VERSION ""

NS_ :

BS_:

BU_: BMS_Controller NF_Controller NF_Controllers

BO_ 3221225472 VECTOR__INDEPENDENT_SIG_MSG: 0 Vector__XXX
 SG_ BATT_SwVerSubMinorApp m0 : 24|8@1+ (1,0) [0|255] ""  NF_Controller
 SG_ BATT_SwVerMinorApp m0 : 16|8@1+ (1,0) [0|255] ""  NF_Controller
 SG_ BATT_SwVerMajorApp m0 : 8|8@1+ (1,0) [0|255] ""  NF_Controller
 SG_ BATT_HwVerApp m0 : 32|8@1+ (1,0) [0|255] ""  NF_Controller
 SG_ BATT_SwVerAbsCusApp m0 : 40|8@1+ (1,0) [0|255] ""  NF_Controller
 SG_ BATT_SwVerAbsIntApp m0 : 48|8@1+ (1,0) [0|255] ""  NF_Controller
 SG_ BATT_SwVerSubMinorBl m1 : 24|8@1+ (1,0) [0|255] ""  NF_Controller
 SG_ BATT_SwVerMinorBl m1 : 16|8@1+ (1,0) [0|255] ""  NF_Controller
 SG_ BATT_SwVerMajorBl m1 : 8|8@1+ (1,0) [0|255] ""  NF_Controller
 SG_ BATT_HwVerBl m1 : 32|8@1+ (1,0) [0|255] ""  NF_Controller
 SG_ BATT_SwVerAbsCusBl m1 : 40|8@1+ (1,0) [0|255] ""  NF_Controller
 SG_ BATT_SwVerAbsIntBl m1 : 48|8@1+ (1,0) [0|255] ""  NF_Controller
 SG_ BATT_SwVerSubMinorCal m2 : 24|8@1+ (1,0) [0|255] ""  NF_Controller
 SG_ BATT_SwVerMinorCal m2 : 16|8@1+ (1,0) [0|255] ""  NF_Controller
 SG_ BATT_SwVerMajorCal m2 : 8|8@1+ (1,0) [0|255] ""  NF_Controller
 SG_ BATT_HwVerCal m2 : 32|8@1+ (1,0) [0|255] ""  NF_Controller
 SG_ BATT_SwVerAbsCusCal m2 : 40|8@1+ (1,0) [0|255] ""  NF_Controller
 SG_ BATT_SwVerAbsIntCal m2 : 48|8@1+ (1,0) [0|255] ""  NF_Controller
 SG_ multiplexorvr M : 0|2@1+ (1,0) [0|2] ""  NF_Controllers
 SG_ BATT_Cnc_SOC_String_MinV : 58|2@1+ (1,0) [0|3] ""  NF_Controller
 SG_ BATT_Cnc_SOC_String_MaxV : 56|2@1+ (1,0) [0|3] ""  NF_Controller
 SG_ BATT_Cnc_SOC_String_AvgV : 21|2@1+ (1,0) [0|3] ""  NF_Controller
 SG_ BATT_Cnc_Energy_SystemV : 37|2@1+ (1,0) [0|3] ""  NF_Controller
 SG_ BATT_Cnc_Energy_System : 40|16@1+ (0.01,0) [0|655.35] "KWh"  NF_Controller
 SG_ BATT_Cnc_SOC_String_Avg : 0|8@1+ (0.4,0) [0|100] "%"  NF_Controller
 SG_ BATT_Cnc_SOC_String_Max : 24|8@1+ (0.4,0) [0|100] "%"  NF_Controller
 SG_ BATT_Cnc_SOC_String_Max_StrId : 32|5@1+ (1,101) [101|124] "Index"  NF_Controller
 SG_ BATT_Cnc_SOC_String_Min : 8|8@1+ (0.4,0) [0|100] "%"  NF_Controller
 SG_ BATT_Cnc_SOC_String_Min_StrId : 16|5@1+ (1,101) [101|124] "Index"  NF_Controller
 SG_ BATT_01_inhibitionPyroFuse m0 : 11|1@1+ (1,0) [0|1] ""  NF_Controller
 SG_ BATT_01_inhibitionRegen m0 : 10|1@1+ (1,0) [0|1] ""  NF_Controller
 SG_ BATT_01_inhibitionFullPower m0 : 9|1@1+ (1,0) [0|1] ""  NF_Controller
 SG_ BATT_01_inhibitionRampDown m0 : 8|1@1+ (1,0) [0|1] ""  NF_Controller
 SG_ BATT_01_inhibitionDriveEntry m0 : 3|1@1+ (1,0) [0|1] ""  NF_Controller
 SG_ BATT_01_inhibitionDrive m0 : 2|1@1+ (1,0) [0|1] ""  NF_Controller
 SG_ BATT_01_inhibitionCharge m0 : 1|1@1+ (1,0) [0|1] ""  NF_Controller
 SG_ BATT_01_inhibitionChargeEntry m0 : 0|1@1+ (1,0) [0|1] ""  NF_Controller
 SG_ BATT_02_inhibitionPyroFuse m1 : 11|1@1+ (1,0) [0|1] ""  NF_Controller
 SG_ BATT_02_inhibitionRegen m1 : 10|1@1+ (1,0) [0|1] ""  NF_Controller
 SG_ BATT_02_inhibitionFullPower m1 : 9|1@1+ (1,0) [0|1] ""  NF_Controller
 SG_ BATT_02_inhibitionRampDown m1 : 8|1@1+ (1,0) [0|1] ""  NF_Controller
 SG_ BATT_02_inhibitionDriveEntry m1 : 3|1@1+ (1,0) [0|1] ""  NF_Controller
 SG_ BATT_02_inhibitionDrive m1 : 2|1@1+ (1,0) [0|1] ""  NF_Controller
 SG_ BATT_02_inhibitionCharge m1 : 1|1@1+ (1,0) [0|1] ""  NF_Controller
 SG_ BATT_02_inhibitionChargeEntry m1 : 0|1@1+ (1,0) [0|1] ""  NF_Controller
 SG_ BATT_03_inhibitionPyroFuse m2 : 11|1@1+ (1,0) [0|1] ""  NF_Controller
 SG_ BATT_03_inhibitionRegen m2 : 10|1@1+ (1,0) [0|1] ""  NF_Controller
 SG_ BATT_03_inhibitionFullPower m2 : 9|1@1+ (1,0) [0|1] ""  NF_Controller
 SG_ BATT_03_inhibitionRampDown m2 : 8|1@1+ (1,0) [0|1] ""  NF_Controller
 SG_ BATT_03_inhibitionDriveEntry m2 : 3|1@1+ (1,0) [0|1] ""  NF_Controller
 SG_ BATT_03_inhibitionDrive m2 : 2|1@1+ (1,0) [0|1] ""  NF_Controller
 SG_ BATT_03_inhibitionCharge m2 : 1|1@1+ (1,0) [0|1] ""  NF_Controller
 SG_ BATT_03_inhibitionChargeEntry m2 : 0|1@1+ (1,0) [0|1] ""  NF_Controller
 SG_ BATT_04_inhibitionPyroFuse m3 : 11|1@1+ (1,0) [0|1] ""  NF_Controller
 SG_ BATT_04_inhibitionRegen m3 : 10|1@1+ (1,0) [0|1] ""  NF_Controller
 SG_ BATT_04_inhibitionFullPower m3 : 9|1@1+ (1,0) [0|1] ""  NF_Controller
 SG_ BATT_04_inhibitionRampDown m3 : 8|1@1+ (1,0) [0|1] ""  NF_Controller
 SG_ BATT_04_inhibitionDriveEntry m3 : 3|1@1+ (1,0) [0|1] ""  NF_Controller
 SG_ BATT_04_inhibitionDrive m3 : 2|1@1+ (1,0) [0|1] ""  NF_Controller
 SG_ BATT_04_inhibitionCharge m3 : 1|1@1+ (1,0) [0|1] ""  NF_Controller
 SG_ BATT_04_inhibitionChargeEntry m3 : 0|1@1+ (1,0) [0|1] ""  NF_Controller
 SG_ BATT_05_inhibitionPyroFuse m4 : 11|1@1+ (1,0) [0|1] ""  NF_Controller
 SG_ BATT_05_inhibitionRegen m4 : 10|1@1+ (1,0) [0|1] ""  NF_Controller
 SG_ BATT_05_inhibitionFullPower m4 : 9|1@1+ (1,0) [0|1] ""  NF_Controller
 SG_ BATT_05_inhibitionRampDown m4 : 8|1@1+ (1,0) [0|1] ""  NF_Controller
 SG_ BATT_05_inhibitionDriveEntry m4 : 3|1@1+ (1,0) [0|1] ""  NF_Controller
 SG_ BATT_05_inhibitionDrive m4 : 2|1@1+ (1,0) [0|1] ""  NF_Controller
 SG_ BATT_05_inhibitionCharge m4 : 1|1@1+ (1,0) [0|1] ""  NF_Controller
 SG_ BATT_05_inhibitionChargeEntry m4 : 0|1@1+ (1,0) [0|1] ""  NF_Controller
 SG_ BATT_06_inhibitionPyroFuse m5 : 11|1@1+ (1,0) [0|1] ""  NF_Controller
 SG_ BATT_06_inhibitionRegen m5 : 10|1@1+ (1,0) [0|1] ""  NF_Controller
 SG_ BATT_06_inhibitionFullPower m5 : 9|1@1+ (1,0) [0|1] ""  NF_Controller
 SG_ BATT_06_inhibitionRampDown m5 : 8|1@1+ (1,0) [0|1] ""  NF_Controller
 SG_ BATT_06_inhibitionDriveEntry m5 : 3|1@1+ (1,0) [0|1] ""  NF_Controller
 SG_ BATT_06_inhibitionDrive m5 : 2|1@1+ (1,0) [0|1] ""  NF_Controller
 SG_ BATT_06_inhibitionCharge m5 : 1|1@1+ (1,0) [0|1] ""  NF_Controller
 SG_ BATT_06_inhibitionChargeEntry m5 : 0|1@1+ (1,0) [0|1] ""  NF_Controller
 SG_ BATT_07_inhibitionPyroFuse m6 : 11|1@1+ (1,0) [0|1] ""  NF_Controller
 SG_ BATT_07_inhibitionRegen m6 : 10|1@1+ (1,0) [0|1] ""  NF_Controller
 SG_ BATT_07_inhibitionFullPower m6 : 9|1@1+ (1,0) [0|1] ""  NF_Controller
 SG_ BATT_07_inhibitionRampDown m6 : 8|1@1+ (1,0) [0|1] ""  NF_Controller
 SG_ BATT_07_inhibitionDriveEntry m6 : 3|1@1+ (1,0) [0|1] ""  NF_Controller
 SG_ BATT_07_inhibitionDrive m6 : 2|1@1+ (1,0) [0|1] ""  NF_Controller
 SG_ BATT_07_inhibitionCharge m6 : 1|1@1+ (1,0) [0|1] ""  NF_Controller
 SG_ BATT_07_inhibitionChargeEntry m6 : 0|1@1+ (1,0) [0|1] ""  NF_Controller
 SG_ BATT_08_inhibitionPyroFuse m7 : 11|1@1+ (1,0) [0|1] ""  NF_Controller
 SG_ BATT_08_inhibitionRegen m7 : 10|1@1+ (1,0) [0|1] ""  NF_Controller
 SG_ BATT_08_inhibitionFullPower m7 : 9|1@1+ (1,0) [0|1] ""  NF_Controller
 SG_ BATT_08_inhibitionRampDown m7 : 8|1@1+ (1,0) [0|1] ""  NF_Controller
 SG_ BATT_08_inhibitionDriveEntry m7 : 3|1@1+ (1,0) [0|1] ""  NF_Controller
 SG_ BATT_08_inhibitionDrive m7 : 2|1@1+ (1,0) [0|1] ""  NF_Controller
 SG_ BATT_08_inhibitionCharge m7 : 1|1@1+ (1,0) [0|1] ""  NF_Controller
 SG_ BATT_08_inhibitionChargeEntry m7 : 0|1@1+ (1,0) [0|1] ""  NF_Controller
 SG_ BATT_09_inhibitionPyroFuse m8 : 11|1@1+ (1,0) [0|1] ""  NF_Controller
 SG_ BATT_09_inhibitionRegen m8 : 10|1@1+ (1,0) [0|1] ""  NF_Controller
 SG_ BATT_09_inhibitionFullPower m8 : 9|1@1+ (1,0) [0|1] ""  NF_Controller
 SG_ BATT_09_inhibitionRampDown m8 : 8|1@1+ (1,0) [0|1] ""  NF_Controller
 SG_ BATT_09_inhibitionDriveEntry m8 : 3|1@1+ (1,0) [0|1] ""  NF_Controller
 SG_ BATT_09_inhibitionDrive m8 : 2|1@1+ (1,0) [0|1] ""  NF_Controller
 SG_ BATT_09_inhibitionCharge m8 : 1|1@1+ (1,0) [0|1] ""  NF_Controller
 SG_ BATT_09_inhibitionChargeEntry m8 : 0|1@1+ (1,0) [0|1] ""  NF_Controller
 SG_ BATT_10_inhibitionPyroFuse m9 : 11|1@1+ (1,0) [0|1] ""  NF_Controller
 SG_ BATT_10_inhibitionRegen m9 : 10|1@1+ (1,0) [0|1] ""  NF_Controller
 SG_ BATT_10_inhibitionFullPower m9 : 9|1@1+ (1,0) [0|1] ""  NF_Controller
 SG_ BATT_10_inhibitionRampDown m9 : 8|1@1+ (1,0) [0|1] ""  NF_Controller
 SG_ BATT_10_inhibitionDriveEntry m9 : 3|1@1+ (1,0) [0|1] ""  NF_Controller
 SG_ BATT_10_inhibitionDrive m9 : 2|1@1+ (1,0) [0|1] ""  NF_Controller
 SG_ BATT_10_inhibitionCharge m9 : 1|1@1+ (1,0) [0|1] ""  NF_Controller
 SG_ BATT_10_inhibitionChargeEntry m9 : 0|1@1+ (1,0) [0|1] ""  NF_Controller
 SG_ BATT_packInhMux M : 4|4@1+ (1,0) [0|15] ""  NF_Controller
 SG_ BATT_inhibitionRegen : 6|1@1+ (1,0) [0|1] ""  NF_Controller
 SG_ BATT_inhibitionFullPower : 5|1@1+ (1,0) [0|1] ""  NF_Controller
 SG_ BATT_inhibitionRampDown : 4|1@1+ (1,0) [0|1] ""  NF_Controller
 SG_ BATT_inhibitionDriveEntry : 3|1@1+ (1,0) [0|1] ""  NF_Controller
 SG_ BATT_inhibitionDrive : 2|1@1+ (1,0) [0|1] ""  NF_Controller
 SG_ BATT_inhibitionCharge : 1|1@1+ (1,0) [0|1] ""  NF_Controller
 SG_ BATT_inhibitionChargeEntry : 0|1@1+ (1,0) [0|1] ""  NF_Controller
 SG_ BATT_HVILvoltageError : 2|2@1+ (1,0) [0|3] ""  NF_Controller
 SG_ BATT_HVILcurrentReturnError : 0|2@1+ (1,0) [0|3] ""  NF_Controller
 SG_ BATT_PosFcContWelded : 14|2@1+ (1,0) [0|3] ""  NF_Controller
 SG_ BATT_PosFcContStuckOpen : 12|2@1+ (1,0) [0|3] ""  NF_Controller
 SG_ BATT_NegFcContWelded : 10|2@1+ (1,0) [0|3] ""  NF_Controller
 SG_ BATT_NegFcContStuckOpen : 8|2@1+ (1,0) [0|3] ""  NF_Controller
 SG_ BATT_IsospiBreak : 22|2@1+ (1,0) [0|3] ""  NF_Controller
 SG_ BATT_IsolationIntFault : 20|2@1+ (1,0) [0|3] ""  NF_Controller
 SG_ BATT_IsolationExtFault : 18|2@1+ (1,0) [0|3] ""  NF_Controller
 SG_ BATT_event_12v_filter_error : 16|2@1+ (1,0) [0|3] ""  NF_Controller
 SG_ BATT_event_hall_eff_hi_rang_err : 30|2@1+ (1,0) [0|3] ""  NF_Controller
 SG_ BATT_event_brick_volt_sns_open : 28|2@1+ (1,0) [0|3] ""  NF_Controller
 SG_ BATT_event_5v_error : 26|2@1+ (1,0) [0|3] ""  NF_Controller
 SG_ BATT_event_3_3_hot_error : 24|2@1+ (1,0) [0|3] ""  NF_Controller
 SG_ BATT_event_12v_input_error : 38|2@1+ (1,0) [0|3] ""  NF_Controller
 SG_ BATT_event_1_25v_error : 36|2@1+ (1,0) [0|3] ""  NF_Controller
 SG_ BATT_event_shunt_MIA : 34|2@1+ (1,0) [0|3] ""  NF_Controller
 SG_ BATT_event_SBC_int_reg_error : 32|2@1+ (1,0) [0|3] ""  NF_Controller
 SG_ BATT_event_pos_3_3v_analog_error : 46|2@1+ (1,0) [0|3] ""  NF_Controller
 SG_ BATT_event_outlt_clnt_thrm_open : 44|2@1+ (1,0) [0|3] ""  NF_Controller
 SG_ BATT_event_neg_3_3_analog_error : 42|2@1+ (1,0) [0|3] ""  NF_Controller
 SG_ BATT_event_inlet_clnt_thrm_open : 40|2@1+ (1,0) [0|3] ""  NF_Controller
 SG_ BATT_event_hall_eff_lo_rang_err : 54|2@1+ (1,0) [0|3] ""  NF_Controller
 SG_ BATT_event_outlt_clnt_thrm_short : 52|2@1+ (1,0) [0|3] ""  NF_Controller
 SG_ BATT_event_inlet_clnt_thrm_short : 50|2@1+ (1,0) [0|3] ""  NF_Controller
 SG_ BATT_event_3_3v_error : 48|2@1+ (1,0) [0|3] ""  NF_Controller
 SG_ BATT_SenseBrickImpHigh : 2|2@1+ (1,0) [0|3] ""  NF_Controller
 SG_ BATT_AFEfault : 0|2@1+ (1,0) [0|3] ""  NF_Controller
 SG_ BATT_AFEerror : 14|2@1+ (1,0) [0|3] ""  NF_Controller
 SG_ BATT_HostMIA : 12|2@1+ (1,0) [0|3] ""  NF_Controller
 SG_ BATT_TempAmbientOverSev : 10|2@1+ (1,0) [0|3] ""  NF_Controller
 SG_ BATT_TempAmbientOverMod : 8|2@1+ (1,0) [0|3] ""  NF_Controller
 SG_ BATT_TempAmbientOverWar : 22|2@1+ (1,0) [0|3] ""  NF_Controller
 SG_ BATT_AbnormReset : 20|2@1+ (1,0) [0|3] ""  NF_Controller
 SG_ BATT_SenseAuxVoltError : 18|2@1+ (1,0) [0|3] ""  NF_Controller
 SG_ BATT_CalibrationInvalid : 16|2@1+ (1,0) [0|3] ""  NF_Controller
 SG_ BATT_TaskLockup : 30|2@1+ (1,0) [0|3] ""  NF_Controller
 SG_ BATT_RAMover : 28|2@1+ (1,0) [0|3] ""  NF_Controller
 SG_ BATT_BrickOverdischarge : 26|2@1+ (1,0) [0|3] ""  NF_Controller
 SG_ BATT_BrickOvercharge : 24|2@1+ (1,0) [0|3] ""  NF_Controller
 SG_ BATT_vBrickImbalance : 38|2@1+ (1,0) [0|3] ""  NF_Controller
 SG_ BATT_TempBrickImbalance : 36|2@1+ (1,0) [0|3] ""  NF_Controller
 SG_ BATT_CapPackLow : 34|2@1+ (1,0) [0|3] ""  NF_Controller
 SG_ BATT_rBrickHigh : 32|2@1+ (1,0) [0|3] ""  NF_Controller
 SG_ BATT_PowerpackInsuffErr : 46|2@1+ (1,0) [0|3] ""  NF_Controller
 SG_ BATT_BrickSoftShort : 44|2@1+ (1,0) [0|3] ""  NF_Controller
 SG_ BATT_chargeUndercurrent : 42|2@1+ (1,0) [0|3] ""  NF_Controller
 SG_ BATT_HVILcurrentSourceError : 40|2@1+ (1,0) [0|3] ""  NF_Controller
 SG_ BATT_SRS : 54|2@1+ (1,0) [0|3] ""  NF_Controller
 SG_ BATT_IsolationExtWar : 52|2@1+ (1,0) [0|3] ""  NF_Controller
 SG_ BATT_IsolationIntWar : 50|2@1+ (1,0) [0|3] ""  NF_Controller
 SG_ BATT_PyroFuseBlown : 48|2@1+ (1,0) [0|3] ""  NF_Controller
 SG_ BATT_vBrickUnderSev : 62|2@1+ (1,0) [0|3] ""  NF_Controller
 SG_ BATT_chargePrechargeTimeout : 60|2@1+ (1,0) [0|3] ""  NF_Controller
 SG_ BATT_ModuleThermistorShort : 58|2@1+ (1,0) [0|3] ""  NF_Controller
 SG_ BATT_ModuleThermistorBroken : 56|2@1+ (1,0) [0|3] ""  NF_Controller
 SG_ BATT_vBrickOverSev : 2|2@1+ (1,0) [0|3] ""  NF_Controller
 SG_ BATT_vBrickOverMod : 0|2@1+ (1,0) [0|3] ""  NF_Controller
 SG_ BATT_vBrickOverWar : 14|2@1+ (1,0) [0|3] ""  NF_Controller
 SG_ BATT_HostQuiet : 12|2@1+ (1,0) [0|3] ""  NF_Controller
 SG_ BATT_vBrickUnderMod : 10|2@1+ (1,0) [0|3] ""  NF_Controller
 SG_ BATT_vBrickUnderWar : 8|2@1+ (1,0) [0|3] ""  NF_Controller
 SG_ BATT_TempModuleOverSev : 22|2@1+ (1,0) [0|3] ""  NF_Controller
 SG_ BATT_TempModuleOverMod : 20|2@1+ (1,0) [0|3] ""  NF_Controller
 SG_ BATT_TempModuleOverWar : 18|2@1+ (1,0) [0|3] ""  NF_Controller
 SG_ BATT_TempModuleUnderSev : 16|2@1+ (1,0) [0|3] ""  NF_Controller
 SG_ BATT_TempModuleUnderMod : 30|2@1+ (1,0) [0|3] ""  NF_Controller
 SG_ BATT_TempModuleUnderWar : 28|2@1+ (1,0) [0|3] ""  NF_Controller
 SG_ BATT_iOvercharge : 26|2@1+ (1,0) [0|3] ""  NF_Controller
 SG_ BATT_iOverdischarge : 24|2@1+ (1,0) [0|3] ""  NF_Controller
 SG_ BATT_iOverHardware : 38|2@1+ (1,0) [0|3] ""  NF_Controller
 SG_ BATT_PosDcContStuckOpen : 36|2@1+ (1,0) [0|3] ""  NF_Controller
 SG_ BATT_PosDcContWelded : 34|2@1+ (1,0) [0|3] ""  NF_Controller
 SG_ BATT_NegDcContStuckOpen : 32|2@1+ (1,0) [0|3] ""  NF_Controller
 SG_ BATT_NegDcContWelded : 46|2@1+ (1,0) [0|3] ""  NF_Controller
 SG_ BATT_PrechgTooFast : 44|2@1+ (1,0) [0|3] ""  NF_Controller
 SG_ BATT_PrechgContWelded : 42|2@1+ (1,0) [0|3] ""  NF_Controller
 SG_ BATT_PrechgTimeout : 40|2@1+ (1,0) [0|3] ""  NF_Controller
 SG_ BATT_PrechgContStuckOpen : 54|2@1+ (1,0) [0|3] ""  NF_Controller
 SG_ BATT_ModuleImbalance : 52|2@1+ (1,0) [0|3] ""  NF_Controller
 SG_ BATT_ModuleMIA : 50|2@1+ (1,0) [0|3] ""  NF_Controller
 SG_ BATT_SensePackVoltError : 48|2@1+ (1,0) [0|3] ""  NF_Controller
 SG_ BATT_SenseLoadVoltError : 62|2@1+ (1,0) [0|3] ""  NF_Controller
 SG_ BATT_SenseShuntError : 60|2@1+ (1,0) [0|3] ""  NF_Controller
 SG_ BATT_SenseFcVoltErrorr : 58|2@1+ (1,0) [0|3] ""  NF_Controller
 SG_ BATT_SenseBrickOpen : 56|2@1+ (1,0) [0|3] ""  NF_Controller
 SG_ BATT_01_vBrickOverSev m0 : 2|2@1+ (1,0) [0|3] ""  NF_Controller
 SG_ BATT_01_vBrickOverMod m0 : 0|2@1+ (1,0) [0|3] ""  NF_Controller
 SG_ BATT_01_vBrickOverWar m0 : 14|2@1+ (1,0) [0|3] ""  NF_Controller
 SG_ BATT_01_HostQuiet m0 : 12|2@1+ (1,0) [0|3] ""  NF_Controller
 SG_ BATT_01_vBrickUnderMod m0 : 10|2@1+ (1,0) [0|3] ""  NF_Controller
 SG_ BATT_01_vBrickUnderWar m0 : 8|2@1+ (1,0) [0|3] ""  NF_Controller
 SG_ BATT_01_TempModuleOverSev m0 : 22|2@1+ (1,0) [0|3] ""  NF_Controller
 SG_ BATT_01_TempModuleOverMod m0 : 20|2@1+ (1,0) [0|3] ""  NF_Controller
 SG_ BATT_01_TempModuleOverWar m0 : 18|2@1+ (1,0) [0|3] ""  NF_Controller
 SG_ BATT_01_TempModuleUnderSev m0 : 16|2@1+ (1,0) [0|3] ""  NF_Controller
 SG_ BATT_01_TempModuleUnderMod m0 : 30|2@1+ (1,0) [0|3] ""  NF_Controller
 SG_ BATT_01_TempModuleUnderWar m0 : 28|2@1+ (1,0) [0|3] ""  NF_Controller
 SG_ BATT_01_iOvercharge m0 : 26|2@1+ (1,0) [0|3] ""  NF_Controller
 SG_ BATT_01_iOverdischarge m0 : 24|2@1+ (1,0) [0|3] ""  NF_Controller
 SG_ BATT_01_iOverHardware m0 : 38|2@1+ (1,0) [0|3] ""  NF_Controller
 SG_ BATT_01_PosDcContStuckOpen m0 : 36|2@1+ (1,0) [0|3] ""  NF_Controller
 SG_ BATT_01_PosDcContWelded m0 : 34|2@1+ (1,0) [0|3] ""  NF_Controller
 SG_ BATT_01_NegDcContStuckOpen m0 : 32|2@1+ (1,0) [0|3] ""  NF_Controller
 SG_ BATT_01_NegDcContWelded m0 : 46|2@1+ (1,0) [0|3] ""  NF_Controller
 SG_ BATT_01_PrechgTooFast m0 : 44|2@1+ (1,0) [0|3] ""  NF_Controller
 SG_ BATT_01_PrechgContWelded m0 : 42|2@1+ (1,0) [0|3] ""  NF_Controller
 SG_ BATT_01_PrechgTimeout m0 : 40|2@1+ (1,0) [0|3] ""  NF_Controller
 SG_ BATT_01_PrechgContStuckOpen m0 : 54|2@1+ (1,0) [0|3] ""  NF_Controller
 SG_ BATT_01_ModuleImbalance m0 : 52|2@1+ (1,0) [0|3] ""  NF_Controller
 SG_ BATT_01_ModuleMIA m0 : 50|2@1+ (1,0) [0|3] ""  NF_Controller
 SG_ BATT_01_SensePackVoltError m0 : 48|2@1+ (1,0) [0|3] ""  NF_Controller
 SG_ BATT_01_SenseLoadVoltError m0 : 62|2@1+ (1,0) [0|3] ""  NF_Controller
 SG_ BATT_01_SenseShuntError m0 : 60|2@1+ (1,0) [0|3] ""  NF_Controller
 SG_ BATT_01_SenseFcVoltErrorr m0 : 58|2@1+ (1,0) [0|3] ""  NF_Controller
 SG_ BATT_01_SenseBrickOpen m0 : 56|2@1+ (1,0) [0|3] ""  NF_Controller
 SG_ BATT_02_vBrickOverSev m1 : 2|2@1+ (1,0) [0|3] ""  NF_Controller
 SG_ BATT_02_vBrickOverMod m1 : 0|2@1+ (1,0) [0|3] ""  NF_Controller
 SG_ BATT_02_vBrickOverWar m1 : 14|2@1+ (1,0) [0|3] ""  NF_Controller
 SG_ BATT_02_HostQuiet m1 : 12|2@1+ (1,0) [0|3] ""  NF_Controller
 SG_ BATT_02_vBrickUnderMod m1 : 10|2@1+ (1,0) [0|3] ""  NF_Controller
 SG_ BATT_02_vBrickUnderWar m1 : 8|2@1+ (1,0) [0|3] ""  NF_Controller
 SG_ BATT_02_TempModuleOverSev m1 : 22|2@1+ (1,0) [0|3] ""  NF_Controller
 SG_ BATT_02_TempModuleOverMod m1 : 20|2@1+ (1,0) [0|3] ""  NF_Controller
 SG_ BATT_02_TempModuleOverWar m1 : 18|2@1+ (1,0) [0|3] ""  NF_Controller
 SG_ BATT_02_TempModuleUnderSev m1 : 16|2@1+ (1,0) [0|3] ""  NF_Controller
 SG_ BATT_02_TempModuleUnderMod m1 : 30|2@1+ (1,0) [0|3] ""  NF_Controller
 SG_ BATT_02_TempModuleUnderWar m1 : 28|2@1+ (1,0) [0|3] ""  NF_Controller
 SG_ BATT_02_iOvercharge m1 : 26|2@1+ (1,0) [0|3] ""  NF_Controller
 SG_ BATT_02_iOverdischarge m1 : 24|2@1+ (1,0) [0|3] ""  NF_Controller
 SG_ BATT_02_iOverHardware m1 : 38|2@1+ (1,0) [0|3] ""  NF_Controller
 SG_ BATT_02_PosDcContStuckOpen m1 : 36|2@1+ (1,0) [0|3] ""  NF_Controller
 SG_ BATT_02_PosDcContWelded m1 : 34|2@1+ (1,0) [0|3] ""  NF_Controller
 SG_ BATT_02_NegDcContStuckOpen m1 : 32|2@1+ (1,0) [0|3] ""  NF_Controller
 SG_ BATT_02_NegDcContWelded m1 : 46|2@1+ (1,0) [0|3] ""  NF_Controller
 SG_ BATT_02_PrechgTooFast m1 : 44|2@1+ (1,0) [0|3] ""  NF_Controller
 SG_ BATT_02_PrechgContWelded m1 : 42|2@1+ (1,0) [0|3] ""  NF_Controller
 SG_ BATT_02_PrechgTimeout m1 : 40|2@1+ (1,0) [0|3] ""  NF_Controller
 SG_ BATT_02_PrechgContStuckOpen m1 : 54|2@1+ (1,0) [0|3] ""  NF_Controller
 SG_ BATT_02_ModuleImbalance m1 : 52|2@1+ (1,0) [0|3] ""  NF_Controller
 SG_ BATT_02_ModuleMIA m1 : 50|2@1+ (1,0) [0|3] ""  NF_Controller
 SG_ BATT_02_SensePackVoltError m1 : 48|2@1+ (1,0) [0|3] ""  NF_Controller
 SG_ BATT_02_SenseLoadVoltError m1 : 62|2@1+ (1,0) [0|3] ""  NF_Controller
 SG_ BATT_02_SenseShuntError m1 : 60|2@1+ (1,0) [0|3] ""  NF_Controller
 SG_ BATT_02_SenseFcVoltErrorr m1 : 58|2@1+ (1,0) [0|3] ""  NF_Controller
 SG_ BATT_02_SenseBrickOpen m1 : 56|2@1+ (1,0) [0|3] ""  NF_Controller
 SG_ BATT_03_vBrickOverSev m2 : 2|2@1+ (1,0) [0|3] ""  NF_Controller
 SG_ BATT_03_vBrickOverMod m2 : 0|2@1+ (1,0) [0|3] ""  NF_Controller
 SG_ BATT_03_vBrickOverWar m2 : 14|2@1+ (1,0) [0|3] ""  NF_Controller
 SG_ BATT_03_HostQuiet m2 : 12|2@1+ (1,0) [0|3] ""  NF_Controller
 SG_ BATT_03_vBrickUnderMod m2 : 10|2@1+ (1,0) [0|3] ""  NF_Controller
 SG_ BATT_03_vBrickUnderWar m2 : 8|2@1+ (1,0) [0|3] ""  NF_Controller
 SG_ BATT_03_TempModuleOverSev m2 : 22|2@1+ (1,0) [0|3] ""  NF_Controller
 SG_ BATT_03_TempModuleOverMod m2 : 20|2@1+ (1,0) [0|3] ""  NF_Controller
 SG_ BATT_03_TempModuleOverWar m2 : 18|2@1+ (1,0) [0|3] ""  NF_Controller
 SG_ BATT_03_TempModuleUnderSev m2 : 16|2@1+ (1,0) [0|3] ""  NF_Controller
 SG_ BATT_03_TempModuleUnderMod m2 : 30|2@1+ (1,0) [0|3] ""  NF_Controller
 SG_ BATT_03_TempModuleUnderWar m2 : 28|2@1+ (1,0) [0|3] ""  NF_Controller
 SG_ BATT_03_iOvercharge m2 : 26|2@1+ (1,0) [0|3] ""  NF_Controller
 SG_ BATT_03_iOverdischarge m2 : 24|2@1+ (1,0) [0|3] ""  NF_Controller
 SG_ BATT_03_iOverHardware m2 : 38|2@1+ (1,0) [0|3] ""  NF_Controller
 SG_ BATT_03_PosDcContStuckOpen m2 : 36|2@1+ (1,0) [0|3] ""  NF_Controller
 SG_ BATT_03_PosDcContWelded m2 : 34|2@1+ (1,0) [0|3] ""  NF_Controller
 SG_ BATT_03_NegDcContStuckOpen m2 : 32|2@1+ (1,0) [0|3] ""  NF_Controller
 SG_ BATT_03_NegDcContWelded m2 : 46|2@1+ (1,0) [0|3] ""  NF_Controller
 SG_ BATT_03_PrechgTooFast m2 : 44|2@1+ (1,0) [0|3] ""  NF_Controller
 SG_ BATT_03_PrechgContWelded m2 : 42|2@1+ (1,0) [0|3] ""  NF_Controller
 SG_ BATT_03_PrechgTimeout m2 : 40|2@1+ (1,0) [0|3] ""  NF_Controller
 SG_ BATT_03_PrechgContStuckOpen m2 : 54|2@1+ (1,0) [0|3] ""  NF_Controller
 SG_ BATT_03_ModuleImbalance m2 : 52|2@1+ (1,0) [0|3] ""  NF_Controller
 SG_ BATT_03_ModuleMIA m2 : 50|2@1+ (1,0) [0|3] ""  NF_Controller
 SG_ BATT_03_SensePackVoltError m2 : 48|2@1+ (1,0) [0|3] ""  NF_Controller
 SG_ BATT_03_SenseLoadVoltError m2 : 62|2@1+ (1,0) [0|3] ""  NF_Controller
 SG_ BATT_03_SenseShuntError m2 : 60|2@1+ (1,0) [0|3] ""  NF_Controller
 SG_ BATT_03_SenseFcVoltErrorr m2 : 58|2@1+ (1,0) [0|3] ""  NF_Controller
 SG_ BATT_03_SenseBrickOpen m2 : 56|2@1+ (1,0) [0|3] ""  NF_Controller
 SG_ BATT_04_vBrickOverSev m3 : 2|2@1+ (1,0) [0|3] ""  NF_Controller
 SG_ BATT_04_vBrickOverMod m3 : 0|2@1+ (1,0) [0|3] ""  NF_Controller
 SG_ BATT_04_vBrickOverWar m3 : 14|2@1+ (1,0) [0|3] ""  NF_Controller
 SG_ BATT_04_HostQuiet m3 : 12|2@1+ (1,0) [0|3] ""  NF_Controller
 SG_ BATT_04_vBrickUnderMod m3 : 10|2@1+ (1,0) [0|3] ""  NF_Controller
 SG_ BATT_04_vBrickUnderWar m3 : 8|2@1+ (1,0) [0|3] ""  NF_Controller
 SG_ BATT_04_TempModuleOverSev m3 : 22|2@1+ (1,0) [0|3] ""  NF_Controller
 SG_ BATT_04_TempModuleOverMod m3 : 20|2@1+ (1,0) [0|3] ""  NF_Controller
 SG_ BATT_04_TempModuleOverWar m3 : 18|2@1+ (1,0) [0|3] ""  NF_Controller
 SG_ BATT_04_TempModuleUnderSev m3 : 16|2@1+ (1,0) [0|3] ""  NF_Controller
 SG_ BATT_04_TempModuleUnderMod m3 : 30|2@1+ (1,0) [0|3] ""  NF_Controller
 SG_ BATT_04_TempModuleUnderWar m3 : 28|2@1+ (1,0) [0|3] ""  NF_Controller
 SG_ BATT_04_iOvercharge m3 : 26|2@1+ (1,0) [0|3] ""  NF_Controller
 SG_ BATT_04_iOverdischarge m3 : 24|2@1+ (1,0) [0|3] ""  NF_Controller
 SG_ BATT_04_iOverHardware m3 : 38|2@1+ (1,0) [0|3] ""  NF_Controller
 SG_ BATT_04_PosDcContStuckOpen m3 : 36|2@1+ (1,0) [0|3] ""  NF_Controller
 SG_ BATT_04_PosDcContWelded m3 : 34|2@1+ (1,0) [0|3] ""  NF_Controller
 SG_ BATT_04_NegDcContStuckOpen m3 : 32|2@1+ (1,0) [0|3] ""  NF_Controller
 SG_ BATT_04_NegDcContWelded m3 : 46|2@1+ (1,0) [0|3] ""  NF_Controller
 SG_ BATT_04_PrechgTooFast m3 : 44|2@1+ (1,0) [0|3] ""  NF_Controller
 SG_ BATT_04_PrechgContWelded m3 : 42|2@1+ (1,0) [0|3] ""  NF_Controller
 SG_ BATT_04_PrechgTimeout m3 : 40|2@1+ (1,0) [0|3] ""  NF_Controller
 SG_ BATT_04_PrechgContStuckOpen m3 : 54|2@1+ (1,0) [0|3] ""  NF_Controller
 SG_ BATT_04_ModuleImbalance m3 : 52|2@1+ (1,0) [0|3] ""  NF_Controller
 SG_ BATT_04_ModuleMIA m3 : 50|2@1+ (1,0) [0|3] ""  NF_Controller
 SG_ BATT_04_SensePackVoltError m3 : 48|2@1+ (1,0) [0|3] ""  NF_Controller
 SG_ BATT_04_SenseLoadVoltError m3 : 62|2@1+ (1,0) [0|3] ""  NF_Controller
 SG_ BATT_04_SenseShuntError m3 : 60|2@1+ (1,0) [0|3] ""  NF_Controller
 SG_ BATT_04_SenseFcVoltErrorr m3 : 58|2@1+ (1,0) [0|3] ""  NF_Controller
 SG_ BATT_04_SenseBrickOpen m3 : 56|2@1+ (1,0) [0|3] ""  NF_Controller
 SG_ BATT_05_vBrickOverSev m4 : 2|2@1+ (1,0) [0|3] ""  NF_Controller
 SG_ BATT_05_vBrickOverMod m4 : 0|2@1+ (1,0) [0|3] ""  NF_Controller
 SG_ BATT_05_vBrickOverWar m4 : 14|2@1+ (1,0) [0|3] ""  NF_Controller
 SG_ BATT_05_HostQuiet m4 : 12|2@1+ (1,0) [0|3] ""  NF_Controller
 SG_ BATT_05_vBrickUnderMod m4 : 10|2@1+ (1,0) [0|3] ""  NF_Controller
 SG_ BATT_05_vBrickUnderWar m4 : 8|2@1+ (1,0) [0|3] ""  NF_Controller
 SG_ BATT_05_TempModuleOverSev m4 : 22|2@1+ (1,0) [0|3] ""  NF_Controller
 SG_ BATT_05_TempModuleOverMod m4 : 20|2@1+ (1,0) [0|3] ""  NF_Controller
 SG_ BATT_05_TempModuleOverWar m4 : 18|2@1+ (1,0) [0|3] ""  NF_Controller
 SG_ BATT_05_TempModuleUnderSev m4 : 16|2@1+ (1,0) [0|3] ""  NF_Controller
 SG_ BATT_05_TempModuleUnderMod m4 : 30|2@1+ (1,0) [0|3] ""  NF_Controller
 SG_ BATT_05_TempModuleUnderWar m4 : 28|2@1+ (1,0) [0|3] ""  NF_Controller
 SG_ BATT_05_iOvercharge m4 : 26|2@1+ (1,0) [0|3] ""  NF_Controller
 SG_ BATT_05_iOverdischarge m4 : 24|2@1+ (1,0) [0|3] ""  NF_Controller
 SG_ BATT_05_iOverHardware m4 : 38|2@1+ (1,0) [0|3] ""  NF_Controller
 SG_ BATT_05_PosDcContStuckOpen m4 : 36|2@1+ (1,0) [0|3] ""  NF_Controller
 SG_ BATT_05_PosDcContWelded m4 : 34|2@1+ (1,0) [0|3] ""  NF_Controller
 SG_ BATT_05_NegDcContStuckOpen m4 : 32|2@1+ (1,0) [0|3] ""  NF_Controller
 SG_ BATT_05_NegDcContWelded m4 : 46|2@1+ (1,0) [0|3] ""  NF_Controller
 SG_ BATT_05_PrechgTooFast m4 : 44|2@1+ (1,0) [0|3] ""  NF_Controller
 SG_ BATT_05_PrechgContWelded m4 : 42|2@1+ (1,0) [0|3] ""  NF_Controller
 SG_ BATT_05_PrechgTimeout m4 : 40|2@1+ (1,0) [0|3] ""  NF_Controller
 SG_ BATT_05_PrechgContStuckOpen m4 : 54|2@1+ (1,0) [0|3] ""  NF_Controller
 SG_ BATT_05_ModuleImbalance m4 : 52|2@1+ (1,0) [0|3] ""  NF_Controller
 SG_ BATT_05_ModuleMIA m4 : 50|2@1+ (1,0) [0|3] ""  NF_Controller
 SG_ BATT_05_SensePackVoltError m4 : 48|2@1+ (1,0) [0|3] ""  NF_Controller
 SG_ BATT_05_SenseLoadVoltError m4 : 62|2@1+ (1,0) [0|3] ""  NF_Controller
 SG_ BATT_05_SenseShuntError m4 : 60|2@1+ (1,0) [0|3] ""  NF_Controller
 SG_ BATT_05_SenseFcVoltErrorr m4 : 58|2@1+ (1,0) [0|3] ""  NF_Controller
 SG_ BATT_05_SenseBrickOpen m4 : 56|2@1+ (1,0) [0|3] ""  NF_Controller
 SG_ BATT_06_vBrickOverSev m5 : 2|2@1+ (1,0) [0|3] ""  NF_Controller
 SG_ BATT_06_vBrickOverMod m5 : 0|2@1+ (1,0) [0|3] ""  NF_Controller
 SG_ BATT_06_vBrickOverWar m5 : 14|2@1+ (1,0) [0|3] ""  NF_Controller
 SG_ BATT_06_HostQuiet m5 : 12|2@1+ (1,0) [0|3] ""  NF_Controller
 SG_ BATT_06_vBrickUnderMod m5 : 10|2@1+ (1,0) [0|3] ""  NF_Controller
 SG_ BATT_06_vBrickUnderWar m5 : 8|2@1+ (1,0) [0|3] ""  NF_Controller
 SG_ BATT_06_TempModuleOverSev m5 : 22|2@1+ (1,0) [0|3] ""  NF_Controller
 SG_ BATT_06_TempModuleOverMod m5 : 20|2@1+ (1,0) [0|3] ""  NF_Controller
 SG_ BATT_06_TempModuleOverWar m5 : 18|2@1+ (1,0) [0|3] ""  NF_Controller
 SG_ BATT_06_TempModuleUnderSev m5 : 16|2@1+ (1,0) [0|3] ""  NF_Controller
 SG_ BATT_06_TempModuleUnderMod m5 : 30|2@1+ (1,0) [0|3] ""  NF_Controller
 SG_ BATT_06_TempModuleUnderWar m5 : 28|2@1+ (1,0) [0|3] ""  NF_Controller
 SG_ BATT_06_iOvercharge m5 : 26|2@1+ (1,0) [0|3] ""  NF_Controller
 SG_ BATT_06_iOverdischarge m5 : 24|2@1+ (1,0) [0|3] ""  NF_Controller
 SG_ BATT_06_iOverHardware m5 : 38|2@1+ (1,0) [0|3] ""  NF_Controller
 SG_ BATT_06_PosDcContStuckOpen m5 : 36|2@1+ (1,0) [0|3] ""  NF_Controller
 SG_ BATT_06_PosDcContWelded m5 : 34|2@1+ (1,0) [0|3] ""  NF_Controller
 SG_ BATT_06_NegDcContStuckOpen m5 : 32|2@1+ (1,0) [0|3] ""  NF_Controller
 SG_ BATT_06_NegDcContWelded m5 : 46|2@1+ (1,0) [0|3] ""  NF_Controller
 SG_ BATT_06_PrechgTooFast m5 : 44|2@1+ (1,0) [0|3] ""  NF_Controller
 SG_ BATT_06_PrechgContWelded m5 : 42|2@1+ (1,0) [0|3] ""  NF_Controller
 SG_ BATT_06_PrechgTimeout m5 : 40|2@1+ (1,0) [0|3] ""  NF_Controller
 SG_ BATT_06_PrechgContStuckOpen m5 : 54|2@1+ (1,0) [0|3] ""  NF_Controller
 SG_ BATT_06_ModuleImbalance m5 : 52|2@1+ (1,0) [0|3] ""  NF_Controller
 SG_ BATT_06_ModuleMIA m5 : 50|2@1+ (1,0) [0|3] ""  NF_Controller
 SG_ BATT_06_SensePackVoltError m5 : 48|2@1+ (1,0) [0|3] ""  NF_Controller
 SG_ BATT_06_SenseLoadVoltError m5 : 62|2@1+ (1,0) [0|3] ""  NF_Controller
 SG_ BATT_06_SenseShuntError m5 : 60|2@1+ (1,0) [0|3] ""  NF_Controller
 SG_ BATT_06_SenseFcVoltErrorr m5 : 58|2@1+ (1,0) [0|3] ""  NF_Controller
 SG_ BATT_06_SenseBrickOpen m5 : 56|2@1+ (1,0) [0|3] ""  NF_Controller
 SG_ BATT_07_vBrickOverSev m6 : 2|2@1+ (1,0) [0|3] ""  NF_Controller
 SG_ BATT_07_vBrickOverMod m6 : 0|2@1+ (1,0) [0|3] ""  NF_Controller
 SG_ BATT_07_vBrickOverWar m6 : 14|2@1+ (1,0) [0|3] ""  NF_Controller
 SG_ BATT_07_HostQuiet m6 : 12|2@1+ (1,0) [0|3] ""  NF_Controller
 SG_ BATT_07_vBrickUnderMod m6 : 10|2@1+ (1,0) [0|3] ""  NF_Controller
 SG_ BATT_07_vBrickUnderWar m6 : 8|2@1+ (1,0) [0|3] ""  NF_Controller
 SG_ BATT_07_TempModuleOverSev m6 : 22|2@1+ (1,0) [0|3] ""  NF_Controller
 SG_ BATT_07_TempModuleOverMod m6 : 20|2@1+ (1,0) [0|3] ""  NF_Controller
 SG_ BATT_07_TempModuleOverWar m6 : 18|2@1+ (1,0) [0|3] ""  NF_Controller
 SG_ BATT_07_TempModuleUnderSev m6 : 16|2@1+ (1,0) [0|3] ""  NF_Controller
 SG_ BATT_07_TempModuleUnderMod m6 : 30|2@1+ (1,0) [0|3] ""  NF_Controller
 SG_ BATT_07_TempModuleUnderWar m6 : 28|2@1+ (1,0) [0|3] ""  NF_Controller
 SG_ BATT_07_iOvercharge m6 : 26|2@1+ (1,0) [0|3] ""  NF_Controller
 SG_ BATT_07_iOverdischarge m6 : 24|2@1+ (1,0) [0|3] ""  NF_Controller
 SG_ BATT_07_iOverHardware m6 : 38|2@1+ (1,0) [0|3] ""  NF_Controller
 SG_ BATT_07_PosDcContStuckOpen m6 : 36|2@1+ (1,0) [0|3] ""  NF_Controller
 SG_ BATT_07_PosDcContWelded m6 : 34|2@1+ (1,0) [0|3] ""  NF_Controller
 SG_ BATT_07_NegDcContStuckOpen m6 : 32|2@1+ (1,0) [0|3] ""  NF_Controller
 SG_ BATT_07_NegDcContWelded m6 : 46|2@1+ (1,0) [0|3] ""  NF_Controller
 SG_ BATT_07_PrechgTooFast m6 : 44|2@1+ (1,0) [0|3] ""  NF_Controller
 SG_ BATT_07_PrechgContWelded m6 : 42|2@1+ (1,0) [0|3] ""  NF_Controller
 SG_ BATT_07_PrechgTimeout m6 : 40|2@1+ (1,0) [0|3] ""  NF_Controller
 SG_ BATT_07_PrechgContStuckOpen m6 : 54|2@1+ (1,0) [0|3] ""  NF_Controller
 SG_ BATT_07_ModuleImbalance m6 : 52|2@1+ (1,0) [0|3] ""  NF_Controller
 SG_ BATT_07_ModuleMIA m6 : 50|2@1+ (1,0) [0|3] ""  NF_Controller
 SG_ BATT_07_SensePackVoltError m6 : 48|2@1+ (1,0) [0|3] ""  NF_Controller
 SG_ BATT_07_SenseLoadVoltError m6 : 62|2@1+ (1,0) [0|3] ""  NF_Controller
 SG_ BATT_07_SenseShuntError m6 : 60|2@1+ (1,0) [0|3] ""  NF_Controller
 SG_ BATT_07_SenseFcVoltErrorr m6 : 58|2@1+ (1,0) [0|3] ""  NF_Controller
 SG_ BATT_07_SenseBrickOpen m6 : 56|2@1+ (1,0) [0|3] ""  NF_Controller
 SG_ BATT_08_vBrickOverSev m7 : 2|2@1+ (1,0) [0|3] ""  NF_Controller
 SG_ BATT_08_vBrickOverMod m7 : 0|2@1+ (1,0) [0|3] ""  NF_Controller
 SG_ BATT_08_vBrickOverWar m7 : 14|2@1+ (1,0) [0|3] ""  NF_Controller
 SG_ BATT_08_HostQuiet m7 : 12|2@1+ (1,0) [0|3] ""  NF_Controller
 SG_ BATT_08_vBrickUnderMod m7 : 10|2@1+ (1,0) [0|3] ""  NF_Controller
 SG_ BATT_08_vBrickUnderWar m7 : 8|2@1+ (1,0) [0|3] ""  NF_Controller
 SG_ BATT_08_TempModuleOverSev m7 : 22|2@1+ (1,0) [0|3] ""  NF_Controller
 SG_ BATT_08_TempModuleOverMod m7 : 20|2@1+ (1,0) [0|3] ""  NF_Controller
 SG_ BATT_08_TempModuleOverWar m7 : 18|2@1+ (1,0) [0|3] ""  NF_Controller
 SG_ BATT_08_TempModuleUnderSev m7 : 16|2@1+ (1,0) [0|3] ""  NF_Controller
 SG_ BATT_08_TempModuleUnderMod m7 : 30|2@1+ (1,0) [0|3] ""  NF_Controller
 SG_ BATT_08_TempModuleUnderWar m7 : 28|2@1+ (1,0) [0|3] ""  NF_Controller
 SG_ BATT_08_iOvercharge m7 : 26|2@1+ (1,0) [0|3] ""  NF_Controller
 SG_ BATT_08_iOverdischarge m7 : 24|2@1+ (1,0) [0|3] ""  NF_Controller
 SG_ BATT_08_iOverHardware m7 : 38|2@1+ (1,0) [0|3] ""  NF_Controller
 SG_ BATT_08_PosDcContStuckOpen m7 : 36|2@1+ (1,0) [0|3] ""  NF_Controller
 SG_ BATT_08_PosDcContWelded m7 : 34|2@1+ (1,0) [0|3] ""  NF_Controller
 SG_ BATT_08_NegDcContStuckOpen m7 : 32|2@1+ (1,0) [0|3] ""  NF_Controller
 SG_ BATT_08_NegDcContWelded m7 : 46|2@1+ (1,0) [0|3] ""  NF_Controller
 SG_ BATT_08_PrechgTooFast m7 : 44|2@1+ (1,0) [0|3] ""  NF_Controller
 SG_ BATT_08_PrechgContWelded m7 : 42|2@1+ (1,0) [0|3] ""  NF_Controller
 SG_ BATT_08_PrechgTimeout m7 : 40|2@1+ (1,0) [0|3] ""  NF_Controller
 SG_ BATT_08_PrechgContStuckOpen m7 : 54|2@1+ (1,0) [0|3] ""  NF_Controller
 SG_ BATT_08_ModuleImbalance m7 : 52|2@1+ (1,0) [0|3] ""  NF_Controller
 SG_ BATT_08_ModuleMIA m7 : 50|2@1+ (1,0) [0|3] ""  NF_Controller
 SG_ BATT_08_SensePackVoltError m7 : 48|2@1+ (1,0) [0|3] ""  NF_Controller
 SG_ BATT_08_SenseLoadVoltError m7 : 62|2@1+ (1,0) [0|3] ""  NF_Controller
 SG_ BATT_08_SenseShuntError m7 : 60|2@1+ (1,0) [0|3] ""  NF_Controller
 SG_ BATT_08_SenseFcVoltErrorr m7 : 58|2@1+ (1,0) [0|3] ""  NF_Controller
 SG_ BATT_08_SenseBrickOpen m7 : 56|2@1+ (1,0) [0|3] ""  NF_Controller
 SG_ BATT_09_vBrickOverSev m8 : 2|2@1+ (1,0) [0|3] ""  NF_Controller
 SG_ BATT_09_vBrickOverMod m8 : 0|2@1+ (1,0) [0|3] ""  NF_Controller
 SG_ BATT_09_vBrickOverWar m8 : 14|2@1+ (1,0) [0|3] ""  NF_Controller
 SG_ BATT_09_HostQuiet m8 : 12|2@1+ (1,0) [0|3] ""  NF_Controller
 SG_ BATT_09_vBrickUnderMod m8 : 10|2@1+ (1,0) [0|3] ""  NF_Controller
 SG_ BATT_09_vBrickUnderWar m8 : 8|2@1+ (1,0) [0|3] ""  NF_Controller
 SG_ BATT_09_TempModuleOverSev m8 : 22|2@1+ (1,0) [0|3] ""  NF_Controller
 SG_ BATT_09_TempModuleOverMod m8 : 20|2@1+ (1,0) [0|3] ""  NF_Controller
 SG_ BATT_09_TempModuleOverWar m8 : 18|2@1+ (1,0) [0|3] ""  NF_Controller
 SG_ BATT_09_TempModuleUnderSev m8 : 16|2@1+ (1,0) [0|3] ""  NF_Controller
 SG_ BATT_09_TempModuleUnderMod m8 : 30|2@1+ (1,0) [0|3] ""  NF_Controller
 SG_ BATT_09_TempModuleUnderWar m8 : 28|2@1+ (1,0) [0|3] ""  NF_Controller
 SG_ BATT_09_iOvercharge m8 : 26|2@1+ (1,0) [0|3] ""  NF_Controller
 SG_ BATT_09_iOverdischarge m8 : 24|2@1+ (1,0) [0|3] ""  NF_Controller
 SG_ BATT_09_iOverHardware m8 : 38|2@1+ (1,0) [0|3] ""  NF_Controller
 SG_ BATT_09_PosDcContStuckOpen m8 : 36|2@1+ (1,0) [0|3] ""  NF_Controller
 SG_ BATT_09_PosDcContWelded m8 : 34|2@1+ (1,0) [0|3] ""  NF_Controller
 SG_ BATT_09_NegDcContStuckOpen m8 : 32|2@1+ (1,0) [0|3] ""  NF_Controller
 SG_ BATT_09_NegDcContWelded m8 : 46|2@1+ (1,0) [0|3] ""  NF_Controller
 SG_ BATT_09_PrechgTooFast m8 : 44|2@1+ (1,0) [0|3] ""  NF_Controller
 SG_ BATT_09_PrechgContWelded m8 : 42|2@1+ (1,0) [0|3] ""  NF_Controller
 SG_ BATT_09_PrechgTimeout m8 : 40|2@1+ (1,0) [0|3] ""  NF_Controller
 SG_ BATT_09_PrechgContStuckOpen m8 : 54|2@1+ (1,0) [0|3] ""  NF_Controller
 SG_ BATT_09_ModuleImbalance m8 : 52|2@1+ (1,0) [0|3] ""  NF_Controller
 SG_ BATT_09_ModuleMIA m8 : 50|2@1+ (1,0) [0|3] ""  NF_Controller
 SG_ BATT_09_SensePackVoltError m8 : 48|2@1+ (1,0) [0|3] ""  NF_Controller
 SG_ BATT_09_SenseLoadVoltError m8 : 62|2@1+ (1,0) [0|3] ""  NF_Controller
 SG_ BATT_09_SenseShuntError m8 : 60|2@1+ (1,0) [0|3] ""  NF_Controller
 SG_ BATT_09_SenseFcVoltErrorr m8 : 58|2@1+ (1,0) [0|3] ""  NF_Controller
 SG_ BATT_09_SenseBrickOpen m8 : 56|2@1+ (1,0) [0|3] ""  NF_Controller
 SG_ BATT_10_vBrickOverSev m9 : 2|2@1+ (1,0) [0|3] ""  NF_Controller
 SG_ BATT_10_vBrickOverMod m9 : 0|2@1+ (1,0) [0|3] ""  NF_Controller
 SG_ BATT_10_vBrickOverWar m9 : 14|2@1+ (1,0) [0|3] ""  NF_Controller
 SG_ BATT_10_HostQuiet m9 : 12|2@1+ (1,0) [0|3] ""  NF_Controller
 SG_ BATT_10_vBrickUnderMod m9 : 10|2@1+ (1,0) [0|3] ""  NF_Controller
 SG_ BATT_10_vBrickUnderWar m9 : 8|2@1+ (1,0) [0|3] ""  NF_Controller
 SG_ BATT_10_TempModuleOverSev m9 : 22|2@1+ (1,0) [0|3] ""  NF_Controller
 SG_ BATT_10_TempModuleOverMod m9 : 20|2@1+ (1,0) [0|3] ""  NF_Controller
 SG_ BATT_10_TempModuleOverWar m9 : 18|2@1+ (1,0) [0|3] ""  NF_Controller
 SG_ BATT_10_TempModuleUnderSev m9 : 16|2@1+ (1,0) [0|3] ""  NF_Controller
 SG_ BATT_10_TempModuleUnderMod m9 : 30|2@1+ (1,0) [0|3] ""  NF_Controller
 SG_ BATT_10_TempModuleUnderWar m9 : 28|2@1+ (1,0) [0|3] ""  NF_Controller
 SG_ BATT_10_iOvercharge m9 : 26|2@1+ (1,0) [0|3] ""  NF_Controller
 SG_ BATT_10_iOverdischarge m9 : 24|2@1+ (1,0) [0|3] ""  NF_Controller
 SG_ BATT_10_iOverHardware m9 : 38|2@1+ (1,0) [0|3] ""  NF_Controller
 SG_ BATT_10_PosDcContStuckOpen m9 : 36|2@1+ (1,0) [0|3] ""  NF_Controller
 SG_ BATT_10_PosDcContWelded m9 : 34|2@1+ (1,0) [0|3] ""  NF_Controller
 SG_ BATT_10_NegDcContStuckOpen m9 : 32|2@1+ (1,0) [0|3] ""  NF_Controller
 SG_ BATT_10_NegDcContWelded m9 : 46|2@1+ (1,0) [0|3] ""  NF_Controller
 SG_ BATT_10_PrechgTooFast m9 : 44|2@1+ (1,0) [0|3] ""  NF_Controller
 SG_ BATT_10_PrechgContWelded m9 : 42|2@1+ (1,0) [0|3] ""  NF_Controller
 SG_ BATT_10_PrechgTimeout m9 : 40|2@1+ (1,0) [0|3] ""  NF_Controller
 SG_ BATT_10_PrechgContStuckOpen m9 : 54|2@1+ (1,0) [0|3] ""  NF_Controller
 SG_ BATT_10_ModuleImbalance m9 : 52|2@1+ (1,0) [0|3] ""  NF_Controller
 SG_ BATT_10_ModuleMIA m9 : 50|2@1+ (1,0) [0|3] ""  NF_Controller
 SG_ BATT_10_SensePackVoltError m9 : 48|2@1+ (1,0) [0|3] ""  NF_Controller
 SG_ BATT_10_SenseLoadVoltError m9 : 62|2@1+ (1,0) [0|3] ""  NF_Controller
 SG_ BATT_10_SenseShuntError m9 : 60|2@1+ (1,0) [0|3] ""  NF_Controller
 SG_ BATT_10_SenseFcVoltErrorr m9 : 58|2@1+ (1,0) [0|3] ""  NF_Controller
 SG_ BATT_10_SenseBrickOpen m9 : 56|2@1+ (1,0) [0|3] ""  NF_Controller
 SG_ BATT_11_vBrickOverSev m10 : 2|2@1+ (1,0) [0|3] ""  NF_Controller
 SG_ BATT_11_vBrickOverMod m10 : 0|2@1+ (1,0) [0|3] ""  NF_Controller
 SG_ BATT_11_vBrickOverWar m10 : 14|2@1+ (1,0) [0|3] ""  NF_Controller
 SG_ BATT_11_HostQuiet m10 : 12|2@1+ (1,0) [0|3] ""  NF_Controller
 SG_ BATT_11_vBrickUnderMod m10 : 10|2@1+ (1,0) [0|3] ""  NF_Controller
 SG_ BATT_11_vBrickUnderWar m10 : 8|2@1+ (1,0) [0|3] ""  NF_Controller
 SG_ BATT_11_TempModuleOverSev m10 : 22|2@1+ (1,0) [0|3] ""  NF_Controller
 SG_ BATT_11_TempModuleOverMod m10 : 20|2@1+ (1,0) [0|3] ""  NF_Controller
 SG_ BATT_11_TempModuleOverWar m10 : 18|2@1+ (1,0) [0|3] ""  NF_Controller
 SG_ BATT_11_TempModuleUnderSev m10 : 16|2@1+ (1,0) [0|3] ""  NF_Controller
 SG_ BATT_11_TempModuleUnderMod m10 : 30|2@1+ (1,0) [0|3] ""  NF_Controller
 SG_ BATT_11_TempModuleUnderWar m10 : 28|2@1+ (1,0) [0|3] ""  NF_Controller
 SG_ BATT_11_iOvercharge m10 : 26|2@1+ (1,0) [0|3] ""  NF_Controller
 SG_ BATT_11_iOverdischarge m10 : 24|2@1+ (1,0) [0|3] ""  NF_Controller
 SG_ BATT_11_iOverHardware m10 : 38|2@1+ (1,0) [0|3] ""  NF_Controller
 SG_ BATT_11_PosDcContStuckOpen m10 : 36|2@1+ (1,0) [0|3] ""  NF_Controller
 SG_ BATT_11_PosDcContWelded m10 : 34|2@1+ (1,0) [0|3] ""  NF_Controller
 SG_ BATT_11_NegDcContStuckOpen m10 : 32|2@1+ (1,0) [0|3] ""  NF_Controller
 SG_ BATT_11_NegDcContWelded m10 : 46|2@1+ (1,0) [0|3] ""  NF_Controller
 SG_ BATT_11_PrechgTooFast m10 : 44|2@1+ (1,0) [0|3] ""  NF_Controller
 SG_ BATT_11_PrechgContWelded m10 : 42|2@1+ (1,0) [0|3] ""  NF_Controller
 SG_ BATT_11_PrechgTimeout m10 : 40|2@1+ (1,0) [0|3] ""  NF_Controller
 SG_ BATT_11_PrechgContStuckOpen m10 : 54|2@1+ (1,0) [0|3] ""  NF_Controller
 SG_ BATT_11_ModuleImbalance m10 : 52|2@1+ (1,0) [0|3] ""  NF_Controller
 SG_ BATT_11_ModuleMIA m10 : 50|2@1+ (1,0) [0|3] ""  NF_Controller
 SG_ BATT_11_SensePackVoltError m10 : 48|2@1+ (1,0) [0|3] ""  NF_Controller
 SG_ BATT_11_SenseLoadVoltError m10 : 62|2@1+ (1,0) [0|3] ""  NF_Controller
 SG_ BATT_11_SenseShuntError m10 : 60|2@1+ (1,0) [0|3] ""  NF_Controller
 SG_ BATT_11_SenseFcVoltErrorr m10 : 58|2@1+ (1,0) [0|3] ""  NF_Controller
 SG_ BATT_11_SenseBrickOpen m10 : 56|2@1+ (1,0) [0|3] ""  NF_Controller
 SG_ BATT_12_vBrickOverSev m11 : 2|2@1+ (1,0) [0|3] ""  NF_Controller
 SG_ BATT_12_vBrickOverMod m11 : 0|2@1+ (1,0) [0|3] ""  NF_Controller
 SG_ BATT_12_vBrickOverWar m11 : 14|2@1+ (1,0) [0|3] ""  NF_Controller
 SG_ BATT_12_HostQuiet m11 : 12|2@1+ (1,0) [0|3] ""  NF_Controller
 SG_ BATT_12_vBrickUnderMod m11 : 10|2@1+ (1,0) [0|3] ""  NF_Controller
 SG_ BATT_12_vBrickUnderWar m11 : 8|2@1+ (1,0) [0|3] ""  NF_Controller
 SG_ BATT_12_TempModuleOverSev m11 : 22|2@1+ (1,0) [0|3] ""  NF_Controller
 SG_ BATT_12_TempModuleOverMod m11 : 20|2@1+ (1,0) [0|3] ""  NF_Controller
 SG_ BATT_12_TempModuleOverWar m11 : 18|2@1+ (1,0) [0|3] ""  NF_Controller
 SG_ BATT_12_TempModuleUnderSev m11 : 16|2@1+ (1,0) [0|3] ""  NF_Controller
 SG_ BATT_12_TempModuleUnderMod m11 : 30|2@1+ (1,0) [0|3] ""  NF_Controller
 SG_ BATT_12_TempModuleUnderWar m11 : 28|2@1+ (1,0) [0|3] ""  NF_Controller
 SG_ BATT_12_iOvercharge m11 : 26|2@1+ (1,0) [0|3] ""  NF_Controller
 SG_ BATT_12_iOverdischarge m11 : 24|2@1+ (1,0) [0|3] ""  NF_Controller
 SG_ BATT_12_iOverHardware m11 : 38|2@1+ (1,0) [0|3] ""  NF_Controller
 SG_ BATT_12_PosDcContStuckOpen m11 : 36|2@1+ (1,0) [0|3] ""  NF_Controller
 SG_ BATT_12_PosDcContWelded m11 : 34|2@1+ (1,0) [0|3] ""  NF_Controller
 SG_ BATT_12_NegDcContStuckOpen m11 : 32|2@1+ (1,0) [0|3] ""  NF_Controller
 SG_ BATT_12_NegDcContWelded m11 : 46|2@1+ (1,0) [0|3] ""  NF_Controller
 SG_ BATT_12_PrechgTooFast m11 : 44|2@1+ (1,0) [0|3] ""  NF_Controller
 SG_ BATT_12_PrechgContWelded m11 : 42|2@1+ (1,0) [0|3] ""  NF_Controller
 SG_ BATT_12_PrechgTimeout m11 : 40|2@1+ (1,0) [0|3] ""  NF_Controller
 SG_ BATT_12_PrechgContStuckOpen m11 : 54|2@1+ (1,0) [0|3] ""  NF_Controller
 SG_ BATT_12_ModuleImbalance m11 : 52|2@1+ (1,0) [0|3] ""  NF_Controller
 SG_ BATT_12_ModuleMIA m11 : 50|2@1+ (1,0) [0|3] ""  NF_Controller
 SG_ BATT_12_SensePackVoltError m11 : 48|2@1+ (1,0) [0|3] ""  NF_Controller
 SG_ BATT_12_SenseLoadVoltError m11 : 62|2@1+ (1,0) [0|3] ""  NF_Controller
 SG_ BATT_12_SenseShuntError m11 : 60|2@1+ (1,0) [0|3] ""  NF_Controller
 SG_ BATT_12_SenseFcVoltErrorr m11 : 58|2@1+ (1,0) [0|3] ""  NF_Controller
 SG_ BATT_12_SenseBrickOpen m11 : 56|2@1+ (1,0) [0|3] ""  NF_Controller
 SG_ BATT_13_vBrickOverSev m12 : 2|2@1+ (1,0) [0|3] ""  NF_Controller
 SG_ BATT_13_vBrickOverMod m12 : 0|2@1+ (1,0) [0|3] ""  NF_Controller
 SG_ BATT_13_vBrickOverWar m12 : 14|2@1+ (1,0) [0|3] ""  NF_Controller
 SG_ BATT_13_HostQuiet m12 : 12|2@1+ (1,0) [0|3] ""  NF_Controller
 SG_ BATT_13_vBrickUnderMod m12 : 10|2@1+ (1,0) [0|3] ""  NF_Controller
 SG_ BATT_13_vBrickUnderWar m12 : 8|2@1+ (1,0) [0|3] ""  NF_Controller
 SG_ BATT_13_TempModuleOverSev m12 : 22|2@1+ (1,0) [0|3] ""  NF_Controller
 SG_ BATT_13_TempModuleOverMod m12 : 20|2@1+ (1,0) [0|3] ""  NF_Controller
 SG_ BATT_13_TempModuleOverWar m12 : 18|2@1+ (1,0) [0|3] ""  NF_Controller
 SG_ BATT_13_TempModuleUnderSev m12 : 16|2@1+ (1,0) [0|3] ""  NF_Controller
 SG_ BATT_13_TempModuleUnderMod m12 : 30|2@1+ (1,0) [0|3] ""  NF_Controller
 SG_ BATT_13_TempModuleUnderWar m12 : 28|2@1+ (1,0) [0|3] ""  NF_Controller
 SG_ BATT_13_iOvercharge m12 : 26|2@1+ (1,0) [0|3] ""  NF_Controller
 SG_ BATT_13_iOverdischarge m12 : 24|2@1+ (1,0) [0|3] ""  NF_Controller
 SG_ BATT_13_iOverHardware m12 : 38|2@1+ (1,0) [0|3] ""  NF_Controller
 SG_ BATT_13_PosDcContStuckOpen m12 : 36|2@1+ (1,0) [0|3] ""  NF_Controller
 SG_ BATT_13_PosDcContWelded m12 : 34|2@1+ (1,0) [0|3] ""  NF_Controller
 SG_ BATT_13_NegDcContStuckOpen m12 : 32|2@1+ (1,0) [0|3] ""  NF_Controller
 SG_ BATT_13_NegDcContWelded m12 : 46|2@1+ (1,0) [0|3] ""  NF_Controller
 SG_ BATT_13_PrechgTooFast m12 : 44|2@1+ (1,0) [0|3] ""  NF_Controller
 SG_ BATT_13_PrechgContWelded m12 : 42|2@1+ (1,0) [0|3] ""  NF_Controller
 SG_ BATT_13_PrechgTimeout m12 : 40|2@1+ (1,0) [0|3] ""  NF_Controller
 SG_ BATT_13_PrechgContStuckOpen m12 : 54|2@1+ (1,0) [0|3] ""  NF_Controller
 SG_ BATT_13_ModuleImbalance m12 : 52|2@1+ (1,0) [0|3] ""  NF_Controller
 SG_ BATT_13_ModuleMIA m12 : 50|2@1+ (1,0) [0|3] ""  NF_Controller
 SG_ BATT_13_SensePackVoltError m12 : 48|2@1+ (1,0) [0|3] ""  NF_Controller
 SG_ BATT_13_SenseLoadVoltError m12 : 62|2@1+ (1,0) [0|3] ""  NF_Controller
 SG_ BATT_13_SenseShuntError m12 : 60|2@1+ (1,0) [0|3] ""  NF_Controller
 SG_ BATT_13_SenseFcVoltErrorr m12 : 58|2@1+ (1,0) [0|3] ""  NF_Controller
 SG_ BATT_13_SenseBrickOpen m12 : 56|2@1+ (1,0) [0|3] ""  NF_Controller
 SG_ BATT_14_vBrickOverSev m13 : 2|2@1+ (1,0) [0|3] ""  NF_Controller
 SG_ BATT_14_vBrickOverMod m13 : 0|2@1+ (1,0) [0|3] ""  NF_Controller
 SG_ BATT_14_vBrickOverWar m13 : 14|2@1+ (1,0) [0|3] ""  NF_Controller
 SG_ BATT_14_HostQuiet m13 : 12|2@1+ (1,0) [0|3] ""  NF_Controller
 SG_ BATT_14_vBrickUnderMod m13 : 10|2@1+ (1,0) [0|3] ""  NF_Controller
 SG_ BATT_14_vBrickUnderWar m13 : 8|2@1+ (1,0) [0|3] ""  NF_Controller
 SG_ BATT_14_TempModuleOverSev m13 : 22|2@1+ (1,0) [0|3] ""  NF_Controller
 SG_ BATT_14_TempModuleOverMod m13 : 20|2@1+ (1,0) [0|3] ""  NF_Controller
 SG_ BATT_14_TempModuleOverWar m13 : 18|2@1+ (1,0) [0|3] ""  NF_Controller
 SG_ BATT_14_TempModuleUnderSev m13 : 16|2@1+ (1,0) [0|3] ""  NF_Controller
 SG_ BATT_14_TempModuleUnderMod m13 : 30|2@1+ (1,0) [0|3] ""  NF_Controller
 SG_ BATT_14_TempModuleUnderWar m13 : 28|2@1+ (1,0) [0|3] ""  NF_Controller
 SG_ BATT_14_iOvercharge m13 : 26|2@1+ (1,0) [0|3] ""  NF_Controller
 SG_ BATT_14_iOverdischarge m13 : 24|2@1+ (1,0) [0|3] ""  NF_Controller
 SG_ BATT_14_iOverHardware m13 : 38|2@1+ (1,0) [0|3] ""  NF_Controller
 SG_ BATT_14_PosDcContStuckOpen m13 : 36|2@1+ (1,0) [0|3] ""  NF_Controller
 SG_ BATT_14_PosDcContWelded m13 : 34|2@1+ (1,0) [0|3] ""  NF_Controller
 SG_ BATT_14_NegDcContStuckOpen m13 : 32|2@1+ (1,0) [0|3] ""  NF_Controller
 SG_ BATT_14_NegDcContWelded m13 : 46|2@1+ (1,0) [0|3] ""  NF_Controller
 SG_ BATT_14_PrechgTooFast m13 : 44|2@1+ (1,0) [0|3] ""  NF_Controller
 SG_ BATT_14_PrechgContWelded m13 : 42|2@1+ (1,0) [0|3] ""  NF_Controller
 SG_ BATT_14_PrechgTimeout m13 : 40|2@1+ (1,0) [0|3] ""  NF_Controller
 SG_ BATT_14_PrechgContStuckOpen m13 : 54|2@1+ (1,0) [0|3] ""  NF_Controller
 SG_ BATT_14_ModuleImbalance m13 : 52|2@1+ (1,0) [0|3] ""  NF_Controller
 SG_ BATT_14_ModuleMIA m13 : 50|2@1+ (1,0) [0|3] ""  NF_Controller
 SG_ BATT_14_SensePackVoltError m13 : 48|2@1+ (1,0) [0|3] ""  NF_Controller
 SG_ BATT_14_SenseLoadVoltError m13 : 62|2@1+ (1,0) [0|3] ""  NF_Controller
 SG_ BATT_14_SenseShuntError m13 : 60|2@1+ (1,0) [0|3] ""  NF_Controller
 SG_ BATT_14_SenseFcVoltErrorr m13 : 58|2@1+ (1,0) [0|3] ""  NF_Controller
 SG_ BATT_14_SenseBrickOpen m13 : 56|2@1+ (1,0) [0|3] ""  NF_Controller
 SG_ BATT_15_vBrickOverSev m14 : 2|2@1+ (1,0) [0|3] ""  NF_Controller
 SG_ BATT_15_vBrickOverMod m14 : 0|2@1+ (1,0) [0|3] ""  NF_Controller
 SG_ BATT_15_vBrickOverWar m14 : 14|2@1+ (1,0) [0|3] ""  NF_Controller
 SG_ BATT_15_HostQuiet m14 : 12|2@1+ (1,0) [0|3] ""  NF_Controller
 SG_ BATT_15_vBrickUnderMod m14 : 10|2@1+ (1,0) [0|3] ""  NF_Controller
 SG_ BATT_15_vBrickUnderWar m14 : 8|2@1+ (1,0) [0|3] ""  NF_Controller
 SG_ BATT_15_TempModuleOverSev m14 : 22|2@1+ (1,0) [0|3] ""  NF_Controller
 SG_ BATT_15_TempModuleOverMod m14 : 20|2@1+ (1,0) [0|3] ""  NF_Controller
 SG_ BATT_15_TempModuleOverWar m14 : 18|2@1+ (1,0) [0|3] ""  NF_Controller
 SG_ BATT_15_TempModuleUnderSev m14 : 16|2@1+ (1,0) [0|3] ""  NF_Controller
 SG_ BATT_15_TempModuleUnderMod m14 : 30|2@1+ (1,0) [0|3] ""  NF_Controller
 SG_ BATT_15_TempModuleUnderWar m14 : 28|2@1+ (1,0) [0|3] ""  NF_Controller
 SG_ BATT_15_iOvercharge m14 : 26|2@1+ (1,0) [0|3] ""  NF_Controller
 SG_ BATT_15_iOverdischarge m14 : 24|2@1+ (1,0) [0|3] ""  NF_Controller
 SG_ BATT_15_iOverHardware m14 : 38|2@1+ (1,0) [0|3] ""  NF_Controller
 SG_ BATT_15_PosDcContStuckOpen m14 : 36|2@1+ (1,0) [0|3] ""  NF_Controller
 SG_ BATT_15_PosDcContWelded m14 : 34|2@1+ (1,0) [0|3] ""  NF_Controller
 SG_ BATT_15_NegDcContStuckOpen m14 : 32|2@1+ (1,0) [0|3] ""  NF_Controller
 SG_ BATT_15_NegDcContWelded m14 : 46|2@1+ (1,0) [0|3] ""  NF_Controller
 SG_ BATT_15_PrechgTooFast m14 : 44|2@1+ (1,0) [0|3] ""  NF_Controller
 SG_ BATT_15_PrechgContWelded m14 : 42|2@1+ (1,0) [0|3] ""  NF_Controller
 SG_ BATT_15_PrechgTimeout m14 : 40|2@1+ (1,0) [0|3] ""  NF_Controller
 SG_ BATT_15_PrechgContStuckOpen m14 : 54|2@1+ (1,0) [0|3] ""  NF_Controller
 SG_ BATT_15_ModuleImbalance m14 : 52|2@1+ (1,0) [0|3] ""  NF_Controller
 SG_ BATT_15_ModuleMIA m14 : 50|2@1+ (1,0) [0|3] ""  NF_Controller
 SG_ BATT_15_SensePackVoltError m14 : 48|2@1+ (1,0) [0|3] ""  NF_Controller
 SG_ BATT_15_SenseLoadVoltError m14 : 62|2@1+ (1,0) [0|3] ""  NF_Controller
 SG_ BATT_15_SenseShuntError m14 : 60|2@1+ (1,0) [0|3] ""  NF_Controller
 SG_ BATT_15_SenseFcVoltErrorr m14 : 58|2@1+ (1,0) [0|3] ""  NF_Controller
 SG_ BATT_15_SenseBrickOpen m14 : 56|2@1+ (1,0) [0|3] ""  NF_Controller
 SG_ multiplexor_batt_diag_A M : 4|4@1+ (1,0) [0|15] ""  NF_Controller
 SG_ BATT_01_SenseBrickImpHigh m0 : 2|2@1+ (1,0) [0|3] ""  NF_Controller
 SG_ BATT_01_AFEfault m0 : 0|2@1+ (1,0) [0|3] ""  NF_Controller
 SG_ BATT_01_AFEerror m0 : 14|2@1+ (1,0) [0|3] ""  NF_Controller
 SG_ BATT_01_HostMIA m0 : 12|2@1+ (1,0) [0|3] ""  NF_Controller
 SG_ BATT_01_TempAmbientOverSev m0 : 10|2@1+ (1,0) [0|3] ""  NF_Controller
 SG_ BATT_01_TempAmbientOverMod m0 : 8|2@1+ (1,0) [0|3] ""  NF_Controller
 SG_ BATT_01_TempAmbientOverWar m0 : 22|2@1+ (1,0) [0|3] ""  NF_Controller
 SG_ BATT_01_AbnormReset m0 : 20|2@1+ (1,0) [0|3] ""  NF_Controller
 SG_ BATT_01_SenseAuxVoltError m0 : 18|2@1+ (1,0) [0|3] ""  NF_Controller
 SG_ BATT_01_CalibrationInvalid m0 : 16|2@1+ (1,0) [0|3] ""  NF_Controller
 SG_ BATT_01_TaskLockup m0 : 30|2@1+ (1,0) [0|3] ""  NF_Controller
 SG_ BATT_01_RAMover m0 : 28|2@1+ (1,0) [0|3] ""  NF_Controller
 SG_ BATT_01_BrickOverdischarge m0 : 26|2@1+ (1,0) [0|3] ""  NF_Controller
 SG_ BATT_01_BrickOvercharge m0 : 24|2@1+ (1,0) [0|3] ""  NF_Controller
 SG_ BATT_01_vBrickImbalance m0 : 38|2@1+ (1,0) [0|3] ""  NF_Controller
 SG_ BATT_01_TempBrickImbalance m0 : 36|2@1+ (1,0) [0|3] ""  NF_Controller
 SG_ BATT_01_CapPackLow m0 : 34|2@1+ (1,0) [0|3] ""  NF_Controller
 SG_ BATT_01_rBrickHigh m0 : 32|2@1+ (1,0) [0|3] ""  NF_Controller
 SG_ BATT_01_PowerpackInsuffErr m0 : 46|2@1+ (1,0) [0|3] ""  NF_Controller
 SG_ BATT_01_BrickSoftShort m0 : 44|2@1+ (1,0) [0|3] ""  NF_Controller
 SG_ BATT_01_chargeUndercurrent m0 : 42|2@1+ (1,0) [0|3] ""  NF_Controller
 SG_ BATT_01_HVILcurrentSourceError m0 : 40|2@1+ (1,0) [0|3] ""  NF_Controller
 SG_ BATT_01_SRS m0 : 54|2@1+ (1,0) [0|3] ""  NF_Controller
 SG_ BATT_01_IsolationExtWar m0 : 52|2@1+ (1,0) [0|3] ""  NF_Controller
 SG_ BATT_01_IsolationIntWar m0 : 50|2@1+ (1,0) [0|3] ""  NF_Controller
 SG_ BATT_01_PyroFuseBlown m0 : 48|2@1+ (1,0) [0|3] ""  NF_Controller
 SG_ BATT_01_vBrickUnderSev m0 : 62|2@1+ (1,0) [0|3] ""  NF_Controller
 SG_ BATT_01_chargePrechargeTimeout m0 : 60|2@1+ (1,0) [0|3] ""  NF_Controller
 SG_ BATT_01_ModuleThermistorShort m0 : 58|2@1+ (1,0) [0|3] ""  NF_Controller
 SG_ BATT_01_ModuleThermistorBroken m0 : 56|2@1+ (1,0) [0|3] ""  NF_Controller
 SG_ BATT_02_SenseBrickImpHigh m1 : 2|2@1+ (1,0) [0|3] ""  NF_Controller
 SG_ BATT_02_AFEfault m1 : 0|2@1+ (1,0) [0|3] ""  NF_Controller
 SG_ BATT_02_AFEerror m1 : 14|2@1+ (1,0) [0|3] ""  NF_Controller
 SG_ BATT_02_HostMIA m1 : 12|2@1+ (1,0) [0|3] ""  NF_Controller
 SG_ BATT_02_TempAmbientOverSev m1 : 10|2@1+ (1,0) [0|3] ""  NF_Controller
 SG_ BATT_02_TempAmbientOverMod m1 : 8|2@1+ (1,0) [0|3] ""  NF_Controller
 SG_ BATT_02_TempAmbientOverWar m1 : 22|2@1+ (1,0) [0|3] ""  NF_Controller
 SG_ BATT_02_AbnormReset m1 : 20|2@1+ (1,0) [0|3] ""  NF_Controller
 SG_ BATT_02_SenseAuxVoltError m1 : 18|2@1+ (1,0) [0|3] ""  NF_Controller
 SG_ BATT_02_CalibrationInvalid m1 : 16|2@1+ (1,0) [0|3] ""  NF_Controller
 SG_ BATT_02_TaskLockup m1 : 30|2@1+ (1,0) [0|3] ""  NF_Controller
 SG_ BATT_02_RAMover m1 : 28|2@1+ (1,0) [0|3] ""  NF_Controller
 SG_ BATT_02_BrickOverdischarge m1 : 26|2@1+ (1,0) [0|3] ""  NF_Controller
 SG_ BATT_02_BrickOvercharge m1 : 24|2@1+ (1,0) [0|3] ""  NF_Controller
 SG_ BATT_02_vBrickImbalance m1 : 38|2@1+ (1,0) [0|3] ""  NF_Controller
 SG_ BATT_02_TempBrickImbalance m1 : 36|2@1+ (1,0) [0|3] ""  NF_Controller
 SG_ BATT_02_CapPackLow m1 : 34|2@1+ (1,0) [0|3] ""  NF_Controller
 SG_ BATT_02_rBrickHigh m1 : 32|2@1+ (1,0) [0|3] ""  NF_Controller
 SG_ BATT_02_PowerpackInsuffErr m1 : 46|2@1+ (1,0) [0|3] ""  NF_Controller
 SG_ BATT_02_BrickSoftShort m1 : 44|2@1+ (1,0) [0|3] ""  NF_Controller
 SG_ BATT_02_chargeUndercurrent m1 : 42|2@1+ (1,0) [0|3] ""  NF_Controller
 SG_ BATT_02_HVILcurrentSourceError m1 : 40|2@1+ (1,0) [0|3] ""  NF_Controller
 SG_ BATT_02_SRS m1 : 54|2@1+ (1,0) [0|3] ""  NF_Controller
 SG_ BATT_02_IsolationExtWar m1 : 52|2@1+ (1,0) [0|3] ""  NF_Controller
 SG_ BATT_02_IsolationIntWar m1 : 50|2@1+ (1,0) [0|3] ""  NF_Controller
 SG_ BATT_02_PyroFuseBlown m1 : 48|2@1+ (1,0) [0|3] ""  NF_Controller
 SG_ BATT_02_vBrickUnderSev m1 : 62|2@1+ (1,0) [0|3] ""  NF_Controller
 SG_ BATT_02_chargePrechargeTimeout m1 : 60|2@1+ (1,0) [0|3] ""  NF_Controller
 SG_ BATT_02_ModuleThermistorShort m1 : 58|2@1+ (1,0) [0|3] ""  NF_Controller
 SG_ BATT_02_ModuleThermistorBroken m1 : 56|2@1+ (1,0) [0|3] ""  NF_Controller
 SG_ BATT_03_SenseBrickImpHigh m2 : 2|2@1+ (1,0) [0|3] ""  NF_Controller
 SG_ BATT_03_AFEfault m2 : 0|2@1+ (1,0) [0|3] ""  NF_Controller
 SG_ BATT_03_AFEerror m2 : 14|2@1+ (1,0) [0|3] ""  NF_Controller
 SG_ BATT_03_HostMIA m2 : 12|2@1+ (1,0) [0|3] ""  NF_Controller
 SG_ BATT_03_TempAmbientOverSev m2 : 10|2@1+ (1,0) [0|3] ""  NF_Controller
 SG_ BATT_03_TempAmbientOverMod m2 : 8|2@1+ (1,0) [0|3] ""  NF_Controller
 SG_ BATT_03_TempAmbientOverWar m2 : 22|2@1+ (1,0) [0|3] ""  NF_Controller
 SG_ BATT_03_AbnormReset m2 : 20|2@1+ (1,0) [0|3] ""  NF_Controller
 SG_ BATT_03_SenseAuxVoltError m2 : 18|2@1+ (1,0) [0|3] ""  NF_Controller
 SG_ BATT_03_CalibrationInvalid m2 : 16|2@1+ (1,0) [0|3] ""  NF_Controller
 SG_ BATT_03_TaskLockup m2 : 30|2@1+ (1,0) [0|3] ""  NF_Controller
 SG_ BATT_03_RAMover m2 : 28|2@1+ (1,0) [0|3] ""  NF_Controller
 SG_ BATT_03_BrickOverdischarge m2 : 26|2@1+ (1,0) [0|3] ""  NF_Controller
 SG_ BATT_03_BrickOvercharge m2 : 24|2@1+ (1,0) [0|3] ""  NF_Controller
 SG_ BATT_03_vBrickImbalance m2 : 38|2@1+ (1,0) [0|3] ""  NF_Controller
 SG_ BATT_03_TempBrickImbalance m2 : 36|2@1+ (1,0) [0|3] ""  NF_Controller
 SG_ BATT_03_CapPackLow m2 : 34|2@1+ (1,0) [0|3] ""  NF_Controller
 SG_ BATT_03_rBrickHigh m2 : 32|2@1+ (1,0) [0|3] ""  NF_Controller
 SG_ BATT_03_PowerpackInsuffErr m2 : 46|2@1+ (1,0) [0|3] ""  NF_Controller
 SG_ BATT_03_BrickSoftShort m2 : 44|2@1+ (1,0) [0|3] ""  NF_Controller
 SG_ BATT_03_chargeUndercurrent m2 : 42|2@1+ (1,0) [0|3] ""  NF_Controller
 SG_ BATT_03_HVILcurrentSourceError m2 : 40|2@1+ (1,0) [0|3] ""  NF_Controller
 SG_ BATT_03_SRS m2 : 54|2@1+ (1,0) [0|3] ""  NF_Controller
 SG_ BATT_03_IsolationExtWar m2 : 52|2@1+ (1,0) [0|3] ""  NF_Controller
 SG_ BATT_03_IsolationIntWar m2 : 50|2@1+ (1,0) [0|3] ""  NF_Controller
 SG_ BATT_03_PyroFuseBlown m2 : 48|2@1+ (1,0) [0|3] ""  NF_Controller
 SG_ BATT_03_vBrickUnderSev m2 : 62|2@1+ (1,0) [0|3] ""  NF_Controller
 SG_ BATT_03_chargePrechargeTimeout m2 : 60|2@1+ (1,0) [0|3] ""  NF_Controller
 SG_ BATT_03_ModuleThermistorShort m2 : 58|2@1+ (1,0) [0|3] ""  NF_Controller
 SG_ BATT_03_ModuleThermistorBroken m2 : 56|2@1+ (1,0) [0|3] ""  NF_Controller
 SG_ BATT_04_SenseBrickImpHigh m3 : 2|2@1+ (1,0) [0|3] ""  NF_Controller
 SG_ BATT_04_AFEfault m3 : 0|2@1+ (1,0) [0|3] ""  NF_Controller
 SG_ BATT_04_AFEerror m3 : 14|2@1+ (1,0) [0|3] ""  NF_Controller
 SG_ BATT_04_HostMIA m3 : 12|2@1+ (1,0) [0|3] ""  NF_Controller
 SG_ BATT_04_TempAmbientOverSev m3 : 10|2@1+ (1,0) [0|3] ""  NF_Controller
 SG_ BATT_04_TempAmbientOverMod m3 : 8|2@1+ (1,0) [0|3] ""  NF_Controller
 SG_ BATT_04_TempAmbientOverWar m3 : 22|2@1+ (1,0) [0|3] ""  NF_Controller
 SG_ BATT_04_AbnormReset m3 : 20|2@1+ (1,0) [0|3] ""  NF_Controller
 SG_ BATT_04_SenseAuxVoltError m3 : 18|2@1+ (1,0) [0|3] ""  NF_Controller
 SG_ BATT_04_CalibrationInvalid m3 : 16|2@1+ (1,0) [0|3] ""  NF_Controller
 SG_ BATT_04_TaskLockup m3 : 30|2@1+ (1,0) [0|3] ""  NF_Controller
 SG_ BATT_04_RAMover m3 : 28|2@1+ (1,0) [0|3] ""  NF_Controller
 SG_ BATT_04_BrickOverdischarge m3 : 26|2@1+ (1,0) [0|3] ""  NF_Controller
 SG_ BATT_04_BrickOvercharge m3 : 24|2@1+ (1,0) [0|3] ""  NF_Controller
 SG_ BATT_04_vBrickImbalance m3 : 38|2@1+ (1,0) [0|3] ""  NF_Controller
 SG_ BATT_04_TempBrickImbalance m3 : 36|2@1+ (1,0) [0|3] ""  NF_Controller
 SG_ BATT_04_CapPackLow m3 : 34|2@1+ (1,0) [0|3] ""  NF_Controller
 SG_ BATT_04_rBrickHigh m3 : 32|2@1+ (1,0) [0|3] ""  NF_Controller
 SG_ BATT_04_PowerpackInsuffErr m3 : 46|2@1+ (1,0) [0|3] ""  NF_Controller
 SG_ BATT_04_BrickSoftShort m3 : 44|2@1+ (1,0) [0|3] ""  NF_Controller
 SG_ BATT_04_chargeUndercurrent m3 : 42|2@1+ (1,0) [0|3] ""  NF_Controller
 SG_ BATT_04_HVILcurrentSourceError m3 : 40|2@1+ (1,0) [0|3] ""  NF_Controller
 SG_ BATT_04_SRS m3 : 54|2@1+ (1,0) [0|3] ""  NF_Controller
 SG_ BATT_04_IsolationExtWar m3 : 52|2@1+ (1,0) [0|3] ""  NF_Controller
 SG_ BATT_04_IsolationIntWar m3 : 50|2@1+ (1,0) [0|3] ""  NF_Controller
 SG_ BATT_04_PyroFuseBlown m3 : 48|2@1+ (1,0) [0|3] ""  NF_Controller
 SG_ BATT_04_vBrickUnderSev m3 : 62|2@1+ (1,0) [0|3] ""  NF_Controller
 SG_ BATT_04_chargePrechargeTimeout m3 : 60|2@1+ (1,0) [0|3] ""  NF_Controller
 SG_ BATT_04_ModuleThermistorShort m3 : 58|2@1+ (1,0) [0|3] ""  NF_Controller
 SG_ BATT_04_ModuleThermistorBroken m3 : 56|2@1+ (1,0) [0|3] ""  NF_Controller
 SG_ BATT_05_SenseBrickImpHigh m4 : 2|2@1+ (1,0) [0|3] ""  NF_Controller
 SG_ BATT_05_AFEfault m4 : 0|2@1+ (1,0) [0|3] ""  NF_Controller
 SG_ BATT_05_AFEerror m4 : 14|2@1+ (1,0) [0|3] ""  NF_Controller
 SG_ BATT_05_HostMIA m4 : 12|2@1+ (1,0) [0|3] ""  NF_Controller
 SG_ BATT_05_TempAmbientOverSev m4 : 10|2@1+ (1,0) [0|3] ""  NF_Controller
 SG_ BATT_05_TempAmbientOverMod m4 : 8|2@1+ (1,0) [0|3] ""  NF_Controller
 SG_ BATT_05_TempAmbientOverWar m4 : 22|2@1+ (1,0) [0|3] ""  NF_Controller
 SG_ BATT_05_AbnormReset m4 : 20|2@1+ (1,0) [0|3] ""  NF_Controller
 SG_ BATT_05_SenseAuxVoltError m4 : 18|2@1+ (1,0) [0|3] ""  NF_Controller
 SG_ BATT_05_CalibrationInvalid m4 : 16|2@1+ (1,0) [0|3] ""  NF_Controller
 SG_ BATT_05_TaskLockup m4 : 30|2@1+ (1,0) [0|3] ""  NF_Controller
 SG_ BATT_05_RAMover m4 : 28|2@1+ (1,0) [0|3] ""  NF_Controller
 SG_ BATT_05_BrickOverdischarge m4 : 26|2@1+ (1,0) [0|3] ""  NF_Controller
 SG_ BATT_05_BrickOvercharge m4 : 24|2@1+ (1,0) [0|3] ""  NF_Controller
 SG_ BATT_05_vBrickImbalance m4 : 38|2@1+ (1,0) [0|3] ""  NF_Controller
 SG_ BATT_05_TempBrickImbalance m4 : 36|2@1+ (1,0) [0|3] ""  NF_Controller
 SG_ BATT_05_CapPackLow m4 : 34|2@1+ (1,0) [0|3] ""  NF_Controller
 SG_ BATT_05_rBrickHigh m4 : 32|2@1+ (1,0) [0|3] ""  NF_Controller
 SG_ BATT_05_PowerpackInsuffErr m4 : 46|2@1+ (1,0) [0|3] ""  NF_Controller
 SG_ BATT_05_BrickSoftShort m4 : 44|2@1+ (1,0) [0|3] ""  NF_Controller
 SG_ BATT_05_chargeUndercurrent m4 : 42|2@1+ (1,0) [0|3] ""  NF_Controller
 SG_ BATT_05_HVILcurrentSourceError m4 : 40|2@1+ (1,0) [0|3] ""  NF_Controller
 SG_ BATT_05_SRS m4 : 54|2@1+ (1,0) [0|3] ""  NF_Controller
 SG_ BATT_05_IsolationExtWar m4 : 52|2@1+ (1,0) [0|3] ""  NF_Controller
 SG_ BATT_05_IsolationIntWar m4 : 50|2@1+ (1,0) [0|3] ""  NF_Controller
 SG_ BATT_05_PyroFuseBlown m4 : 48|2@1+ (1,0) [0|3] ""  NF_Controller
 SG_ BATT_05_vBrickUnderSev m4 : 62|2@1+ (1,0) [0|3] ""  NF_Controller
 SG_ BATT_05_chargePrechargeTimeout m4 : 60|2@1+ (1,0) [0|3] ""  NF_Controller
 SG_ BATT_05_ModuleThermistorShort m4 : 58|2@1+ (1,0) [0|3] ""  NF_Controller
 SG_ BATT_05_ModuleThermistorBroken m4 : 56|2@1+ (1,0) [0|3] ""  NF_Controller
 SG_ BATT_06_SenseBrickImpHigh m5 : 2|2@1+ (1,0) [0|3] ""  NF_Controller
 SG_ BATT_06_AFEfault m5 : 0|2@1+ (1,0) [0|3] ""  NF_Controller
 SG_ BATT_06_AFEerror m5 : 14|2@1+ (1,0) [0|3] ""  NF_Controller
 SG_ BATT_06_HostMIA m5 : 12|2@1+ (1,0) [0|3] ""  NF_Controller
 SG_ BATT_06_TempAmbientOverSev m5 : 10|2@1+ (1,0) [0|3] ""  NF_Controller
 SG_ BATT_06_TempAmbientOverMod m5 : 8|2@1+ (1,0) [0|3] ""  NF_Controller
 SG_ BATT_06_TempAmbientOverWar m5 : 22|2@1+ (1,0) [0|3] ""  NF_Controller
 SG_ BATT_06_AbnormReset m5 : 20|2@1+ (1,0) [0|3] ""  NF_Controller
 SG_ BATT_06_SenseAuxVoltError m5 : 18|2@1+ (1,0) [0|3] ""  NF_Controller
 SG_ BATT_06_CalibrationInvalid m5 : 16|2@1+ (1,0) [0|3] ""  NF_Controller
 SG_ BATT_06_TaskLockup m5 : 30|2@1+ (1,0) [0|3] ""  NF_Controller
 SG_ BATT_06_RAMover m5 : 28|2@1+ (1,0) [0|3] ""  NF_Controller
 SG_ BATT_06_BrickOverdischarge m5 : 26|2@1+ (1,0) [0|3] ""  NF_Controller
 SG_ BATT_06_BrickOvercharge m5 : 24|2@1+ (1,0) [0|3] ""  NF_Controller
 SG_ BATT_06_vBrickImbalance m5 : 38|2@1+ (1,0) [0|3] ""  NF_Controller
 SG_ BATT_06_TempBrickImbalance m5 : 36|2@1+ (1,0) [0|3] ""  NF_Controller
 SG_ BATT_06_CapPackLow m5 : 34|2@1+ (1,0) [0|3] ""  NF_Controller
 SG_ BATT_06_rBrickHigh m5 : 32|2@1+ (1,0) [0|3] ""  NF_Controller
 SG_ BATT_06_PowerpackInsuffErr m5 : 46|2@1+ (1,0) [0|3] ""  NF_Controller
 SG_ BATT_06_BrickSoftShort m5 : 44|2@1+ (1,0) [0|3] ""  NF_Controller
 SG_ BATT_06_chargeUndercurrent m5 : 42|2@1+ (1,0) [0|3] ""  NF_Controller
 SG_ BATT_06_HVILcurrentSourceError m5 : 40|2@1+ (1,0) [0|3] ""  NF_Controller
 SG_ BATT_06_SRS m5 : 54|2@1+ (1,0) [0|3] ""  NF_Controller
 SG_ BATT_06_IsolationExtWar m5 : 52|2@1+ (1,0) [0|3] ""  NF_Controller
 SG_ BATT_06_IsolationIntWar m5 : 50|2@1+ (1,0) [0|3] ""  NF_Controller
 SG_ BATT_06_PyroFuseBlown m5 : 48|2@1+ (1,0) [0|3] ""  NF_Controller
 SG_ BATT_06_vBrickUnderSev m5 : 62|2@1+ (1,0) [0|3] ""  NF_Controller
 SG_ BATT_06_chargePrechargeTimeout m5 : 60|2@1+ (1,0) [0|3] ""  NF_Controller
 SG_ BATT_06_ModuleThermistorShort m5 : 58|2@1+ (1,0) [0|3] ""  NF_Controller
 SG_ BATT_06_ModuleThermistorBroken m5 : 56|2@1+ (1,0) [0|3] ""  NF_Controller
 SG_ BATT_07_SenseBrickImpHigh m6 : 2|2@1+ (1,0) [0|3] ""  NF_Controller
 SG_ BATT_07_AFEfault m6 : 0|2@1+ (1,0) [0|3] ""  NF_Controller
 SG_ BATT_07_AFEerror m6 : 14|2@1+ (1,0) [0|3] ""  NF_Controller
 SG_ BATT_07_HostMIA m6 : 12|2@1+ (1,0) [0|3] ""  NF_Controller
 SG_ BATT_07_TempAmbientOverSev m6 : 10|2@1+ (1,0) [0|3] ""  NF_Controller
 SG_ BATT_07_TempAmbientOverMod m6 : 8|2@1+ (1,0) [0|3] ""  NF_Controller
 SG_ BATT_07_TempAmbientOverWar m6 : 22|2@1+ (1,0) [0|3] ""  NF_Controller
 SG_ BATT_07_AbnormReset m6 : 20|2@1+ (1,0) [0|3] ""  NF_Controller
 SG_ BATT_07_SenseAuxVoltError m6 : 18|2@1+ (1,0) [0|3] ""  NF_Controller
 SG_ BATT_07_CalibrationInvalid m6 : 16|2@1+ (1,0) [0|3] ""  NF_Controller
 SG_ BATT_07_TaskLockup m6 : 30|2@1+ (1,0) [0|3] ""  NF_Controller
 SG_ BATT_07_RAMover m6 : 28|2@1+ (1,0) [0|3] ""  NF_Controller
 SG_ BATT_07_BrickOverdischarge m6 : 26|2@1+ (1,0) [0|3] ""  NF_Controller
 SG_ BATT_07_BrickOvercharge m6 : 24|2@1+ (1,0) [0|3] ""  NF_Controller
 SG_ BATT_07_vBrickImbalance m6 : 38|2@1+ (1,0) [0|3] ""  NF_Controller
 SG_ BATT_07_TempBrickImbalance m6 : 36|2@1+ (1,0) [0|3] ""  NF_Controller
 SG_ BATT_07_CapPackLow m6 : 34|2@1+ (1,0) [0|3] ""  NF_Controller
 SG_ BATT_07_rBrickHigh m6 : 32|2@1+ (1,0) [0|3] ""  NF_Controller
 SG_ BATT_07_PowerpackInsuffErr m6 : 46|2@1+ (1,0) [0|3] ""  NF_Controller
 SG_ BATT_07_BrickSoftShort m6 : 44|2@1+ (1,0) [0|3] ""  NF_Controller
 SG_ BATT_07_chargeUndercurrent m6 : 42|2@1+ (1,0) [0|3] ""  NF_Controller
 SG_ BATT_07_HVILcurrentSourceError m6 : 40|2@1+ (1,0) [0|3] ""  NF_Controller
 SG_ BATT_07_SRS m6 : 54|2@1+ (1,0) [0|3] ""  NF_Controller
 SG_ BATT_07_IsolationExtWar m6 : 52|2@1+ (1,0) [0|3] ""  NF_Controller
 SG_ BATT_07_IsolationIntWar m6 : 50|2@1+ (1,0) [0|3] ""  NF_Controller
 SG_ BATT_07_PyroFuseBlown m6 : 48|2@1+ (1,0) [0|3] ""  NF_Controller
 SG_ BATT_07_vBrickUnderSev m6 : 62|2@1+ (1,0) [0|3] ""  NF_Controller
 SG_ BATT_07_chargePrechargeTimeout m6 : 60|2@1+ (1,0) [0|3] ""  NF_Controller
 SG_ BATT_07_ModuleThermistorShort m6 : 58|2@1+ (1,0) [0|3] ""  NF_Controller
 SG_ BATT_07_ModuleThermistorBroken m6 : 56|2@1+ (1,0) [0|3] ""  NF_Controller
 SG_ BATT_08_SenseBrickImpHigh m7 : 2|2@1+ (1,0) [0|3] ""  NF_Controller
 SG_ BATT_08_AFEfault m7 : 0|2@1+ (1,0) [0|3] ""  NF_Controller
 SG_ BATT_08_AFEerror m7 : 14|2@1+ (1,0) [0|3] ""  NF_Controller
 SG_ BATT_08_HostMIA m7 : 12|2@1+ (1,0) [0|3] ""  NF_Controller
 SG_ BATT_08_TempAmbientOverSev m7 : 10|2@1+ (1,0) [0|3] ""  NF_Controller
 SG_ BATT_08_TempAmbientOverMod m7 : 8|2@1+ (1,0) [0|3] ""  NF_Controller
 SG_ BATT_08_TempAmbientOverWar m7 : 22|2@1+ (1,0) [0|3] ""  NF_Controller
 SG_ BATT_08_AbnormReset m7 : 20|2@1+ (1,0) [0|3] ""  NF_Controller
 SG_ BATT_08_SenseAuxVoltError m7 : 18|2@1+ (1,0) [0|3] ""  NF_Controller
 SG_ BATT_08_CalibrationInvalid m7 : 16|2@1+ (1,0) [0|3] ""  NF_Controller
 SG_ BATT_08_TaskLockup m7 : 30|2@1+ (1,0) [0|3] ""  NF_Controller
 SG_ BATT_08_RAMover m7 : 28|2@1+ (1,0) [0|3] ""  NF_Controller
 SG_ BATT_08_BrickOverdischarge m7 : 26|2@1+ (1,0) [0|3] ""  NF_Controller
 SG_ BATT_08_BrickOvercharge m7 : 24|2@1+ (1,0) [0|3] ""  NF_Controller
 SG_ BATT_08_vBrickImbalance m7 : 38|2@1+ (1,0) [0|3] ""  NF_Controller
 SG_ BATT_08_TempBrickImbalance m7 : 36|2@1+ (1,0) [0|3] ""  NF_Controller
 SG_ BATT_08_CapPackLow m7 : 34|2@1+ (1,0) [0|3] ""  NF_Controller
 SG_ BATT_08_rBrickHigh m7 : 32|2@1+ (1,0) [0|3] ""  NF_Controller
 SG_ BATT_08_PowerpackInsuffErr m7 : 46|2@1+ (1,0) [0|3] ""  NF_Controller
 SG_ BATT_08_BrickSoftShort m7 : 44|2@1+ (1,0) [0|3] ""  NF_Controller
 SG_ BATT_08_chargeUndercurrent m7 : 42|2@1+ (1,0) [0|3] ""  NF_Controller
 SG_ BATT_08_HVILcurrentSourceError m7 : 40|2@1+ (1,0) [0|3] ""  NF_Controller
 SG_ BATT_08_SRS m7 : 54|2@1+ (1,0) [0|3] ""  NF_Controller
 SG_ BATT_08_IsolationExtWar m7 : 52|2@1+ (1,0) [0|3] ""  NF_Controller
 SG_ BATT_08_IsolationIntWar m7 : 50|2@1+ (1,0) [0|3] ""  NF_Controller
 SG_ BATT_08_PyroFuseBlown m7 : 48|2@1+ (1,0) [0|3] ""  NF_Controller
 SG_ BATT_08_vBrickUnderSev m7 : 62|2@1+ (1,0) [0|3] ""  NF_Controller
 SG_ BATT_08_chargePrechargeTimeout m7 : 60|2@1+ (1,0) [0|3] ""  NF_Controller
 SG_ BATT_08_ModuleThermistorShort m7 : 58|2@1+ (1,0) [0|3] ""  NF_Controller
 SG_ BATT_08_ModuleThermistorBroken m7 : 56|2@1+ (1,0) [0|3] ""  NF_Controller
 SG_ BATT_09_SenseBrickImpHigh m8 : 2|2@1+ (1,0) [0|3] ""  NF_Controller
 SG_ BATT_09_AFEfault m8 : 0|2@1+ (1,0) [0|3] ""  NF_Controller
 SG_ BATT_09_AFEerror m8 : 14|2@1+ (1,0) [0|3] ""  NF_Controller
 SG_ BATT_09_HostMIA m8 : 12|2@1+ (1,0) [0|3] ""  NF_Controller
 SG_ BATT_09_TempAmbientOverSev m8 : 10|2@1+ (1,0) [0|3] ""  NF_Controller
 SG_ BATT_09_TempAmbientOverMod m8 : 8|2@1+ (1,0) [0|3] ""  NF_Controller
 SG_ BATT_09_TempAmbientOverWar m8 : 22|2@1+ (1,0) [0|3] ""  NF_Controller
 SG_ BATT_09_AbnormReset m8 : 20|2@1+ (1,0) [0|3] ""  NF_Controller
 SG_ BATT_09_SenseAuxVoltError m8 : 18|2@1+ (1,0) [0|3] ""  NF_Controller
 SG_ BATT_09_CalibrationInvalid m8 : 16|2@1+ (1,0) [0|3] ""  NF_Controller
 SG_ BATT_09_TaskLockup m8 : 30|2@1+ (1,0) [0|3] ""  NF_Controller
 SG_ BATT_09_RAMover m8 : 28|2@1+ (1,0) [0|3] ""  NF_Controller
 SG_ BATT_09_BrickOverdischarge m8 : 26|2@1+ (1,0) [0|3] ""  NF_Controller
 SG_ BATT_09_BrickOvercharge m8 : 24|2@1+ (1,0) [0|3] ""  NF_Controller
 SG_ BATT_09_vBrickImbalance m8 : 38|2@1+ (1,0) [0|3] ""  NF_Controller
 SG_ BATT_09_TempBrickImbalance m8 : 36|2@1+ (1,0) [0|3] ""  NF_Controller
 SG_ BATT_09_CapPackLow m8 : 34|2@1+ (1,0) [0|3] ""  NF_Controller
 SG_ BATT_09_rBrickHigh m8 : 32|2@1+ (1,0) [0|3] ""  NF_Controller
 SG_ BATT_09_PowerpackInsuffErr m8 : 46|2@1+ (1,0) [0|3] ""  NF_Controller
 SG_ BATT_09_BrickSoftShort m8 : 44|2@1+ (1,0) [0|3] ""  NF_Controller
 SG_ BATT_09_chargeUndercurrent m8 : 42|2@1+ (1,0) [0|3] ""  NF_Controller
 SG_ BATT_09_HVILcurrentSourceError m8 : 40|2@1+ (1,0) [0|3] ""  NF_Controller
 SG_ BATT_09_SRS m8 : 54|2@1+ (1,0) [0|3] ""  NF_Controller
 SG_ BATT_09_IsolationExtWar m8 : 52|2@1+ (1,0) [0|3] ""  NF_Controller
 SG_ BATT_09_IsolationIntWar m8 : 50|2@1+ (1,0) [0|3] ""  NF_Controller
 SG_ BATT_09_PyroFuseBlown m8 : 48|2@1+ (1,0) [0|3] ""  NF_Controller
 SG_ BATT_09_vBrickUnderSev m8 : 62|2@1+ (1,0) [0|3] ""  NF_Controller
 SG_ BATT_09_chargePrechargeTimeout m8 : 60|2@1+ (1,0) [0|3] ""  NF_Controller
 SG_ BATT_09_ModuleThermistorShort m8 : 58|2@1+ (1,0) [0|3] ""  NF_Controller
 SG_ BATT_09_ModuleThermistorBroken m8 : 56|2@1+ (1,0) [0|3] ""  NF_Controller
 SG_ BATT_10_SenseBrickImpHigh m9 : 2|2@1+ (1,0) [0|3] ""  NF_Controller
 SG_ BATT_10_AFEfault m9 : 0|2@1+ (1,0) [0|3] ""  NF_Controller
 SG_ BATT_10_AFEerror m9 : 14|2@1+ (1,0) [0|3] ""  NF_Controller
 SG_ BATT_10_HostMIA m9 : 12|2@1+ (1,0) [0|3] ""  NF_Controller
 SG_ BATT_10_TempAmbientOverSev m9 : 10|2@1+ (1,0) [0|3] ""  NF_Controller
 SG_ BATT_10_TempAmbientOverMod m9 : 8|2@1+ (1,0) [0|3] ""  NF_Controller
 SG_ BATT_10_TempAmbientOverWar m9 : 22|2@1+ (1,0) [0|3] ""  NF_Controller
 SG_ BATT_10_AbnormReset m9 : 20|2@1+ (1,0) [0|3] ""  NF_Controller
 SG_ BATT_10_SenseAuxVoltError m9 : 18|2@1+ (1,0) [0|3] ""  NF_Controller
 SG_ BATT_10_CalibrationInvalid m9 : 16|2@1+ (1,0) [0|3] ""  NF_Controller
 SG_ BATT_10_TaskLockup m9 : 30|2@1+ (1,0) [0|3] ""  NF_Controller
 SG_ BATT_10_RAMover m9 : 28|2@1+ (1,0) [0|3] ""  NF_Controller
 SG_ BATT_10_BrickOverdischarge m9 : 26|2@1+ (1,0) [0|3] ""  NF_Controller
 SG_ BATT_10_BrickOvercharge m9 : 24|2@1+ (1,0) [0|3] ""  NF_Controller
 SG_ BATT_10_vBrickImbalance m9 : 38|2@1+ (1,0) [0|3] ""  NF_Controller
 SG_ BATT_10_TempBrickImbalance m9 : 36|2@1+ (1,0) [0|3] ""  NF_Controller
 SG_ BATT_10_CapPackLow m9 : 34|2@1+ (1,0) [0|3] ""  NF_Controller
 SG_ BATT_10_rBrickHigh m9 : 32|2@1+ (1,0) [0|3] ""  NF_Controller
 SG_ BATT_10_PowerpackInsuffErr m9 : 46|2@1+ (1,0) [0|3] ""  NF_Controller
 SG_ BATT_10_BrickSoftShort m9 : 44|2@1+ (1,0) [0|3] ""  NF_Controller
 SG_ BATT_10_chargeUndercurrent m9 : 42|2@1+ (1,0) [0|3] ""  NF_Controller
 SG_ BATT_10_HVILcurrentSourceError m9 : 40|2@1+ (1,0) [0|3] ""  NF_Controller
 SG_ BATT_10_SRS m9 : 54|2@1+ (1,0) [0|3] ""  NF_Controller
 SG_ BATT_10_IsolationExtWar m9 : 52|2@1+ (1,0) [0|3] ""  NF_Controller
 SG_ BATT_10_IsolationIntWar m9 : 50|2@1+ (1,0) [0|3] ""  NF_Controller
 SG_ BATT_10_PyroFuseBlown m9 : 48|2@1+ (1,0) [0|3] ""  NF_Controller
 SG_ BATT_10_vBrickUnderSev m9 : 62|2@1+ (1,0) [0|3] ""  NF_Controller
 SG_ BATT_10_chargePrechargeTimeout m9 : 60|2@1+ (1,0) [0|3] ""  NF_Controller
 SG_ BATT_10_ModuleThermistorShort m9 : 58|2@1+ (1,0) [0|3] ""  NF_Controller
 SG_ BATT_10_ModuleThermistorBroken m9 : 56|2@1+ (1,0) [0|3] ""  NF_Controller
 SG_ BATT_11_SenseBrickImpHigh m10 : 2|2@1+ (1,0) [0|3] ""  NF_Controller
 SG_ BATT_11_AFEfault m10 : 0|2@1+ (1,0) [0|3] ""  NF_Controller
 SG_ BATT_11_AFEerror m10 : 14|2@1+ (1,0) [0|3] ""  NF_Controller
 SG_ BATT_11_HostMIA m10 : 12|2@1+ (1,0) [0|3] ""  NF_Controller
 SG_ BATT_11_TempAmbientOverSev m10 : 10|2@1+ (1,0) [0|3] ""  NF_Controller
 SG_ BATT_11_TempAmbientOverMod m10 : 8|2@1+ (1,0) [0|3] ""  NF_Controller
 SG_ BATT_11_TempAmbientOverWar m10 : 22|2@1+ (1,0) [0|3] ""  NF_Controller
 SG_ BATT_11_AbnormReset m10 : 20|2@1+ (1,0) [0|3] ""  NF_Controller
 SG_ BATT_11_SenseAuxVoltError m10 : 18|2@1+ (1,0) [0|3] ""  NF_Controller
 SG_ BATT_11_CalibrationInvalid m10 : 16|2@1+ (1,0) [0|3] ""  NF_Controller
 SG_ BATT_11_TaskLockup m10 : 30|2@1+ (1,0) [0|3] ""  NF_Controller
 SG_ BATT_11_RAMover m10 : 28|2@1+ (1,0) [0|3] ""  NF_Controller
 SG_ BATT_11_BrickOverdischarge m10 : 26|2@1+ (1,0) [0|3] ""  NF_Controller
 SG_ BATT_11_BrickOvercharge m10 : 24|2@1+ (1,0) [0|3] ""  NF_Controller
 SG_ BATT_11_vBrickImbalance m10 : 38|2@1+ (1,0) [0|3] ""  NF_Controller
 SG_ BATT_11_TempBrickImbalance m10 : 36|2@1+ (1,0) [0|3] ""  NF_Controller
 SG_ BATT_11_CapPackLow m10 : 34|2@1+ (1,0) [0|3] ""  NF_Controller
 SG_ BATT_11_rBrickHigh m10 : 32|2@1+ (1,0) [0|3] ""  NF_Controller
 SG_ BATT_11_PowerpackInsuffErr m10 : 46|2@1+ (1,0) [0|3] ""  NF_Controller
 SG_ BATT_11_BrickSoftShort m10 : 44|2@1+ (1,0) [0|3] ""  NF_Controller
 SG_ BATT_11_chargeUndercurrent m10 : 42|2@1+ (1,0) [0|3] ""  NF_Controller
 SG_ BATT_11_HVILcurrentSourceError m10 : 40|2@1+ (1,0) [0|3] ""  NF_Controller
 SG_ BATT_11_SRS m10 : 54|2@1+ (1,0) [0|3] ""  NF_Controller
 SG_ BATT_11_IsolationExtWar m10 : 52|2@1+ (1,0) [0|3] ""  NF_Controller
 SG_ BATT_11_IsolationIntWar m10 : 50|2@1+ (1,0) [0|3] ""  NF_Controller
 SG_ BATT_11_PyroFuseBlown m10 : 48|2@1+ (1,0) [0|3] ""  NF_Controller
 SG_ BATT_11_vBrickUnderSev m10 : 62|2@1+ (1,0) [0|3] ""  NF_Controller
 SG_ BATT_11_chargePrechargeTimeout m10 : 60|2@1+ (1,0) [0|3] ""  NF_Controller
 SG_ BATT_11_ModuleThermistorShort m10 : 58|2@1+ (1,0) [0|3] ""  NF_Controller
 SG_ BATT_11_ModuleThermistorBroken m10 : 56|2@1+ (1,0) [0|3] ""  NF_Controller
 SG_ BATT_12_SenseBrickImpHigh m11 : 2|2@1+ (1,0) [0|3] ""  NF_Controller
 SG_ BATT_12_AFEfault m11 : 0|2@1+ (1,0) [0|3] ""  NF_Controller
 SG_ BATT_12_AFEerror m11 : 14|2@1+ (1,0) [0|3] ""  NF_Controller
 SG_ BATT_12_HostMIA m11 : 12|2@1+ (1,0) [0|3] ""  NF_Controller
 SG_ BATT_12_TempAmbientOverSev m11 : 10|2@1+ (1,0) [0|3] ""  NF_Controller
 SG_ BATT_12_TempAmbientOverMod m11 : 8|2@1+ (1,0) [0|3] ""  NF_Controller
 SG_ BATT_12_TempAmbientOverWar m11 : 22|2@1+ (1,0) [0|3] ""  NF_Controller
 SG_ BATT_12_AbnormReset m11 : 20|2@1+ (1,0) [0|3] ""  NF_Controller
 SG_ BATT_12_SenseAuxVoltError m11 : 18|2@1+ (1,0) [0|3] ""  NF_Controller
 SG_ BATT_12_CalibrationInvalid m11 : 16|2@1+ (1,0) [0|3] ""  NF_Controller
 SG_ BATT_12_TaskLockup m11 : 30|2@1+ (1,0) [0|3] ""  NF_Controller
 SG_ BATT_12_RAMover m11 : 28|2@1+ (1,0) [0|3] ""  NF_Controller
 SG_ BATT_12_BrickOverdischarge m11 : 26|2@1+ (1,0) [0|3] ""  NF_Controller
 SG_ BATT_12_BrickOvercharge m11 : 24|2@1+ (1,0) [0|3] ""  NF_Controller
 SG_ BATT_12_vBrickImbalance m11 : 38|2@1+ (1,0) [0|3] ""  NF_Controller
 SG_ BATT_12_TempBrickImbalance m11 : 36|2@1+ (1,0) [0|3] ""  NF_Controller
 SG_ BATT_12_CapPackLow m11 : 34|2@1+ (1,0) [0|3] ""  NF_Controller
 SG_ BATT_12_rBrickHigh m11 : 32|2@1+ (1,0) [0|3] ""  NF_Controller
 SG_ BATT_12_PowerpackInsuffErr m11 : 46|2@1+ (1,0) [0|3] ""  NF_Controller
 SG_ BATT_12_BrickSoftShort m11 : 44|2@1+ (1,0) [0|3] ""  NF_Controller
 SG_ BATT_12_chargeUndercurrent m11 : 42|2@1+ (1,0) [0|3] ""  NF_Controller
 SG_ BATT_12_HVILcurrentSourceError m11 : 40|2@1+ (1,0) [0|3] ""  NF_Controller
 SG_ BATT_12_SRS m11 : 54|2@1+ (1,0) [0|3] ""  NF_Controller
 SG_ BATT_12_IsolationExtWar m11 : 52|2@1+ (1,0) [0|3] ""  NF_Controller
 SG_ BATT_12_IsolationIntWar m11 : 50|2@1+ (1,0) [0|3] ""  NF_Controller
 SG_ BATT_12_PyroFuseBlown m11 : 48|2@1+ (1,0) [0|3] ""  NF_Controller
 SG_ BATT_12_vBrickUnderSev m11 : 62|2@1+ (1,0) [0|3] ""  NF_Controller
 SG_ BATT_12_chargePrechargeTimeout m11 : 60|2@1+ (1,0) [0|3] ""  NF_Controller
 SG_ BATT_12_ModuleThermistorShort m11 : 58|2@1+ (1,0) [0|3] ""  NF_Controller
 SG_ BATT_12_ModuleThermistorBroken m11 : 56|2@1+ (1,0) [0|3] ""  NF_Controller
 SG_ BATT_13_SenseBrickImpHigh m12 : 2|2@1+ (1,0) [0|3] ""  NF_Controller
 SG_ BATT_13_AFEfault m12 : 0|2@1+ (1,0) [0|3] ""  NF_Controller
 SG_ BATT_13_AFEerror m12 : 14|2@1+ (1,0) [0|3] ""  NF_Controller
 SG_ BATT_13_HostMIA m12 : 12|2@1+ (1,0) [0|3] ""  NF_Controller
 SG_ BATT_13_TempAmbientOverSev m12 : 10|2@1+ (1,0) [0|3] ""  NF_Controller
 SG_ BATT_13_TempAmbientOverMod m12 : 8|2@1+ (1,0) [0|3] ""  NF_Controller
 SG_ BATT_13_TempAmbientOverWar m12 : 22|2@1+ (1,0) [0|3] ""  NF_Controller
 SG_ BATT_13_AbnormReset m12 : 20|2@1+ (1,0) [0|3] ""  NF_Controller
 SG_ BATT_13_SenseAuxVoltError m12 : 18|2@1+ (1,0) [0|3] ""  NF_Controller
 SG_ BATT_13_CalibrationInvalid m12 : 16|2@1+ (1,0) [0|3] ""  NF_Controller
 SG_ BATT_13_TaskLockup m12 : 30|2@1+ (1,0) [0|3] ""  NF_Controller
 SG_ BATT_13_RAMover m12 : 28|2@1+ (1,0) [0|3] ""  NF_Controller
 SG_ BATT_13_BrickOverdischarge m12 : 26|2@1+ (1,0) [0|3] ""  NF_Controller
 SG_ BATT_13_BrickOvercharge m12 : 24|2@1+ (1,0) [0|3] ""  NF_Controller
 SG_ BATT_13_vBrickImbalance m12 : 38|2@1+ (1,0) [0|3] ""  NF_Controller
 SG_ BATT_13_TempBrickImbalance m12 : 36|2@1+ (1,0) [0|3] ""  NF_Controller
 SG_ BATT_13_CapPackLow m12 : 34|2@1+ (1,0) [0|3] ""  NF_Controller
 SG_ BATT_13_rBrickHigh m12 : 32|2@1+ (1,0) [0|3] ""  NF_Controller
 SG_ BATT_13_PowerpackInsuffErr m12 : 46|2@1+ (1,0) [0|3] ""  NF_Controller
 SG_ BATT_13_BrickSoftShort m12 : 44|2@1+ (1,0) [0|3] ""  NF_Controller
 SG_ BATT_13_chargeUndercurrent m12 : 42|2@1+ (1,0) [0|3] ""  NF_Controller
 SG_ BATT_13_HVILcurrentSourceError m12 : 40|2@1+ (1,0) [0|3] ""  NF_Controller
 SG_ BATT_13_SRS m12 : 54|2@1+ (1,0) [0|3] ""  NF_Controller
 SG_ BATT_13_IsolationExtWar m12 : 52|2@1+ (1,0) [0|3] ""  NF_Controller
 SG_ BATT_13_IsolationIntWar m12 : 50|2@1+ (1,0) [0|3] ""  NF_Controller
 SG_ BATT_13_PyroFuseBlown m12 : 48|2@1+ (1,0) [0|3] ""  NF_Controller
 SG_ BATT_13_vBrickUnderSev m12 : 62|2@1+ (1,0) [0|3] ""  NF_Controller
 SG_ BATT_13_chargePrechargeTimeout m12 : 60|2@1+ (1,0) [0|3] ""  NF_Controller
 SG_ BATT_13_ModuleThermistorShort m12 : 58|2@1+ (1,0) [0|3] ""  NF_Controller
 SG_ BATT_13_ModuleThermistorBroken m12 : 56|2@1+ (1,0) [0|3] ""  NF_Controller
 SG_ BATT_14_SenseBrickImpHigh m13 : 2|2@1+ (1,0) [0|3] ""  NF_Controller
 SG_ BATT_14_AFEfault m13 : 0|2@1+ (1,0) [0|3] ""  NF_Controller
 SG_ BATT_14_AFEerror m13 : 14|2@1+ (1,0) [0|3] ""  NF_Controller
 SG_ BATT_14_HostMIA m13 : 12|2@1+ (1,0) [0|3] ""  NF_Controller
 SG_ BATT_14_TempAmbientOverSev m13 : 10|2@1+ (1,0) [0|3] ""  NF_Controller
 SG_ BATT_14_TempAmbientOverMod m13 : 8|2@1+ (1,0) [0|3] ""  NF_Controller
 SG_ BATT_14_TempAmbientOverWar m13 : 22|2@1+ (1,0) [0|3] ""  NF_Controller
 SG_ BATT_14_AbnormReset m13 : 20|2@1+ (1,0) [0|3] ""  NF_Controller
 SG_ BATT_14_SenseAuxVoltError m13 : 18|2@1+ (1,0) [0|3] ""  NF_Controller
 SG_ BATT_14_CalibrationInvalid m13 : 16|2@1+ (1,0) [0|3] ""  NF_Controller
 SG_ BATT_14_TaskLockup m13 : 30|2@1+ (1,0) [0|3] ""  NF_Controller
 SG_ BATT_14_RAMover m13 : 28|2@1+ (1,0) [0|3] ""  NF_Controller
 SG_ BATT_14_BrickOverdischarge m13 : 26|2@1+ (1,0) [0|3] ""  NF_Controller
 SG_ BATT_14_BrickOvercharge m13 : 24|2@1+ (1,0) [0|3] ""  NF_Controller
 SG_ BATT_14_vBrickImbalance m13 : 38|2@1+ (1,0) [0|3] ""  NF_Controller
 SG_ BATT_14_TempBrickImbalance m13 : 36|2@1+ (1,0) [0|3] ""  NF_Controller
 SG_ BATT_14_CapPackLow m13 : 34|2@1+ (1,0) [0|3] ""  NF_Controller
 SG_ BATT_14_rBrickHigh m13 : 32|2@1+ (1,0) [0|3] ""  NF_Controller
 SG_ BATT_14_PowerpackInsuffErr m13 : 46|2@1+ (1,0) [0|3] ""  NF_Controller
 SG_ BATT_14_BrickSoftShort m13 : 44|2@1+ (1,0) [0|3] ""  NF_Controller
 SG_ BATT_14_chargeUndercurrent m13 : 42|2@1+ (1,0) [0|3] ""  NF_Controller
 SG_ BATT_14_HVILcurrentSourceError m13 : 40|2@1+ (1,0) [0|3] ""  NF_Controller
 SG_ BATT_14_SRS m13 : 54|2@1+ (1,0) [0|3] ""  NF_Controller
 SG_ BATT_14_IsolationExtWar m13 : 52|2@1+ (1,0) [0|3] ""  NF_Controller
 SG_ BATT_14_IsolationIntWar m13 : 50|2@1+ (1,0) [0|3] ""  NF_Controller
 SG_ BATT_14_PyroFuseBlown m13 : 48|2@1+ (1,0) [0|3] ""  NF_Controller
 SG_ BATT_14_vBrickUnderSev m13 : 62|2@1+ (1,0) [0|3] ""  NF_Controller
 SG_ BATT_14_chargePrechargeTimeout m13 : 60|2@1+ (1,0) [0|3] ""  NF_Controller
 SG_ BATT_14_ModuleThermistorShort m13 : 58|2@1+ (1,0) [0|3] ""  NF_Controller
 SG_ BATT_14_ModuleThermistorBroken m13 : 56|2@1+ (1,0) [0|3] ""  NF_Controller
 SG_ BATT_15_SenseBrickImpHigh m14 : 2|2@1+ (1,0) [0|3] ""  NF_Controller
 SG_ BATT_15_AFEfault m14 : 0|2@1+ (1,0) [0|3] ""  NF_Controller
 SG_ BATT_15_AFEerror m14 : 14|2@1+ (1,0) [0|3] ""  NF_Controller
 SG_ BATT_15_HostMIA m14 : 12|2@1+ (1,0) [0|3] ""  NF_Controller
 SG_ BATT_15_TempAmbientOverSev m14 : 10|2@1+ (1,0) [0|3] ""  NF_Controller
 SG_ BATT_15_TempAmbientOverMod m14 : 8|2@1+ (1,0) [0|3] ""  NF_Controller
 SG_ BATT_15_TempAmbientOverWar m14 : 22|2@1+ (1,0) [0|3] ""  NF_Controller
 SG_ BATT_15_AbnormReset m14 : 20|2@1+ (1,0) [0|3] ""  NF_Controller
 SG_ BATT_15_SenseAuxVoltError m14 : 18|2@1+ (1,0) [0|3] ""  NF_Controller
 SG_ BATT_15_CalibrationInvalid m14 : 16|2@1+ (1,0) [0|3] ""  NF_Controller
 SG_ BATT_15_TaskLockup m14 : 30|2@1+ (1,0) [0|3] ""  NF_Controller
 SG_ BATT_15_RAMover m14 : 28|2@1+ (1,0) [0|3] ""  NF_Controller
 SG_ BATT_15_BrickOverdischarge m14 : 26|2@1+ (1,0) [0|3] ""  NF_Controller
 SG_ BATT_15_BrickOvercharge m14 : 24|2@1+ (1,0) [0|3] ""  NF_Controller
 SG_ BATT_15_vBrickImbalance m14 : 38|2@1+ (1,0) [0|3] ""  NF_Controller
 SG_ BATT_15_TempBrickImbalance m14 : 36|2@1+ (1,0) [0|3] ""  NF_Controller
 SG_ BATT_15_CapPackLow m14 : 34|2@1+ (1,0) [0|3] ""  NF_Controller
 SG_ BATT_15_rBrickHigh m14 : 32|2@1+ (1,0) [0|3] ""  NF_Controller
 SG_ BATT_15_PowerpackInsuffErr m14 : 46|2@1+ (1,0) [0|3] ""  NF_Controller
 SG_ BATT_15_BrickSoftShort m14 : 44|2@1+ (1,0) [0|3] ""  NF_Controller
 SG_ BATT_15_chargeUndercurrent m14 : 42|2@1+ (1,0) [0|3] ""  NF_Controller
 SG_ BATT_15_HVILcurrentSourceError m14 : 40|2@1+ (1,0) [0|3] ""  NF_Controller
 SG_ BATT_15_SRS m14 : 54|2@1+ (1,0) [0|3] ""  NF_Controller
 SG_ BATT_15_IsolationExtWar m14 : 52|2@1+ (1,0) [0|3] ""  NF_Controller
 SG_ BATT_15_IsolationIntWar m14 : 50|2@1+ (1,0) [0|3] ""  NF_Controller
 SG_ BATT_15_PyroFuseBlown m14 : 48|2@1+ (1,0) [0|3] ""  NF_Controller
 SG_ BATT_15_vBrickUnderSev m14 : 62|2@1+ (1,0) [0|3] ""  NF_Controller
 SG_ BATT_15_chargePrechargeTimeout m14 : 60|2@1+ (1,0) [0|3] ""  NF_Controller
 SG_ BATT_15_ModuleThermistorShort m14 : 58|2@1+ (1,0) [0|3] ""  NF_Controller
 SG_ BATT_15_ModuleThermistorBroken m14 : 56|2@1+ (1,0) [0|3] ""  NF_Controller
 SG_ multiplexor_batt_diag_B M : 4|4@1+ (1,0) [0|15] ""  NF_Controller
 SG_ BATT_01_PackVoltageImbalance m0 : 58|2@1+ (1,0) [0|3] ""  NF_Controller
 SG_ BATT_01_PrechargeOvercurrent m0 : 56|2@1+ (1,0) [0|3] ""  NF_Controller
 SG_ BATT_01_HVILvoltageError m0 : 2|2@1+ (1,0) [0|3] ""  NF_Controller
 SG_ BATT_01_HVILcurrentReturnError m0 : 0|2@1+ (1,0) [0|3] ""  NF_Controller
 SG_ BATT_01_PosFcContWelded m0 : 14|2@1+ (1,0) [0|3] ""  NF_Controller
 SG_ BATT_01_PosFcContStuckOpen m0 : 12|2@1+ (1,0) [0|3] ""  NF_Controller
 SG_ BATT_01_NegFcContWelded m0 : 10|2@1+ (1,0) [0|3] ""  NF_Controller
 SG_ BATT_01_NegFcContStuckOpen m0 : 8|2@1+ (1,0) [0|3] ""  NF_Controller
 SG_ BATT_01_IsospiBreak m0 : 22|2@1+ (1,0) [0|3] ""  NF_Controller
 SG_ BATT_01_IsolationIntFault m0 : 20|2@1+ (1,0) [0|3] ""  NF_Controller
 SG_ BATT_01_IsolationExtFault m0 : 18|2@1+ (1,0) [0|3] ""  NF_Controller
 SG_ BATT_01_event_12v_filter_error m0 : 16|2@1+ (1,0) [0|3] ""  NF_Controller
 SG_ BATT_01_event_hall_eff_hi_rang_e m0 : 30|2@1+ (1,0) [0|3] ""  NF_Controller
 SG_ BATT_01_event_brick_volt_sns_ope m0 : 28|2@1+ (1,0) [0|3] ""  NF_Controller
 SG_ BATT_01_event_5v_error m0 : 26|2@1+ (1,0) [0|3] ""  NF_Controller
 SG_ BATT_01_event_3_3_hot_error m0 : 24|2@1+ (1,0) [0|3] ""  NF_Controller
 SG_ BATT_01_event_12v_input_error m0 : 38|2@1+ (1,0) [0|3] ""  NF_Controller
 SG_ BATT_01_event_1_25v_error m0 : 36|2@1+ (1,0) [0|3] ""  NF_Controller
 SG_ BATT_01_event_shunt_MIA m0 : 34|2@1+ (1,0) [0|3] ""  NF_Controller
 SG_ BATT_01_event_SBC_int_reg_error m0 : 32|2@1+ (1,0) [0|3] ""  NF_Controller
 SG_ BATT_01_event_pos_3_3v_analog_er m0 : 46|2@1+ (1,0) [0|3] ""  NF_Controller
 SG_ BATT_01_event_outlt_clnt_thrm_op m0 : 44|2@1+ (1,0) [0|3] ""  NF_Controller
 SG_ BATT_01_event_neg_3_3_analog_err m0 : 42|2@1+ (1,0) [0|3] ""  NF_Controller
 SG_ BATT_01_event_inlet_clnt_thrm_op m0 : 40|2@1+ (1,0) [0|3] ""  NF_Controller
 SG_ BATT_01_event_hall_eff_lo_rang_e m0 : 54|2@1+ (1,0) [0|3] ""  NF_Controller
 SG_ BATT_01_event_outlt_clnt_thrm_sh m0 : 52|2@1+ (1,0) [0|3] ""  NF_Controller
 SG_ BATT_01_event_inlet_clnt_thrm_sh m0 : 50|2@1+ (1,0) [0|3] ""  NF_Controller
 SG_ BATT_01_event_3_3v_error m0 : 48|2@1+ (1,0) [0|3] ""  NF_Controller
 SG_ BATT_02_PackVoltageImbalance m1 : 58|2@1+ (1,0) [0|3] ""  NF_Controller
 SG_ BATT_02_PrechargeOvercurrent m1 : 56|2@1+ (1,0) [0|3] ""  NF_Controller
 SG_ BATT_02_HVILvoltageError m1 : 2|2@1+ (1,0) [0|3] ""  NF_Controller
 SG_ BATT_02_HVILcurrentReturnError m1 : 0|2@1+ (1,0) [0|3] ""  NF_Controller
 SG_ BATT_02_PosFcContWelded m1 : 14|2@1+ (1,0) [0|3] ""  NF_Controller
 SG_ BATT_02_PosFcContStuckOpen m1 : 12|2@1+ (1,0) [0|3] ""  NF_Controller
 SG_ BATT_02_NegFcContWelded m1 : 10|2@1+ (1,0) [0|3] ""  NF_Controller
 SG_ BATT_02_NegFcContStuckOpen m1 : 8|2@1+ (1,0) [0|3] ""  NF_Controller
 SG_ BATT_02_IsospiBreak m1 : 22|2@1+ (1,0) [0|3] ""  NF_Controller
 SG_ BATT_02_IsolationIntFault m1 : 20|2@1+ (1,0) [0|3] ""  NF_Controller
 SG_ BATT_02_IsolationExtFault m1 : 18|2@1+ (1,0) [0|3] ""  NF_Controller
 SG_ BATT_02_event_12v_filter_error m1 : 16|2@1+ (1,0) [0|3] ""  NF_Controller
 SG_ BATT_02_event_hall_eff_hi_rang_e m1 : 30|2@1+ (1,0) [0|3] ""  NF_Controller
 SG_ BATT_02_event_brick_volt_sns_ope m1 : 28|2@1+ (1,0) [0|3] ""  NF_Controller
 SG_ BATT_02_event_5v_error m1 : 26|2@1+ (1,0) [0|3] ""  NF_Controller
 SG_ BATT_02_event_3_3_hot_error m1 : 24|2@1+ (1,0) [0|3] ""  NF_Controller
 SG_ BATT_02_event_12v_input_error m1 : 38|2@1+ (1,0) [0|3] ""  NF_Controller
 SG_ BATT_02_event_1_25v_error m1 : 36|2@1+ (1,0) [0|3] ""  NF_Controller
 SG_ BATT_02_event_shunt_MIA m1 : 34|2@1+ (1,0) [0|3] ""  NF_Controller
 SG_ BATT_02_event_SBC_int_reg_error m1 : 32|2@1+ (1,0) [0|3] ""  NF_Controller
 SG_ BATT_02_event_pos_3_3v_analog_er m1 : 46|2@1+ (1,0) [0|3] ""  NF_Controller
 SG_ BATT_02_event_outlt_clnt_thrm_op m1 : 44|2@1+ (1,0) [0|3] ""  NF_Controller
 SG_ BATT_02_event_neg_3_3_analog_err m1 : 42|2@1+ (1,0) [0|3] ""  NF_Controller
 SG_ BATT_02_event_inlet_clnt_thrm_op m1 : 40|2@1+ (1,0) [0|3] ""  NF_Controller
 SG_ BATT_02_event_hall_eff_lo_rang_e m1 : 54|2@1+ (1,0) [0|3] ""  NF_Controller
 SG_ BATT_02_event_outlt_clnt_thrm_sh m1 : 52|2@1+ (1,0) [0|3] ""  NF_Controller
 SG_ BATT_02_event_inlet_clnt_thrm_sh m1 : 50|2@1+ (1,0) [0|3] ""  NF_Controller
 SG_ BATT_02_event_3_3v_error m1 : 48|2@1+ (1,0) [0|3] ""  NF_Controller
 SG_ BATT_03_PackVoltageImbalance m2 : 58|2@1+ (1,0) [0|3] ""  NF_Controller
 SG_ BATT_03_PrechargeOvercurrent m2 : 56|2@1+ (1,0) [0|3] ""  NF_Controller
 SG_ BATT_03_HVILvoltageError m2 : 2|2@1+ (1,0) [0|3] ""  NF_Controller
 SG_ BATT_03_HVILcurrentReturnError m2 : 0|2@1+ (1,0) [0|3] ""  NF_Controller
 SG_ BATT_03_PosFcContWelded m2 : 14|2@1+ (1,0) [0|3] ""  NF_Controller
 SG_ BATT_03_PosFcContStuckOpen m2 : 12|2@1+ (1,0) [0|3] ""  NF_Controller
 SG_ BATT_03_NegFcContWelded m2 : 10|2@1+ (1,0) [0|3] ""  NF_Controller
 SG_ BATT_03_NegFcContStuckOpen m2 : 8|2@1+ (1,0) [0|3] ""  NF_Controller
 SG_ BATT_03_IsospiBreak m2 : 22|2@1+ (1,0) [0|3] ""  NF_Controller
 SG_ BATT_03_IsolationIntFault m2 : 20|2@1+ (1,0) [0|3] ""  NF_Controller
 SG_ BATT_03_IsolationExtFault m2 : 18|2@1+ (1,0) [0|3] ""  NF_Controller
 SG_ BATT_03_event_12v_filter_error m2 : 16|2@1+ (1,0) [0|3] ""  NF_Controller
 SG_ BATT_03_event_hall_eff_hi_rang_e m2 : 30|2@1+ (1,0) [0|3] ""  NF_Controller
 SG_ BATT_03_event_brick_volt_sns_ope m2 : 28|2@1+ (1,0) [0|3] ""  NF_Controller
 SG_ BATT_03_event_5v_error m2 : 26|2@1+ (1,0) [0|3] ""  NF_Controller
 SG_ BATT_03_event_3_3_hot_error m2 : 24|2@1+ (1,0) [0|3] ""  NF_Controller
 SG_ BATT_03_event_12v_input_error m2 : 38|2@1+ (1,0) [0|3] ""  NF_Controller
 SG_ BATT_03_event_1_25v_error m2 : 36|2@1+ (1,0) [0|3] ""  NF_Controller
 SG_ BATT_03_event_shunt_MIA m2 : 34|2@1+ (1,0) [0|3] ""  NF_Controller
 SG_ BATT_03_event_SBC_int_reg_error m2 : 32|2@1+ (1,0) [0|3] ""  NF_Controller
 SG_ BATT_03_event_pos_3_3v_analog_er m2 : 46|2@1+ (1,0) [0|3] ""  NF_Controller
 SG_ BATT_03_event_outlt_clnt_thrm_op m2 : 44|2@1+ (1,0) [0|3] ""  NF_Controller
 SG_ BATT_03_event_neg_3_3_analog_err m2 : 42|2@1+ (1,0) [0|3] ""  NF_Controller
 SG_ BATT_03_event_inlet_clnt_thrm_op m2 : 40|2@1+ (1,0) [0|3] ""  NF_Controller
 SG_ BATT_03_event_hall_eff_lo_rang_e m2 : 54|2@1+ (1,0) [0|3] ""  NF_Controller
 SG_ BATT_03_event_outlt_clnt_thrm_sh m2 : 52|2@1+ (1,0) [0|3] ""  NF_Controller
 SG_ BATT_03_event_inlet_clnt_thrm_sh m2 : 50|2@1+ (1,0) [0|3] ""  NF_Controller
 SG_ BATT_03_event_3_3v_error m2 : 48|2@1+ (1,0) [0|3] ""  NF_Controller
 SG_ BATT_04_PackVoltageImbalance m3 : 58|2@1+ (1,0) [0|3] ""  NF_Controller
 SG_ BATT_04_PrechargeOvercurrent m3 : 56|2@1+ (1,0) [0|3] ""  NF_Controller
 SG_ BATT_04_HVILvoltageError m3 : 2|2@1+ (1,0) [0|3] ""  NF_Controller
 SG_ BATT_04_HVILcurrentReturnError m3 : 0|2@1+ (1,0) [0|3] ""  NF_Controller
 SG_ BATT_04_PosFcContWelded m3 : 14|2@1+ (1,0) [0|3] ""  NF_Controller
 SG_ BATT_04_PosFcContStuckOpen m3 : 12|2@1+ (1,0) [0|3] ""  NF_Controller
 SG_ BATT_04_NegFcContWelded m3 : 10|2@1+ (1,0) [0|3] ""  NF_Controller
 SG_ BATT_04_NegFcContStuckOpen m3 : 8|2@1+ (1,0) [0|3] ""  NF_Controller
 SG_ BATT_04_IsospiBreak m3 : 22|2@1+ (1,0) [0|3] ""  NF_Controller
 SG_ BATT_04_IsolationIntFault m3 : 20|2@1+ (1,0) [0|3] ""  NF_Controller
 SG_ BATT_04_IsolationExtFault m3 : 18|2@1+ (1,0) [0|3] ""  NF_Controller
 SG_ BATT_04_event_12v_filter_error m3 : 16|2@1+ (1,0) [0|3] ""  NF_Controller
 SG_ BATT_04_event_hall_eff_hi_rang_e m3 : 30|2@1+ (1,0) [0|3] ""  NF_Controller
 SG_ BATT_04_event_brick_volt_sns_ope m3 : 28|2@1+ (1,0) [0|3] ""  NF_Controller
 SG_ BATT_04_event_5v_error m3 : 26|2@1+ (1,0) [0|3] ""  NF_Controller
 SG_ BATT_04_event_3_3_hot_error m3 : 24|2@1+ (1,0) [0|3] ""  NF_Controller
 SG_ BATT_04_event_12v_input_error m3 : 38|2@1+ (1,0) [0|3] ""  NF_Controller
 SG_ BATT_04_event_1_25v_error m3 : 36|2@1+ (1,0) [0|3] ""  NF_Controller
 SG_ BATT_04_event_shunt_MIA m3 : 34|2@1+ (1,0) [0|3] ""  NF_Controller
 SG_ BATT_04_event_SBC_int_reg_error m3 : 32|2@1+ (1,0) [0|3] ""  NF_Controller
 SG_ BATT_04_event_pos_3_3v_analog_er m3 : 46|2@1+ (1,0) [0|3] ""  NF_Controller
 SG_ BATT_04_event_outlt_clnt_thrm_op m3 : 44|2@1+ (1,0) [0|3] ""  NF_Controller
 SG_ BATT_04_event_neg_3_3_analog_err m3 : 42|2@1+ (1,0) [0|3] ""  NF_Controller
 SG_ BATT_04_event_inlet_clnt_thrm_op m3 : 40|2@1+ (1,0) [0|3] ""  NF_Controller
 SG_ BATT_04_event_hall_eff_lo_rang_e m3 : 54|2@1+ (1,0) [0|3] ""  NF_Controller
 SG_ BATT_04_event_outlt_clnt_thrm_sh m3 : 52|2@1+ (1,0) [0|3] ""  NF_Controller
 SG_ BATT_04_event_inlet_clnt_thrm_sh m3 : 50|2@1+ (1,0) [0|3] ""  NF_Controller
 SG_ BATT_04_event_3_3v_error m3 : 48|2@1+ (1,0) [0|3] ""  NF_Controller
 SG_ BATT_05_PackVoltageImbalance m4 : 58|2@1+ (1,0) [0|3] ""  NF_Controller
 SG_ BATT_05_PrechargeOvercurrent m4 : 56|2@1+ (1,0) [0|3] ""  NF_Controller
 SG_ BATT_05_HVILvoltageError m4 : 2|2@1+ (1,0) [0|3] ""  NF_Controller
 SG_ BATT_05_HVILcurrentReturnError m4 : 0|2@1+ (1,0) [0|3] ""  NF_Controller
 SG_ BATT_05_PosFcContWelded m4 : 14|2@1+ (1,0) [0|3] ""  NF_Controller
 SG_ BATT_05_PosFcContStuckOpen m4 : 12|2@1+ (1,0) [0|3] ""  NF_Controller
 SG_ BATT_05_NegFcContWelded m4 : 10|2@1+ (1,0) [0|3] ""  NF_Controller
 SG_ BATT_05_NegFcContStuckOpen m4 : 8|2@1+ (1,0) [0|3] ""  NF_Controller
 SG_ BATT_05_IsospiBreak m4 : 22|2@1+ (1,0) [0|3] ""  NF_Controller
 SG_ BATT_05_IsolationIntFault m4 : 20|2@1+ (1,0) [0|3] ""  NF_Controller
 SG_ BATT_05_IsolationExtFault m4 : 18|2@1+ (1,0) [0|3] ""  NF_Controller
 SG_ BATT_05_event_12v_filter_error m4 : 16|2@1+ (1,0) [0|3] ""  NF_Controller
 SG_ BATT_05_event_hall_eff_hi_rang_e m4 : 30|2@1+ (1,0) [0|3] ""  NF_Controller
 SG_ BATT_05_event_brick_volt_sns_ope m4 : 28|2@1+ (1,0) [0|3] ""  NF_Controller
 SG_ BATT_05_event_5v_error m4 : 26|2@1+ (1,0) [0|3] ""  NF_Controller
 SG_ BATT_05_event_3_3_hot_error m4 : 24|2@1+ (1,0) [0|3] ""  NF_Controller
 SG_ BATT_05_event_12v_input_error m4 : 38|2@1+ (1,0) [0|3] ""  NF_Controller
 SG_ BATT_05_event_1_25v_error m4 : 36|2@1+ (1,0) [0|3] ""  NF_Controller
 SG_ BATT_05_event_shunt_MIA m4 : 34|2@1+ (1,0) [0|3] ""  NF_Controller
 SG_ BATT_05_event_SBC_int_reg_error m4 : 32|2@1+ (1,0) [0|3] ""  NF_Controller
 SG_ BATT_05_event_pos_3_3v_analog_er m4 : 46|2@1+ (1,0) [0|3] ""  NF_Controller
 SG_ BATT_05_event_outlt_clnt_thrm_op m4 : 44|2@1+ (1,0) [0|3] ""  NF_Controller
 SG_ BATT_05_event_neg_3_3_analog_err m4 : 42|2@1+ (1,0) [0|3] ""  NF_Controller
 SG_ BATT_05_event_inlet_clnt_thrm_op m4 : 40|2@1+ (1,0) [0|3] ""  NF_Controller
 SG_ BATT_05_event_hall_eff_lo_rang_e m4 : 54|2@1+ (1,0) [0|3] ""  NF_Controller
 SG_ BATT_05_event_outlt_clnt_thrm_sh m4 : 52|2@1+ (1,0) [0|3] ""  NF_Controller
 SG_ BATT_05_event_inlet_clnt_thrm_sh m4 : 50|2@1+ (1,0) [0|3] ""  NF_Controller
 SG_ BATT_05_event_3_3v_error m4 : 48|2@1+ (1,0) [0|3] ""  NF_Controller
 SG_ BATT_06_PackVoltageImbalance m5 : 58|2@1+ (1,0) [0|3] ""  NF_Controller
 SG_ BATT_06_PrechargeOvercurrent m5 : 56|2@1+ (1,0) [0|3] ""  NF_Controller
 SG_ BATT_06_HVILvoltageError m5 : 2|2@1+ (1,0) [0|3] ""  NF_Controller
 SG_ BATT_06_HVILcurrentReturnError m5 : 0|2@1+ (1,0) [0|3] ""  NF_Controller
 SG_ BATT_06_PosFcContWelded m5 : 14|2@1+ (1,0) [0|3] ""  NF_Controller
 SG_ BATT_06_PosFcContStuckOpen m5 : 12|2@1+ (1,0) [0|3] ""  NF_Controller
 SG_ BATT_06_NegFcContWelded m5 : 10|2@1+ (1,0) [0|3] ""  NF_Controller
 SG_ BATT_06_NegFcContStuckOpen m5 : 8|2@1+ (1,0) [0|3] ""  NF_Controller
 SG_ BATT_06_IsospiBreak m5 : 22|2@1+ (1,0) [0|3] ""  NF_Controller
 SG_ BATT_06_IsolationIntFault m5 : 20|2@1+ (1,0) [0|3] ""  NF_Controller
 SG_ BATT_06_IsolationExtFault m5 : 18|2@1+ (1,0) [0|3] ""  NF_Controller
 SG_ BATT_06_event_12v_filter_error m5 : 16|2@1+ (1,0) [0|3] ""  NF_Controller
 SG_ BATT_06_event_hall_eff_hi_rang_e m5 : 30|2@1+ (1,0) [0|3] ""  NF_Controller
 SG_ BATT_06_event_brick_volt_sns_ope m5 : 28|2@1+ (1,0) [0|3] ""  NF_Controller
 SG_ BATT_06_event_5v_error m5 : 26|2@1+ (1,0) [0|3] ""  NF_Controller
 SG_ BATT_06_event_3_3_hot_error m5 : 24|2@1+ (1,0) [0|3] ""  NF_Controller
 SG_ BATT_06_event_12v_input_error m5 : 38|2@1+ (1,0) [0|3] ""  NF_Controller
 SG_ BATT_06_event_1_25v_error m5 : 36|2@1+ (1,0) [0|3] ""  NF_Controller
 SG_ BATT_06_event_shunt_MIA m5 : 34|2@1+ (1,0) [0|3] ""  NF_Controller
 SG_ BATT_06_event_SBC_int_reg_error m5 : 32|2@1+ (1,0) [0|3] ""  NF_Controller
 SG_ BATT_06_event_pos_3_3v_analog_er m5 : 46|2@1+ (1,0) [0|3] ""  NF_Controller
 SG_ BATT_06_event_outlt_clnt_thrm_op m5 : 44|2@1+ (1,0) [0|3] ""  NF_Controller
 SG_ BATT_06_event_neg_3_3_analog_err m5 : 42|2@1+ (1,0) [0|3] ""  NF_Controller
 SG_ BATT_06_event_inlet_clnt_thrm_op m5 : 40|2@1+ (1,0) [0|3] ""  NF_Controller
 SG_ BATT_06_event_hall_eff_lo_rang_e m5 : 54|2@1+ (1,0) [0|3] ""  NF_Controller
 SG_ BATT_06_event_outlt_clnt_thrm_sh m5 : 52|2@1+ (1,0) [0|3] ""  NF_Controller
 SG_ BATT_06_event_inlet_clnt_thrm_sh m5 : 50|2@1+ (1,0) [0|3] ""  NF_Controller
 SG_ BATT_06_event_3_3v_error m5 : 48|2@1+ (1,0) [0|3] ""  NF_Controller
 SG_ BATT_07_PackVoltageImbalance m6 : 58|2@1+ (1,0) [0|3] ""  NF_Controller
 SG_ BATT_07_PrechargeOvercurrent m6 : 56|2@1+ (1,0) [0|3] ""  NF_Controller
 SG_ BATT_07_HVILvoltageError m6 : 2|2@1+ (1,0) [0|3] ""  NF_Controller
 SG_ BATT_07_HVILcurrentReturnError m6 : 0|2@1+ (1,0) [0|3] ""  NF_Controller
 SG_ BATT_07_PosFcContWelded m6 : 14|2@1+ (1,0) [0|3] ""  NF_Controller
 SG_ BATT_07_PosFcContStuckOpen m6 : 12|2@1+ (1,0) [0|3] ""  NF_Controller
 SG_ BATT_07_NegFcContWelded m6 : 10|2@1+ (1,0) [0|3] ""  NF_Controller
 SG_ BATT_07_NegFcContStuckOpen m6 : 8|2@1+ (1,0) [0|3] ""  NF_Controller
 SG_ BATT_07_IsospiBreak m6 : 22|2@1+ (1,0) [0|3] ""  NF_Controller
 SG_ BATT_07_IsolationIntFault m6 : 20|2@1+ (1,0) [0|3] ""  NF_Controller
 SG_ BATT_07_IsolationExtFault m6 : 18|2@1+ (1,0) [0|3] ""  NF_Controller
 SG_ BATT_07_event_12v_filter_error m6 : 16|2@1+ (1,0) [0|3] ""  NF_Controller
 SG_ BATT_07_event_hall_eff_hi_rang_e m6 : 30|2@1+ (1,0) [0|3] ""  NF_Controller
 SG_ BATT_07_event_brick_volt_sns_ope m6 : 28|2@1+ (1,0) [0|3] ""  NF_Controller
 SG_ BATT_07_event_5v_error m6 : 26|2@1+ (1,0) [0|3] ""  NF_Controller
 SG_ BATT_07_event_3_3_hot_error m6 : 24|2@1+ (1,0) [0|3] ""  NF_Controller
 SG_ BATT_07_event_12v_input_error m6 : 38|2@1+ (1,0) [0|3] ""  NF_Controller
 SG_ BATT_07_event_1_25v_error m6 : 36|2@1+ (1,0) [0|3] ""  NF_Controller
 SG_ BATT_07_event_shunt_MIA m6 : 34|2@1+ (1,0) [0|3] ""  NF_Controller
 SG_ BATT_07_event_SBC_int_reg_error m6 : 32|2@1+ (1,0) [0|3] ""  NF_Controller
 SG_ BATT_07_event_pos_3_3v_analog_er m6 : 46|2@1+ (1,0) [0|3] ""  NF_Controller
 SG_ BATT_07_event_outlt_clnt_thrm_op m6 : 44|2@1+ (1,0) [0|3] ""  NF_Controller
 SG_ BATT_07_event_neg_3_3_analog_err m6 : 42|2@1+ (1,0) [0|3] ""  NF_Controller
 SG_ BATT_07_event_inlet_clnt_thrm_op m6 : 40|2@1+ (1,0) [0|3] ""  NF_Controller
 SG_ BATT_07_event_hall_eff_lo_rang_e m6 : 54|2@1+ (1,0) [0|3] ""  NF_Controller
 SG_ BATT_07_event_outlt_clnt_thrm_sh m6 : 52|2@1+ (1,0) [0|3] ""  NF_Controller
 SG_ BATT_07_event_inlet_clnt_thrm_sh m6 : 50|2@1+ (1,0) [0|3] ""  NF_Controller
 SG_ BATT_07_event_3_3v_error m6 : 48|2@1+ (1,0) [0|3] ""  NF_Controller
 SG_ BATT_08_PackVoltageImbalance m7 : 58|2@1+ (1,0) [0|3] ""  NF_Controller
 SG_ BATT_08_PrechargeOvercurrent m7 : 56|2@1+ (1,0) [0|3] ""  NF_Controller
 SG_ BATT_08_HVILvoltageError m7 : 2|2@1+ (1,0) [0|3] ""  NF_Controller
 SG_ BATT_08_HVILcurrentReturnError m7 : 0|2@1+ (1,0) [0|3] ""  NF_Controller
 SG_ BATT_08_PosFcContWelded m7 : 14|2@1+ (1,0) [0|3] ""  NF_Controller
 SG_ BATT_08_PosFcContStuckOpen m7 : 12|2@1+ (1,0) [0|3] ""  NF_Controller
 SG_ BATT_08_NegFcContWelded m7 : 10|2@1+ (1,0) [0|3] ""  NF_Controller
 SG_ BATT_08_NegFcContStuckOpen m7 : 8|2@1+ (1,0) [0|3] ""  NF_Controller
 SG_ BATT_08_IsospiBreak m7 : 22|2@1+ (1,0) [0|3] ""  NF_Controller
 SG_ BATT_08_IsolationIntFault m7 : 20|2@1+ (1,0) [0|3] ""  NF_Controller
 SG_ BATT_08_IsolationExtFault m7 : 18|2@1+ (1,0) [0|3] ""  NF_Controller
 SG_ BATT_08_event_12v_filter_error m7 : 16|2@1+ (1,0) [0|3] ""  NF_Controller
 SG_ BATT_08_event_hall_eff_hi_rang_e m7 : 30|2@1+ (1,0) [0|3] ""  NF_Controller
 SG_ BATT_08_event_brick_volt_sns_ope m7 : 28|2@1+ (1,0) [0|3] ""  NF_Controller
 SG_ BATT_08_event_5v_error m7 : 26|2@1+ (1,0) [0|3] ""  NF_Controller
 SG_ BATT_08_event_3_3_hot_error m7 : 24|2@1+ (1,0) [0|3] ""  NF_Controller
 SG_ BATT_08_event_12v_input_error m7 : 38|2@1+ (1,0) [0|3] ""  NF_Controller
 SG_ BATT_08_event_1_25v_error m7 : 36|2@1+ (1,0) [0|3] ""  NF_Controller
 SG_ BATT_08_event_shunt_MIA m7 : 34|2@1+ (1,0) [0|3] ""  NF_Controller
 SG_ BATT_08_event_SBC_int_reg_error m7 : 32|2@1+ (1,0) [0|3] ""  NF_Controller
 SG_ BATT_08_event_pos_3_3v_analog_er m7 : 46|2@1+ (1,0) [0|3] ""  NF_Controller
 SG_ BATT_08_event_outlt_clnt_thrm_op m7 : 44|2@1+ (1,0) [0|3] ""  NF_Controller
 SG_ BATT_08_event_neg_3_3_analog_err m7 : 42|2@1+ (1,0) [0|3] ""  NF_Controller
 SG_ BATT_08_event_inlet_clnt_thrm_op m7 : 40|2@1+ (1,0) [0|3] ""  NF_Controller
 SG_ BATT_08_event_hall_eff_lo_rang_e m7 : 54|2@1+ (1,0) [0|3] ""  NF_Controller
 SG_ BATT_08_event_outlt_clnt_thrm_sh m7 : 52|2@1+ (1,0) [0|3] ""  NF_Controller
 SG_ BATT_08_event_inlet_clnt_thrm_sh m7 : 50|2@1+ (1,0) [0|3] ""  NF_Controller
 SG_ BATT_08_event_3_3v_error m7 : 48|2@1+ (1,0) [0|3] ""  NF_Controller
 SG_ BATT_09_PackVoltageImbalance m8 : 58|2@1+ (1,0) [0|3] ""  NF_Controller
 SG_ BATT_09_PrechargeOvercurrent m8 : 56|2@1+ (1,0) [0|3] ""  NF_Controller
 SG_ BATT_09_HVILvoltageError m8 : 2|2@1+ (1,0) [0|3] ""  NF_Controller
 SG_ BATT_09_HVILcurrentReturnError m8 : 0|2@1+ (1,0) [0|3] ""  NF_Controller
 SG_ BATT_09_PosFcContWelded m8 : 14|2@1+ (1,0) [0|3] ""  NF_Controller
 SG_ BATT_09_NegFcContWelded m8 : 10|2@1+ (1,0) [0|3] ""  NF_Controller
 SG_ BATT_09_NegFcContStuckOpen m8 : 8|2@1+ (1,0) [0|3] ""  NF_Controller
 SG_ BATT_09_PosFcContStuckOpen m8 : 12|2@1+ (1,0) [0|3] ""  NF_Controller
 SG_ BATT_09_IsospiBreak m8 : 22|2@1+ (1,0) [0|3] ""  NF_Controller
 SG_ BATT_09_IsolationIntFault m8 : 20|2@1+ (1,0) [0|3] ""  NF_Controller
 SG_ BATT_09_IsolationExtFault m8 : 18|2@1+ (1,0) [0|3] ""  NF_Controller
 SG_ BATT_09_event_12v_filter_error m8 : 16|2@1+ (1,0) [0|3] ""  NF_Controller
 SG_ BATT_09_event_hall_eff_hi_rang_e m8 : 30|2@1+ (1,0) [0|3] ""  NF_Controller
 SG_ BATT_09_event_brick_volt_sns_ope m8 : 28|2@1+ (1,0) [0|3] ""  NF_Controller
 SG_ BATT_09_event_5v_error m8 : 26|2@1+ (1,0) [0|3] ""  NF_Controller
 SG_ BATT_09_event_3_3_hot_error m8 : 24|2@1+ (1,0) [0|3] ""  NF_Controller
 SG_ BATT_09_event_12v_input_error m8 : 38|2@1+ (1,0) [0|3] ""  NF_Controller
 SG_ BATT_09_event_1_25v_error m8 : 36|2@1+ (1,0) [0|3] ""  NF_Controller
 SG_ BATT_09_event_shunt_MIA m8 : 34|2@1+ (1,0) [0|3] ""  NF_Controller
 SG_ BATT_09_event_SBC_int_reg_error m8 : 32|2@1+ (1,0) [0|3] ""  NF_Controller
 SG_ BATT_09_event_pos_3_3v_analog_er m8 : 46|2@1+ (1,0) [0|3] ""  NF_Controller
 SG_ BATT_09_event_outlt_clnt_thrm_op m8 : 44|2@1+ (1,0) [0|3] ""  NF_Controller
 SG_ BATT_09_event_neg_3_3_analog_err m8 : 42|2@1+ (1,0) [0|3] ""  NF_Controller
 SG_ BATT_09_event_inlet_clnt_thrm_op m8 : 40|2@1+ (1,0) [0|3] ""  NF_Controller
 SG_ BATT_09_event_hall_eff_lo_rang_e m8 : 54|2@1+ (1,0) [0|3] ""  NF_Controller
 SG_ BATT_09_event_outlt_clnt_thrm_sh m8 : 52|2@1+ (1,0) [0|3] ""  NF_Controller
 SG_ BATT_09_event_inlet_clnt_thrm_sh m8 : 50|2@1+ (1,0) [0|3] ""  NF_Controller
 SG_ BATT_09_event_3_3v_error m8 : 48|2@1+ (1,0) [0|3] ""  NF_Controller
 SG_ BATT_10_PackVoltageImbalance m9 : 58|2@1+ (1,0) [0|3] ""  NF_Controller
 SG_ BATT_10_PrechargeOvercurrent m9 : 56|2@1+ (1,0) [0|3] ""  NF_Controller
 SG_ BATT_10_HVILvoltageError m9 : 2|2@1+ (1,0) [0|3] ""  NF_Controller
 SG_ BATT_10_HVILcurrentReturnError m9 : 0|2@1+ (1,0) [0|3] ""  NF_Controller
 SG_ BATT_10_PosFcContWelded m9 : 14|2@1+ (1,0) [0|3] ""  NF_Controller
 SG_ BATT_10_PosFcContStuckOpen m9 : 12|2@1+ (1,0) [0|3] ""  NF_Controller
 SG_ BATT_10_NegFcContWelded m9 : 10|2@1+ (1,0) [0|3] ""  NF_Controller
 SG_ BATT_10_NegFcContStuckOpen m9 : 8|2@1+ (1,0) [0|3] ""  NF_Controller
 SG_ BATT_10_IsospiBreak m9 : 22|2@1+ (1,0) [0|3] ""  NF_Controller
 SG_ BATT_10_IsolationIntFault m9 : 20|2@1+ (1,0) [0|3] ""  NF_Controller
 SG_ BATT_10_IsolationExtFault m9 : 18|2@1+ (1,0) [0|3] ""  NF_Controller
 SG_ BATT_10_event_12v_filter_error m9 : 16|2@1+ (1,0) [0|3] ""  NF_Controller
 SG_ BATT_10_event_hall_eff_hi_rang_e m9 : 30|2@1+ (1,0) [0|3] ""  NF_Controller
 SG_ BATT_10_event_brick_volt_sns_ope m9 : 28|2@1+ (1,0) [0|3] ""  NF_Controller
 SG_ BATT_10_event_5v_error m9 : 26|2@1+ (1,0) [0|3] ""  NF_Controller
 SG_ BATT_10_event_3_3_hot_error m9 : 24|2@1+ (1,0) [0|3] ""  NF_Controller
 SG_ BATT_10_event_12v_input_error m9 : 38|2@1+ (1,0) [0|3] ""  NF_Controller
 SG_ BATT_10_event_1_25v_error m9 : 36|2@1+ (1,0) [0|3] ""  NF_Controller
 SG_ BATT_10_event_shunt_MIA m9 : 34|2@1+ (1,0) [0|3] ""  NF_Controller
 SG_ BATT_10_event_SBC_int_reg_error m9 : 32|2@1+ (1,0) [0|3] ""  NF_Controller
 SG_ BATT_10_event_pos_3_3v_analog_er m9 : 46|2@1+ (1,0) [0|3] ""  NF_Controller
 SG_ BATT_10_event_outlt_clnt_thrm_op m9 : 44|2@1+ (1,0) [0|3] ""  NF_Controller
 SG_ BATT_10_event_neg_3_3_analog_err m9 : 42|2@1+ (1,0) [0|3] ""  NF_Controller
 SG_ BATT_10_event_inlet_clnt_thrm_op m9 : 40|2@1+ (1,0) [0|3] ""  NF_Controller
 SG_ BATT_10_event_hall_eff_lo_rang_e m9 : 54|2@1+ (1,0) [0|3] ""  NF_Controller
 SG_ BATT_10_event_outlt_clnt_thrm_sh m9 : 52|2@1+ (1,0) [0|3] ""  NF_Controller
 SG_ BATT_10_event_inlet_clnt_thrm_sh m9 : 50|2@1+ (1,0) [0|3] ""  NF_Controller
 SG_ BATT_10_event_3_3v_error m9 : 48|2@1+ (1,0) [0|3] ""  NF_Controller
 SG_ BATT_11_PackVoltageImbalance m10 : 58|2@1+ (1,0) [0|3] ""  NF_Controller
 SG_ BATT_11_PrechargeOvercurrent m10 : 56|2@1+ (1,0) [0|3] ""  NF_Controller
 SG_ BATT_11_HVILvoltageError m10 : 2|2@1+ (1,0) [0|3] ""  NF_Controller
 SG_ BATT_11_HVILcurrentReturnError m10 : 0|2@1+ (1,0) [0|3] ""  NF_Controller
 SG_ BATT_11_PosFcContWelded m10 : 14|2@1+ (1,0) [0|3] ""  NF_Controller
 SG_ BATT_11_PosFcContStuckOpen m10 : 12|2@1+ (1,0) [0|3] ""  NF_Controller
 SG_ BATT_11_NegFcContWelded m10 : 10|2@1+ (1,0) [0|3] ""  NF_Controller
 SG_ BATT_11_NegFcContStuckOpen m10 : 8|2@1+ (1,0) [0|3] ""  NF_Controller
 SG_ BATT_11_IsospiBreak m10 : 22|2@1+ (1,0) [0|3] ""  NF_Controller
 SG_ BATT_11_IsolationIntFault m10 : 20|2@1+ (1,0) [0|3] ""  NF_Controller
 SG_ BATT_11_IsolationExtFault m10 : 18|2@1+ (1,0) [0|3] ""  NF_Controller
 SG_ BATT_11_event_12v_filter_error m10 : 16|2@1+ (1,0) [0|3] ""  NF_Controller
 SG_ BATT_11_event_hall_eff_hi_rang_e m10 : 30|2@1+ (1,0) [0|3] ""  NF_Controller
 SG_ BATT_11_event_brick_volt_sns_ope m10 : 28|2@1+ (1,0) [0|3] ""  NF_Controller
 SG_ BATT_11_event_5v_error m10 : 26|2@1+ (1,0) [0|3] ""  NF_Controller
 SG_ BATT_11_event_3_3_hot_error m10 : 24|2@1+ (1,0) [0|3] ""  NF_Controller
 SG_ BATT_11_event_12v_input_error m10 : 38|2@1+ (1,0) [0|3] ""  NF_Controller
 SG_ BATT_11_event_1_25v_error m10 : 36|2@1+ (1,0) [0|3] ""  NF_Controller
 SG_ BATT_11_event_shunt_MIA m10 : 34|2@1+ (1,0) [0|3] ""  NF_Controller
 SG_ BATT_11_event_SBC_int_reg_error m10 : 32|2@1+ (1,0) [0|3] ""  NF_Controller
 SG_ BATT_11_event_pos_3_3v_analog_er m10 : 46|2@1+ (1,0) [0|3] ""  NF_Controller
 SG_ BATT_11_event_outlt_clnt_thrm_op m10 : 44|2@1+ (1,0) [0|3] ""  NF_Controller
 SG_ BATT_11_event_neg_3_3_analog_err m10 : 42|2@1+ (1,0) [0|3] ""  NF_Controller
 SG_ BATT_11_event_inlet_clnt_thrm_op m10 : 40|2@1+ (1,0) [0|3] ""  NF_Controller
 SG_ BATT_11_event_hall_eff_lo_rang_e m10 : 54|2@1+ (1,0) [0|3] ""  NF_Controller
 SG_ BATT_11_event_outlt_clnt_thrm_sh m10 : 52|2@1+ (1,0) [0|3] ""  NF_Controller
 SG_ BATT_11_event_inlet_clnt_thrm_sh m10 : 50|2@1+ (1,0) [0|3] ""  NF_Controller
 SG_ BATT_11_event_3_3v_error m10 : 48|2@1+ (1,0) [0|3] ""  NF_Controller
 SG_ BATT_12_PackVoltageImbalance m11 : 58|2@1+ (1,0) [0|3] ""  NF_Controller
 SG_ BATT_12_PrechargeOvercurrent m11 : 56|2@1+ (1,0) [0|3] ""  NF_Controller
 SG_ BATT_12_HVILvoltageError m11 : 2|2@1+ (1,0) [0|3] ""  NF_Controller
 SG_ BATT_12_HVILcurrentReturnError m11 : 0|2@1+ (1,0) [0|3] ""  NF_Controller
 SG_ BATT_12_PosFcContWelded m11 : 14|2@1+ (1,0) [0|3] ""  NF_Controller
 SG_ BATT_12_PosFcContStuckOpen m11 : 12|2@1+ (1,0) [0|3] ""  NF_Controller
 SG_ BATT_12_NegFcContWelded m11 : 10|2@1+ (1,0) [0|3] ""  NF_Controller
 SG_ BATT_12_NegFcContStuckOpen m11 : 8|2@1+ (1,0) [0|3] ""  NF_Controller
 SG_ BATT_12_IsospiBreak m11 : 22|2@1+ (1,0) [0|3] ""  NF_Controller
 SG_ BATT_12_IsolationIntFault m11 : 20|2@1+ (1,0) [0|3] ""  NF_Controller
 SG_ BATT_12_IsolationExtFault m11 : 18|2@1+ (1,0) [0|3] ""  NF_Controller
 SG_ BATT_12_event_12v_filter_error m11 : 16|2@1+ (1,0) [0|3] ""  NF_Controller
 SG_ BATT_12_event_hall_eff_hi_rang_e m11 : 30|2@1+ (1,0) [0|3] ""  NF_Controller
 SG_ BATT_12_event_brick_volt_sns_ope m11 : 28|2@1+ (1,0) [0|3] ""  NF_Controller
 SG_ BATT_12_event_5v_error m11 : 26|2@1+ (1,0) [0|3] ""  NF_Controller
 SG_ BATT_12_event_3_3_hot_error m11 : 24|2@1+ (1,0) [0|3] ""  NF_Controller
 SG_ BATT_12_event_12v_input_error m11 : 38|2@1+ (1,0) [0|3] ""  NF_Controller
 SG_ BATT_12_event_1_25v_error m11 : 36|2@1+ (1,0) [0|3] ""  NF_Controller
 SG_ BATT_12_event_shunt_MIA m11 : 34|2@1+ (1,0) [0|3] ""  NF_Controller
 SG_ BATT_12_event_SBC_int_reg_error m11 : 32|2@1+ (1,0) [0|3] ""  NF_Controller
 SG_ BATT_12_event_pos_3_3v_analog_er m11 : 46|2@1+ (1,0) [0|3] ""  NF_Controller
 SG_ BATT_12_event_outlt_clnt_thrm_op m11 : 44|2@1+ (1,0) [0|3] ""  NF_Controller
 SG_ BATT_12_event_neg_3_3_analog_err m11 : 42|2@1+ (1,0) [0|3] ""  NF_Controller
 SG_ BATT_12_event_inlet_clnt_thrm_op m11 : 40|2@1+ (1,0) [0|3] ""  NF_Controller
 SG_ BATT_12_event_hall_eff_lo_rang_e m11 : 54|2@1+ (1,0) [0|3] ""  NF_Controller
 SG_ BATT_12_event_outlt_clnt_thrm_sh m11 : 52|2@1+ (1,0) [0|3] ""  NF_Controller
 SG_ BATT_12_event_inlet_clnt_thrm_sh m11 : 50|2@1+ (1,0) [0|3] ""  NF_Controller
 SG_ BATT_12_event_3_3v_error m11 : 48|2@1+ (1,0) [0|3] ""  NF_Controller
 SG_ BATT_13_PackVoltageImbalance m12 : 58|2@1+ (1,0) [0|3] ""  NF_Controller
 SG_ BATT_13_PrechargeOvercurrent m12 : 56|2@1+ (1,0) [0|3] ""  NF_Controller
 SG_ BATT_13_HVILvoltageError m12 : 2|2@1+ (1,0) [0|3] ""  NF_Controller
 SG_ BATT_13_HVILcurrentReturnError m12 : 0|2@1+ (1,0) [0|3] ""  NF_Controller
 SG_ BATT_13_PosFcContWelded m12 : 14|2@1+ (1,0) [0|3] ""  NF_Controller
 SG_ BATT_13_PosFcContStuckOpen m12 : 12|2@1+ (1,0) [0|3] ""  NF_Controller
 SG_ BATT_13_NegFcContWelded m12 : 10|2@1+ (1,0) [0|3] ""  NF_Controller
 SG_ BATT_13_NegFcContStuckOpen m12 : 8|2@1+ (1,0) [0|3] ""  NF_Controller
 SG_ BATT_13_IsospiBreak m12 : 22|2@1+ (1,0) [0|3] ""  NF_Controller
 SG_ BATT_13_IsolationIntFault m12 : 20|2@1+ (1,0) [0|3] ""  NF_Controller
 SG_ BATT_13_IsolationExtFault m12 : 18|2@1+ (1,0) [0|3] ""  NF_Controller
 SG_ BATT_13_event_12v_filter_error m12 : 16|2@1+ (1,0) [0|3] ""  NF_Controller
 SG_ BATT_13_event_hall_eff_hi_rang_e m12 : 30|2@1+ (1,0) [0|3] ""  NF_Controller
 SG_ BATT_13_event_brick_volt_sns_ope m12 : 28|2@1+ (1,0) [0|3] ""  NF_Controller
 SG_ BATT_13_event_5v_error m12 : 26|2@1+ (1,0) [0|3] ""  NF_Controller
 SG_ BATT_13_event_3_3_hot_error m12 : 24|2@1+ (1,0) [0|3] ""  NF_Controller
 SG_ BATT_13_event_12v_input_error m12 : 38|2@1+ (1,0) [0|3] ""  NF_Controller
 SG_ BATT_13_event_1_25v_error m12 : 36|2@1+ (1,0) [0|3] ""  NF_Controller
 SG_ BATT_13_event_shunt_MIA m12 : 34|2@1+ (1,0) [0|3] ""  NF_Controller
 SG_ BATT_13_event_SBC_int_reg_error m12 : 32|2@1+ (1,0) [0|3] ""  NF_Controller
 SG_ BATT_13_event_pos_3_3v_analog_er m12 : 46|2@1+ (1,0) [0|3] ""  NF_Controller
 SG_ BATT_13_event_outlt_clnt_thrm_op m12 : 44|2@1+ (1,0) [0|3] ""  NF_Controller
 SG_ BATT_13_event_neg_3_3_analog_err m12 : 42|2@1+ (1,0) [0|3] ""  NF_Controller
 SG_ BATT_13_event_inlet_clnt_thrm_op m12 : 40|2@1+ (1,0) [0|3] ""  NF_Controller
 SG_ BATT_13_event_hall_eff_lo_rang_e m12 : 54|2@1+ (1,0) [0|3] ""  NF_Controller
 SG_ BATT_13_event_outlt_clnt_thrm_sh m12 : 52|2@1+ (1,0) [0|3] ""  NF_Controller
 SG_ BATT_13_event_inlet_clnt_thrm_sh m12 : 50|2@1+ (1,0) [0|3] ""  NF_Controller
 SG_ BATT_13_event_3_3v_error m12 : 48|2@1+ (1,0) [0|3] ""  NF_Controller
 SG_ BATT_14_PackVoltageImbalance m13 : 58|2@1+ (1,0) [0|3] ""  NF_Controller
 SG_ BATT_14_PrechargeOvercurrent m13 : 56|2@1+ (1,0) [0|3] ""  NF_Controller
 SG_ BATT_14_HVILvoltageError m13 : 2|2@1+ (1,0) [0|3] ""  NF_Controller
 SG_ BATT_14_HVILcurrentReturnError m13 : 0|2@1+ (1,0) [0|3] ""  NF_Controller
 SG_ BATT_14_PosFcContWelded m13 : 14|2@1+ (1,0) [0|3] ""  NF_Controller
 SG_ BATT_14_PosFcContStuckOpen m13 : 12|2@1+ (1,0) [0|3] ""  NF_Controller
 SG_ BATT_14_NegFcContWelded m13 : 10|2@1+ (1,0) [0|3] ""  NF_Controller
 SG_ BATT_14_NegFcContStuckOpen m13 : 8|2@1+ (1,0) [0|3] ""  NF_Controller
 SG_ BATT_14_IsospiBreak m13 : 22|2@1+ (1,0) [0|3] ""  NF_Controller
 SG_ BATT_14_IsolationIntFault m13 : 20|2@1+ (1,0) [0|3] ""  NF_Controller
 SG_ BATT_14_IsolationExtFault m13 : 18|2@1+ (1,0) [0|3] ""  NF_Controller
 SG_ BATT_14_event_12v_filter_error m13 : 16|2@1+ (1,0) [0|3] ""  NF_Controller
 SG_ BATT_14_event_hall_eff_hi_rang_e m13 : 30|2@1+ (1,0) [0|3] ""  NF_Controller
 SG_ BATT_14_event_brick_volt_sns_ope m13 : 28|2@1+ (1,0) [0|3] ""  NF_Controller
 SG_ BATT_14_event_5v_error m13 : 26|2@1+ (1,0) [0|3] ""  NF_Controller
 SG_ BATT_14_event_3_3_hot_error m13 : 24|2@1+ (1,0) [0|3] ""  NF_Controller
 SG_ BATT_14_event_12v_input_error m13 : 38|2@1+ (1,0) [0|3] ""  NF_Controller
 SG_ BATT_14_event_1_25v_error m13 : 36|2@1+ (1,0) [0|3] ""  NF_Controller
 SG_ BATT_14_event_shunt_MIA m13 : 34|2@1+ (1,0) [0|3] ""  NF_Controller
 SG_ BATT_14_event_SBC_int_reg_error m13 : 32|2@1+ (1,0) [0|3] ""  NF_Controller
 SG_ BATT_14_event_pos_3_3v_analog_er m13 : 46|2@1+ (1,0) [0|3] ""  NF_Controller
 SG_ BATT_14_event_outlt_clnt_thrm_op m13 : 44|2@1+ (1,0) [0|3] ""  NF_Controller
 SG_ BATT_14_event_neg_3_3_analog_err m13 : 42|2@1+ (1,0) [0|3] ""  NF_Controller
 SG_ BATT_14_event_inlet_clnt_thrm_op m13 : 40|2@1+ (1,0) [0|3] ""  NF_Controller
 SG_ BATT_14_event_hall_eff_lo_rang_e m13 : 54|2@1+ (1,0) [0|3] ""  NF_Controller
 SG_ BATT_14_event_outlt_clnt_thrm_sh m13 : 52|2@1+ (1,0) [0|3] ""  NF_Controller
 SG_ BATT_14_event_inlet_clnt_thrm_sh m13 : 50|2@1+ (1,0) [0|3] ""  NF_Controller
 SG_ BATT_14_event_3_3v_error m13 : 48|2@1+ (1,0) [0|3] ""  NF_Controller
 SG_ BATT_15_PackVoltageImbalance m14 : 58|2@1+ (1,0) [0|3] ""  NF_Controller
 SG_ BATT_15_PrechargeOvercurrent m14 : 56|2@1+ (1,0) [0|3] ""  NF_Controller
 SG_ BATT_15_HVILvoltageError m14 : 2|2@1+ (1,0) [0|3] ""  NF_Controller
 SG_ BATT_15_HVILcurrentReturnError m14 : 0|2@1+ (1,0) [0|3] ""  NF_Controller
 SG_ BATT_15_PosFcContWelded m14 : 14|2@1+ (1,0) [0|3] ""  NF_Controller
 SG_ BATT_15_PosFcContStuckOpen m14 : 12|2@1+ (1,0) [0|3] ""  NF_Controller
 SG_ BATT_15_NegFcContWelded m14 : 10|2@1+ (1,0) [0|3] ""  NF_Controller
 SG_ BATT_15_NegFcContStuckOpen m14 : 8|2@1+ (1,0) [0|3] ""  NF_Controller
 SG_ BATT_15_IsospiBreak m14 : 22|2@1+ (1,0) [0|3] ""  NF_Controller
 SG_ BATT_15_IsolationIntFault m14 : 20|2@1+ (1,0) [0|3] ""  NF_Controller
 SG_ BATT_15_IsolationExtFault m14 : 18|2@1+ (1,0) [0|3] ""  NF_Controller
 SG_ BATT_15_event_12v_filter_error m14 : 16|2@1+ (1,0) [0|3] ""  NF_Controller
 SG_ BATT_15_event_hall_eff_hi_rang_e m14 : 30|2@1+ (1,0) [0|3] ""  NF_Controller
 SG_ BATT_15_event_brick_volt_sns_ope m14 : 28|2@1+ (1,0) [0|3] ""  NF_Controller
 SG_ BATT_15_event_5v_error m14 : 26|2@1+ (1,0) [0|3] ""  NF_Controller
 SG_ BATT_15_event_3_3_hot_error m14 : 24|2@1+ (1,0) [0|3] ""  NF_Controller
 SG_ BATT_15_event_12v_input_error m14 : 38|2@1+ (1,0) [0|3] ""  NF_Controller
 SG_ BATT_15_event_1_25v_error m14 : 36|2@1+ (1,0) [0|3] ""  NF_Controller
 SG_ BATT_15_event_shunt_MIA m14 : 34|2@1+ (1,0) [0|3] ""  NF_Controller
 SG_ BATT_15_event_SBC_int_reg_error m14 : 32|2@1+ (1,0) [0|3] ""  NF_Controller
 SG_ BATT_15_event_pos_3_3v_analog_er m14 : 46|2@1+ (1,0) [0|3] ""  NF_Controller
 SG_ BATT_15_event_outlt_clnt_thrm_op m14 : 44|2@1+ (1,0) [0|3] ""  NF_Controller
 SG_ BATT_15_event_neg_3_3_analog_err m14 : 42|2@1+ (1,0) [0|3] ""  NF_Controller
 SG_ BATT_15_event_inlet_clnt_thrm_op m14 : 40|2@1+ (1,0) [0|3] ""  NF_Controller
 SG_ BATT_15_event_hall_eff_lo_rang_e m14 : 54|2@1+ (1,0) [0|3] ""  NF_Controller
 SG_ BATT_15_event_outlt_clnt_thrm_sh m14 : 52|2@1+ (1,0) [0|3] ""  NF_Controller
 SG_ BATT_15_event_inlet_clnt_thrm_sh m14 : 50|2@1+ (1,0) [0|3] ""  NF_Controller
 SG_ BATT_15_event_3_3v_error m14 : 48|2@1+ (1,0) [0|3] ""  NF_Controller
 SG_ multiplexor_batt_diag_C M : 4|4@1+ (1,0) [0|15] ""  NF_Controller
 SG_ BATT_01_Placeholder16 m0 : 10|2@1+ (1,0) [0|3] ""  NF_Controller
 SG_ BATT_01_Placeholder15 m0 : 8|2@1+ (1,0) [0|3] ""  NF_Controller
 SG_ BATT_01_Placeholder14 m0 : 22|2@1+ (1,0) [0|3] ""  NF_Controller
 SG_ BATT_01_Placeholder13 m0 : 20|2@1+ (1,0) [0|3] ""  NF_Controller
 SG_ BATT_01_Placeholder02 m0 : 46|2@1+ (1,0) [0|3] ""  NF_Controller
 SG_ BATT_01_Placeholder01 m0 : 44|2@1+ (1,0) [0|3] ""  NF_Controller
 SG_ BATT_01_Placeholder12 m0 : 18|2@1+ (1,0) [0|3] ""  NF_Controller
 SG_ BATT_01_Placeholder11 m0 : 16|2@1+ (1,0) [0|3] ""  NF_Controller
 SG_ BATT_01_Placeholder10 m0 : 30|2@1+ (1,0) [0|3] ""  NF_Controller
 SG_ BATT_01_Placeholder09 m0 : 28|2@1+ (1,0) [0|3] ""  NF_Controller
 SG_ BATT_01_Placeholder08 m0 : 26|2@1+ (1,0) [0|3] ""  NF_Controller
 SG_ BATT_01_Placeholder07 m0 : 24|2@1+ (1,0) [0|3] ""  NF_Controller
 SG_ BATT_01_Placeholder06 m0 : 38|2@1+ (1,0) [0|3] ""  NF_Controller
 SG_ BATT_01_Placeholder05 m0 : 36|2@1+ (1,0) [0|3] ""  NF_Controller
 SG_ BATT_01_SpeakerMia m0 : 2|2@1+ (1,0) [0|3] ""  NF_Controller
 SG_ BATT_01_Placeholder19 m0 : 0|2@1+ (1,0) [0|3] ""  NF_Controller
 SG_ BATT_01_Placeholder18 m0 : 14|2@1+ (1,0) [0|3] ""  NF_Controller
 SG_ BATT_01_Placeholder17 m0 : 12|2@1+ (1,0) [0|3] ""  NF_Controller
 SG_ BATT_01_Placeholder04 m0 : 34|2@1+ (1,0) [0|3] ""  NF_Controller
 SG_ BATT_01_Placeholder03 m0 : 32|2@1+ (1,0) [0|3] ""  NF_Controller
 SG_ BATT_02_Placeholder16 m1 : 10|2@1+ (1,0) [0|3] ""  NF_Controller
 SG_ BATT_02_Placeholder15 m1 : 8|2@1+ (1,0) [0|3] ""  NF_Controller
 SG_ BATT_02_Placeholder14 m1 : 22|2@1+ (1,0) [0|3] ""  NF_Controller
 SG_ BATT_02_Placeholder13 m1 : 20|2@1+ (1,0) [0|3] ""  NF_Controller
 SG_ BATT_02_Placeholder02 m1 : 46|2@1+ (1,0) [0|3] ""  NF_Controller
 SG_ BATT_02_Placeholder01 m1 : 44|2@1+ (1,0) [0|3] ""  NF_Controller
 SG_ BATT_02_Placeholder12 m1 : 18|2@1+ (1,0) [0|3] ""  NF_Controller
 SG_ BATT_02_Placeholder11 m1 : 16|2@1+ (1,0) [0|3] ""  NF_Controller
 SG_ BATT_02_Placeholder10 m1 : 30|2@1+ (1,0) [0|3] ""  NF_Controller
 SG_ BATT_02_Placeholder09 m1 : 28|2@1+ (1,0) [0|3] ""  NF_Controller
 SG_ BATT_02_Placeholder08 m1 : 26|2@1+ (1,0) [0|3] ""  NF_Controller
 SG_ BATT_02_Placeholder07 m1 : 24|2@1+ (1,0) [0|3] ""  NF_Controller
 SG_ BATT_02_Placeholder06 m1 : 38|2@1+ (1,0) [0|3] ""  NF_Controller
 SG_ BATT_02_Placeholder05 m1 : 36|2@1+ (1,0) [0|3] ""  NF_Controller
 SG_ BATT_02_SpeakerMia m1 : 2|2@1+ (1,0) [0|3] ""  NF_Controller
 SG_ BATT_02_Placeholder19 m1 : 0|2@1+ (1,0) [0|3] ""  NF_Controller
 SG_ BATT_02_Placeholder18 m1 : 14|2@1+ (1,0) [0|3] ""  NF_Controller
 SG_ BATT_02_Placeholder17 m1 : 12|2@1+ (1,0) [0|3] ""  NF_Controller
 SG_ BATT_02_Placeholder04 m1 : 34|2@1+ (1,0) [0|3] ""  NF_Controller
 SG_ BATT_02_Placeholder03 m1 : 32|2@1+ (1,0) [0|3] ""  NF_Controller
 SG_ BATT_03_Placeholder16 m2 : 10|2@1+ (1,0) [0|3] ""  NF_Controller
 SG_ BATT_03_Placeholder15 m2 : 8|2@1+ (1,0) [0|3] ""  NF_Controller
 SG_ BATT_03_Placeholder14 m2 : 22|2@1+ (1,0) [0|3] ""  NF_Controller
 SG_ BATT_03_Placeholder13 m2 : 20|2@1+ (1,0) [0|3] ""  NF_Controller
 SG_ BATT_03_Placeholder02 m2 : 46|2@1+ (1,0) [0|3] ""  NF_Controller
 SG_ BATT_03_Placeholder01 m2 : 44|2@1+ (1,0) [0|3] ""  NF_Controller
 SG_ BATT_03_Placeholder12 m2 : 18|2@1+ (1,0) [0|3] ""  NF_Controller
 SG_ BATT_03_Placeholder11 m2 : 16|2@1+ (1,0) [0|3] ""  NF_Controller
 SG_ BATT_03_Placeholder10 m2 : 30|2@1+ (1,0) [0|3] ""  NF_Controller
 SG_ BATT_03_Placeholder09 m2 : 28|2@1+ (1,0) [0|3] ""  NF_Controller
 SG_ BATT_03_Placeholder08 m2 : 26|2@1+ (1,0) [0|3] ""  NF_Controller
 SG_ BATT_03_Placeholder07 m2 : 24|2@1+ (1,0) [0|3] ""  NF_Controller
 SG_ BATT_03_Placeholder06 m2 : 38|2@1+ (1,0) [0|3] ""  NF_Controller
 SG_ BATT_03_Placeholder05 m2 : 36|2@1+ (1,0) [0|3] ""  NF_Controller
 SG_ BATT_03_SpeakerMia m2 : 2|2@1+ (1,0) [0|3] ""  NF_Controller
 SG_ BATT_03_Placeholder19 m2 : 0|2@1+ (1,0) [0|3] ""  NF_Controller
 SG_ BATT_03_Placeholder18 m2 : 14|2@1+ (1,0) [0|3] ""  NF_Controller
 SG_ BATT_03_Placeholder17 m2 : 12|2@1+ (1,0) [0|3] ""  NF_Controller
 SG_ BATT_03_Placeholder04 m2 : 34|2@1+ (1,0) [0|3] ""  NF_Controller
 SG_ BATT_03_Placeholder03 m2 : 32|2@1+ (1,0) [0|3] ""  NF_Controller
 SG_ BATT_04_Placeholder16 m3 : 10|2@1+ (1,0) [0|3] ""  NF_Controller
 SG_ BATT_04_Placeholder15 m3 : 8|2@1+ (1,0) [0|3] ""  NF_Controller
 SG_ BATT_04_Placeholder14 m3 : 22|2@1+ (1,0) [0|3] ""  NF_Controller
 SG_ BATT_04_Placeholder13 m3 : 20|2@1+ (1,0) [0|3] ""  NF_Controller
 SG_ BATT_04_Placeholder02 m3 : 46|2@1+ (1,0) [0|3] ""  NF_Controller
 SG_ BATT_04_Placeholder01 m3 : 44|2@1+ (1,0) [0|3] ""  NF_Controller
 SG_ BATT_04_Placeholder12 m3 : 18|2@1+ (1,0) [0|3] ""  NF_Controller
 SG_ BATT_04_Placeholder11 m3 : 16|2@1+ (1,0) [0|3] ""  NF_Controller
 SG_ BATT_04_Placeholder10 m3 : 30|2@1+ (1,0) [0|3] ""  NF_Controller
 SG_ BATT_04_Placeholder09 m3 : 28|2@1+ (1,0) [0|3] ""  NF_Controller
 SG_ BATT_04_Placeholder08 m3 : 26|2@1+ (1,0) [0|3] ""  NF_Controller
 SG_ BATT_04_Placeholder07 m3 : 24|2@1+ (1,0) [0|3] ""  NF_Controller
 SG_ BATT_04_Placeholder06 m3 : 38|2@1+ (1,0) [0|3] ""  NF_Controller
 SG_ BATT_04_Placeholder05 m3 : 36|2@1+ (1,0) [0|3] ""  NF_Controller
 SG_ BATT_04_SpeakerMia m3 : 2|2@1+ (1,0) [0|3] ""  NF_Controller
 SG_ BATT_04_Placeholder19 m3 : 0|2@1+ (1,0) [0|3] ""  NF_Controller
 SG_ BATT_04_Placeholder18 m3 : 14|2@1+ (1,0) [0|3] ""  NF_Controller
 SG_ BATT_04_Placeholder17 m3 : 12|2@1+ (1,0) [0|3] ""  NF_Controller
 SG_ BATT_04_Placeholder04 m3 : 34|2@1+ (1,0) [0|3] ""  NF_Controller
 SG_ BATT_04_Placeholder03 m3 : 32|2@1+ (1,0) [0|3] ""  NF_Controller
 SG_ BATT_05_Placeholder16 m4 : 10|2@1+ (1,0) [0|3] ""  NF_Controller
 SG_ BATT_05_Placeholder15 m4 : 8|2@1+ (1,0) [0|3] ""  NF_Controller
 SG_ BATT_05_Placeholder14 m4 : 22|2@1+ (1,0) [0|3] ""  NF_Controller
 SG_ BATT_05_Placeholder13 m4 : 20|2@1+ (1,0) [0|3] ""  NF_Controller
 SG_ BATT_05_Placeholder02 m4 : 46|2@1+ (1,0) [0|3] ""  NF_Controller
 SG_ BATT_05_Placeholder01 m4 : 44|2@1+ (1,0) [0|3] ""  NF_Controller
 SG_ BATT_05_Placeholder12 m4 : 18|2@1+ (1,0) [0|3] ""  NF_Controller
 SG_ BATT_05_Placeholder11 m4 : 16|2@1+ (1,0) [0|3] ""  NF_Controller
 SG_ BATT_05_Placeholder10 m4 : 30|2@1+ (1,0) [0|3] ""  NF_Controller
 SG_ BATT_05_Placeholder09 m4 : 28|2@1+ (1,0) [0|3] ""  NF_Controller
 SG_ BATT_05_Placeholder08 m4 : 26|2@1+ (1,0) [0|3] ""  NF_Controller
 SG_ BATT_05_Placeholder07 m4 : 24|2@1+ (1,0) [0|3] ""  NF_Controller
 SG_ BATT_05_Placeholder06 m4 : 38|2@1+ (1,0) [0|3] ""  NF_Controller
 SG_ BATT_05_Placeholder05 m4 : 36|2@1+ (1,0) [0|3] ""  NF_Controller
 SG_ BATT_05_SpeakerMia m4 : 2|2@1+ (1,0) [0|3] ""  NF_Controller
 SG_ BATT_05_Placeholder19 m4 : 0|2@1+ (1,0) [0|3] ""  NF_Controller
 SG_ BATT_05_Placeholder18 m4 : 14|2@1+ (1,0) [0|3] ""  NF_Controller
 SG_ BATT_05_Placeholder17 m4 : 12|2@1+ (1,0) [0|3] ""  NF_Controller
 SG_ BATT_05_Placeholder04 m4 : 34|2@1+ (1,0) [0|3] ""  NF_Controller
 SG_ BATT_05_Placeholder03 m4 : 32|2@1+ (1,0) [0|3] ""  NF_Controller
 SG_ BATT_06_Placeholder16 m5 : 10|2@1+ (1,0) [0|3] ""  NF_Controller
 SG_ BATT_06_Placeholder15 m5 : 8|2@1+ (1,0) [0|3] ""  NF_Controller
 SG_ BATT_06_Placeholder14 m5 : 22|2@1+ (1,0) [0|3] ""  NF_Controller
 SG_ BATT_06_Placeholder13 m5 : 20|2@1+ (1,0) [0|3] ""  NF_Controller
 SG_ BATT_06_Placeholder02 m5 : 46|2@1+ (1,0) [0|3] ""  NF_Controller
 SG_ BATT_06_Placeholder01 m5 : 44|2@1+ (1,0) [0|3] ""  NF_Controller
 SG_ BATT_06_Placeholder12 m5 : 18|2@1+ (1,0) [0|3] ""  NF_Controller
 SG_ BATT_06_Placeholder11 m5 : 16|2@1+ (1,0) [0|3] ""  NF_Controller
 SG_ BATT_06_Placeholder10 m5 : 30|2@1+ (1,0) [0|3] ""  NF_Controller
 SG_ BATT_06_Placeholder09 m5 : 28|2@1+ (1,0) [0|3] ""  NF_Controller
 SG_ BATT_06_Placeholder08 m5 : 26|2@1+ (1,0) [0|3] ""  NF_Controller
 SG_ BATT_06_Placeholder07 m5 : 24|2@1+ (1,0) [0|3] ""  NF_Controller
 SG_ BATT_06_Placeholder06 m5 : 38|2@1+ (1,0) [0|3] ""  NF_Controller
 SG_ BATT_06_Placeholder05 m5 : 36|2@1+ (1,0) [0|3] ""  NF_Controller
 SG_ BATT_06_SpeakerMia m5 : 2|2@1+ (1,0) [0|3] ""  NF_Controller
 SG_ BATT_06_Placeholder19 m5 : 0|2@1+ (1,0) [0|3] ""  NF_Controller
 SG_ BATT_06_Placeholder18 m5 : 14|2@1+ (1,0) [0|3] ""  NF_Controller
 SG_ BATT_06_Placeholder17 m5 : 12|2@1+ (1,0) [0|3] ""  NF_Controller
 SG_ BATT_06_Placeholder04 m5 : 34|2@1+ (1,0) [0|3] ""  NF_Controller
 SG_ BATT_06_Placeholder03 m5 : 32|2@1+ (1,0) [0|3] ""  NF_Controller
 SG_ BATT_07_Placeholder16 m6 : 10|2@1+ (1,0) [0|3] ""  NF_Controller
 SG_ BATT_07_Placeholder15 m6 : 8|2@1+ (1,0) [0|3] ""  NF_Controller
 SG_ BATT_07_Placeholder14 m6 : 22|2@1+ (1,0) [0|3] ""  NF_Controller
 SG_ BATT_07_Placeholder13 m6 : 20|2@1+ (1,0) [0|3] ""  NF_Controller
 SG_ BATT_07_Placeholder02 m6 : 46|2@1+ (1,0) [0|3] ""  NF_Controller
 SG_ BATT_07_Placeholder01 m6 : 44|2@1+ (1,0) [0|3] ""  NF_Controller
 SG_ BATT_07_Placeholder12 m6 : 18|2@1+ (1,0) [0|3] ""  NF_Controller
 SG_ BATT_07_Placeholder11 m6 : 16|2@1+ (1,0) [0|3] ""  NF_Controller
 SG_ BATT_07_Placeholder10 m6 : 30|2@1+ (1,0) [0|3] ""  NF_Controller
 SG_ BATT_07_Placeholder09 m6 : 28|2@1+ (1,0) [0|3] ""  NF_Controller
 SG_ BATT_07_Placeholder08 m6 : 26|2@1+ (1,0) [0|3] ""  NF_Controller
 SG_ BATT_07_Placeholder07 m6 : 24|2@1+ (1,0) [0|3] ""  NF_Controller
 SG_ BATT_07_Placeholder06 m6 : 38|2@1+ (1,0) [0|3] ""  NF_Controller
 SG_ BATT_07_Placeholder05 m6 : 36|2@1+ (1,0) [0|3] ""  NF_Controller
 SG_ BATT_07_SpeakerMia m6 : 2|2@1+ (1,0) [0|3] ""  NF_Controller
 SG_ BATT_07_Placeholder19 m6 : 0|2@1+ (1,0) [0|3] ""  NF_Controller
 SG_ BATT_07_Placeholder18 m6 : 14|2@1+ (1,0) [0|3] ""  NF_Controller
 SG_ BATT_07_Placeholder17 m6 : 12|2@1+ (1,0) [0|3] ""  NF_Controller
 SG_ BATT_07_Placeholder04 m6 : 34|2@1+ (1,0) [0|3] ""  NF_Controller
 SG_ BATT_07_Placeholder03 m6 : 32|2@1+ (1,0) [0|3] ""  NF_Controller
 SG_ BATT_08_Placeholder16 m7 : 10|2@1+ (1,0) [0|3] ""  NF_Controller
 SG_ BATT_08_Placeholder15 m7 : 8|2@1+ (1,0) [0|3] ""  NF_Controller
 SG_ BATT_08_Placeholder14 m7 : 22|2@1+ (1,0) [0|3] ""  NF_Controller
 SG_ BATT_08_Placeholder13 m7 : 20|2@1+ (1,0) [0|3] ""  NF_Controller
 SG_ BATT_08_Placeholder02 m7 : 46|2@1+ (1,0) [0|3] ""  NF_Controller
 SG_ BATT_08_Placeholder01 m7 : 44|2@1+ (1,0) [0|3] ""  NF_Controller
 SG_ BATT_08_Placeholder12 m7 : 18|2@1+ (1,0) [0|3] ""  NF_Controller
 SG_ BATT_08_Placeholder11 m7 : 16|2@1+ (1,0) [0|3] ""  NF_Controller
 SG_ BATT_08_Placeholder10 m7 : 30|2@1+ (1,0) [0|3] ""  NF_Controller
 SG_ BATT_08_Placeholder09 m7 : 28|2@1+ (1,0) [0|3] ""  NF_Controller
 SG_ BATT_08_Placeholder08 m7 : 26|2@1+ (1,0) [0|3] ""  NF_Controller
 SG_ BATT_08_Placeholder07 m7 : 24|2@1+ (1,0) [0|3] ""  NF_Controller
 SG_ BATT_08_Placeholder06 m7 : 38|2@1+ (1,0) [0|3] ""  NF_Controller
 SG_ BATT_08_Placeholder05 m7 : 36|2@1+ (1,0) [0|3] ""  NF_Controller
 SG_ BATT_08_SpeakerMia m7 : 2|2@1+ (1,0) [0|3] ""  NF_Controller
 SG_ BATT_08_Placeholder19 m7 : 0|2@1+ (1,0) [0|3] ""  NF_Controller
 SG_ BATT_08_Placeholder18 m7 : 14|2@1+ (1,0) [0|3] ""  NF_Controller
 SG_ BATT_08_Placeholder17 m7 : 12|2@1+ (1,0) [0|3] ""  NF_Controller
 SG_ BATT_08_Placeholder04 m7 : 34|2@1+ (1,0) [0|3] ""  NF_Controller
 SG_ BATT_08_Placeholder03 m7 : 32|2@1+ (1,0) [0|3] ""  NF_Controller
 SG_ BATT_09_Placeholder16 m8 : 10|2@1+ (1,0) [0|3] ""  NF_Controller
 SG_ BATT_09_Placeholder15 m8 : 8|2@1+ (1,0) [0|3] ""  NF_Controller
 SG_ BATT_09_Placeholder14 m8 : 22|2@1+ (1,0) [0|3] ""  NF_Controller
 SG_ BATT_09_Placeholder13 m8 : 20|2@1+ (1,0) [0|3] ""  NF_Controller
 SG_ BATT_09_Placeholder02 m8 : 46|2@1+ (1,0) [0|3] ""  NF_Controller
 SG_ BATT_09_Placeholder01 m8 : 44|2@1+ (1,0) [0|3] ""  NF_Controller
 SG_ BATT_09_Placeholder12 m8 : 18|2@1+ (1,0) [0|3] ""  NF_Controller
 SG_ BATT_09_Placeholder11 m8 : 16|2@1+ (1,0) [0|3] ""  NF_Controller
 SG_ BATT_09_Placeholder10 m8 : 30|2@1+ (1,0) [0|3] ""  NF_Controller
 SG_ BATT_09_Placeholder09 m8 : 28|2@1+ (1,0) [0|3] ""  NF_Controller
 SG_ BATT_09_Placeholder08 m8 : 26|2@1+ (1,0) [0|3] ""  NF_Controller
 SG_ BATT_09_Placeholder07 m8 : 24|2@1+ (1,0) [0|3] ""  NF_Controller
 SG_ BATT_09_Placeholder06 m8 : 38|2@1+ (1,0) [0|3] ""  NF_Controller
 SG_ BATT_09_Placeholder05 m8 : 36|2@1+ (1,0) [0|3] ""  NF_Controller
 SG_ BATT_09_SpeakerMia m8 : 2|2@1+ (1,0) [0|3] ""  NF_Controller
 SG_ BATT_09_Placeholder19 m8 : 0|2@1+ (1,0) [0|3] ""  NF_Controller
 SG_ BATT_09_Placeholder18 m8 : 14|2@1+ (1,0) [0|3] ""  NF_Controller
 SG_ BATT_09_Placeholder17 m8 : 12|2@1+ (1,0) [0|3] ""  NF_Controller
 SG_ BATT_09_Placeholder04 m8 : 34|2@1+ (1,0) [0|3] ""  NF_Controller
 SG_ BATT_09_Placeholder03 m8 : 32|2@1+ (1,0) [0|3] ""  NF_Controller
 SG_ BATT_10_Placeholder16 m9 : 10|2@1+ (1,0) [0|3] ""  NF_Controller
 SG_ BATT_10_Placeholder15 m9 : 8|2@1+ (1,0) [0|3] ""  NF_Controller
 SG_ BATT_10_Placeholder14 m9 : 22|2@1+ (1,0) [0|3] ""  NF_Controller
 SG_ BATT_10_Placeholder13 m9 : 20|2@1+ (1,0) [0|3] ""  NF_Controller
 SG_ BATT_10_Placeholder02 m9 : 46|2@1+ (1,0) [0|3] ""  NF_Controller
 SG_ BATT_10_Placeholder01 m9 : 44|2@1+ (1,0) [0|3] ""  NF_Controller
 SG_ BATT_10_Placeholder12 m9 : 18|2@1+ (1,0) [0|3] ""  NF_Controller
 SG_ BATT_10_Placeholder11 m9 : 16|2@1+ (1,0) [0|3] ""  NF_Controller
 SG_ BATT_10_Placeholder10 m9 : 30|2@1+ (1,0) [0|3] ""  NF_Controller
 SG_ BATT_10_Placeholder09 m9 : 28|2@1+ (1,0) [0|3] ""  NF_Controller
 SG_ BATT_10_Placeholder08 m9 : 26|2@1+ (1,0) [0|3] ""  NF_Controller
 SG_ BATT_10_Placeholder07 m9 : 24|2@1+ (1,0) [0|3] ""  NF_Controller
 SG_ BATT_10_Placeholder06 m9 : 38|2@1+ (1,0) [0|3] ""  NF_Controller
 SG_ BATT_10_Placeholder05 m9 : 36|2@1+ (1,0) [0|3] ""  NF_Controller
 SG_ BATT_10_SpeakerMia m9 : 2|2@1+ (1,0) [0|3] ""  NF_Controller
 SG_ BATT_10_Placeholder19 m9 : 0|2@1+ (1,0) [0|3] ""  NF_Controller
 SG_ BATT_10_Placeholder18 m9 : 14|2@1+ (1,0) [0|3] ""  NF_Controller
 SG_ BATT_10_Placeholder17 m9 : 12|2@1+ (1,0) [0|3] ""  NF_Controller
 SG_ BATT_10_Placeholder04 m9 : 34|2@1+ (1,0) [0|3] ""  NF_Controller
 SG_ BATT_10_Placeholder03 m9 : 32|2@1+ (1,0) [0|3] ""  NF_Controller
 SG_ BATT_11_Placeholder16 m10 : 10|2@1+ (1,0) [0|3] ""  NF_Controller
 SG_ BATT_11_Placeholder15 m10 : 8|2@1+ (1,0) [0|3] ""  NF_Controller
 SG_ BATT_11_Placeholder14 m10 : 22|2@1+ (1,0) [0|3] ""  NF_Controller
 SG_ BATT_11_Placeholder13 m10 : 20|2@1+ (1,0) [0|3] ""  NF_Controller
 SG_ BATT_11_Placeholder02 m10 : 46|2@1+ (1,0) [0|3] ""  NF_Controller
 SG_ BATT_11_Placeholder01 m10 : 44|2@1+ (1,0) [0|3] ""  NF_Controller
 SG_ BATT_11_Placeholder12 m10 : 18|2@1+ (1,0) [0|3] ""  NF_Controller
 SG_ BATT_11_Placeholder11 m10 : 16|2@1+ (1,0) [0|3] ""  NF_Controller
 SG_ BATT_11_Placeholder10 m10 : 30|2@1+ (1,0) [0|3] ""  NF_Controller
 SG_ BATT_11_Placeholder09 m10 : 28|2@1+ (1,0) [0|3] ""  NF_Controller
 SG_ BATT_11_Placeholder08 m10 : 26|2@1+ (1,0) [0|3] ""  NF_Controller
 SG_ BATT_11_Placeholder07 m10 : 24|2@1+ (1,0) [0|3] ""  NF_Controller
 SG_ BATT_11_Placeholder06 m10 : 38|2@1+ (1,0) [0|3] ""  NF_Controller
 SG_ BATT_11_Placeholder05 m10 : 36|2@1+ (1,0) [0|3] ""  NF_Controller
 SG_ BATT_11_SpeakerMia m10 : 2|2@1+ (1,0) [0|3] ""  NF_Controller
 SG_ BATT_11_Placeholder19 m10 : 0|2@1+ (1,0) [0|3] ""  NF_Controller
 SG_ BATT_11_Placeholder18 m10 : 14|2@1+ (1,0) [0|3] ""  NF_Controller
 SG_ BATT_11_Placeholder17 m10 : 12|2@1+ (1,0) [0|3] ""  NF_Controller
 SG_ BATT_11_Placeholder04 m10 : 34|2@1+ (1,0) [0|3] ""  NF_Controller
 SG_ BATT_11_Placeholder03 m10 : 32|2@1+ (1,0) [0|3] ""  NF_Controller
 SG_ BATT_12_Placeholder16 m11 : 10|2@1+ (1,0) [0|3] ""  NF_Controller
 SG_ BATT_12_Placeholder15 m11 : 8|2@1+ (1,0) [0|3] ""  NF_Controller
 SG_ BATT_12_Placeholder14 m11 : 22|2@1+ (1,0) [0|3] ""  NF_Controller
 SG_ BATT_12_Placeholder13 m11 : 20|2@1+ (1,0) [0|3] ""  NF_Controller
 SG_ BATT_12_Placeholder02 m11 : 46|2@1+ (1,0) [0|3] ""  NF_Controller
 SG_ BATT_12_Placeholder01 m11 : 44|2@1+ (1,0) [0|3] ""  NF_Controller
 SG_ BATT_12_Placeholder12 m11 : 18|2@1+ (1,0) [0|3] ""  NF_Controller
 SG_ BATT_12_Placeholder11 m11 : 16|2@1+ (1,0) [0|3] ""  NF_Controller
 SG_ BATT_12_Placeholder10 m11 : 30|2@1+ (1,0) [0|3] ""  NF_Controller
 SG_ BATT_12_Placeholder09 m11 : 28|2@1+ (1,0) [0|3] ""  NF_Controller
 SG_ BATT_12_Placeholder08 m11 : 26|2@1+ (1,0) [0|3] ""  NF_Controller
 SG_ BATT_12_Placeholder07 m11 : 24|2@1+ (1,0) [0|3] ""  NF_Controller
 SG_ BATT_12_Placeholder06 m11 : 38|2@1+ (1,0) [0|3] ""  NF_Controller
 SG_ BATT_12_Placeholder05 m11 : 36|2@1+ (1,0) [0|3] ""  NF_Controller
 SG_ BATT_12_SpeakerMia m11 : 2|2@1+ (1,0) [0|3] ""  NF_Controller
 SG_ BATT_12_Placeholder19 m11 : 0|2@1+ (1,0) [0|3] ""  NF_Controller
 SG_ BATT_12_Placeholder18 m11 : 14|2@1+ (1,0) [0|3] ""  NF_Controller
 SG_ BATT_12_Placeholder17 m11 : 12|2@1+ (1,0) [0|3] ""  NF_Controller
 SG_ BATT_12_Placeholder04 m11 : 34|2@1+ (1,0) [0|3] ""  NF_Controller
 SG_ BATT_12_Placeholder03 m11 : 32|2@1+ (1,0) [0|3] ""  NF_Controller
 SG_ BATT_13_Placeholder16 m12 : 10|2@1+ (1,0) [0|3] ""  NF_Controller
 SG_ BATT_13_Placeholder15 m12 : 8|2@1+ (1,0) [0|3] ""  NF_Controller
 SG_ BATT_13_Placeholder14 m12 : 22|2@1+ (1,0) [0|3] ""  NF_Controller
 SG_ BATT_13_Placeholder13 m12 : 20|2@1+ (1,0) [0|3] ""  NF_Controller
 SG_ BATT_13_Placeholder02 m12 : 46|2@1+ (1,0) [0|3] ""  NF_Controller
 SG_ BATT_13_Placeholder01 m12 : 44|2@1+ (1,0) [0|3] ""  NF_Controller
 SG_ BATT_13_Placeholder12 m12 : 18|2@1+ (1,0) [0|3] ""  NF_Controller
 SG_ BATT_13_Placeholder11 m12 : 16|2@1+ (1,0) [0|3] ""  NF_Controller
 SG_ BATT_13_Placeholder10 m12 : 30|2@1+ (1,0) [0|3] ""  NF_Controller
 SG_ BATT_13_Placeholder09 m12 : 28|2@1+ (1,0) [0|3] ""  NF_Controller
 SG_ BATT_13_Placeholder08 m12 : 26|2@1+ (1,0) [0|3] ""  NF_Controller
 SG_ BATT_13_Placeholder07 m12 : 24|2@1+ (1,0) [0|3] ""  NF_Controller
 SG_ BATT_13_Placeholder06 m12 : 38|2@1+ (1,0) [0|3] ""  NF_Controller
 SG_ BATT_13_Placeholder05 m12 : 36|2@1+ (1,0) [0|3] ""  NF_Controller
 SG_ BATT_13_SpeakerMia m12 : 2|2@1+ (1,0) [0|3] ""  NF_Controller
 SG_ BATT_13_Placeholder19 m12 : 0|2@1+ (1,0) [0|3] ""  NF_Controller
 SG_ BATT_13_Placeholder18 m12 : 14|2@1+ (1,0) [0|3] ""  NF_Controller
 SG_ BATT_13_Placeholder17 m12 : 12|2@1+ (1,0) [0|3] ""  NF_Controller
 SG_ BATT_13_Placeholder04 m12 : 34|2@1+ (1,0) [0|3] ""  NF_Controller
 SG_ BATT_13_Placeholder03 m12 : 32|2@1+ (1,0) [0|3] ""  NF_Controller
 SG_ BATT_14_Placeholder16 m13 : 10|2@1+ (1,0) [0|3] ""  NF_Controller
 SG_ BATT_14_Placeholder15 m13 : 8|2@1+ (1,0) [0|3] ""  NF_Controller
 SG_ BATT_14_Placeholder14 m13 : 22|2@1+ (1,0) [0|3] ""  NF_Controller
 SG_ BATT_14_Placeholder13 m13 : 20|2@1+ (1,0) [0|3] ""  NF_Controller
 SG_ BATT_14_Placeholder02 m13 : 46|2@1+ (1,0) [0|3] ""  NF_Controller
 SG_ BATT_14_Placeholder01 m13 : 44|2@1+ (1,0) [0|3] ""  NF_Controller
 SG_ BATT_14_Placeholder12 m13 : 18|2@1+ (1,0) [0|3] ""  NF_Controller
 SG_ BATT_14_Placeholder11 m13 : 16|2@1+ (1,0) [0|3] ""  NF_Controller
 SG_ BATT_14_Placeholder10 m13 : 30|2@1+ (1,0) [0|3] ""  NF_Controller
 SG_ BATT_14_Placeholder09 m13 : 28|2@1+ (1,0) [0|3] ""  NF_Controller
 SG_ BATT_14_Placeholder08 m13 : 26|2@1+ (1,0) [0|3] ""  NF_Controller
 SG_ BATT_14_Placeholder07 m13 : 24|2@1+ (1,0) [0|3] ""  NF_Controller
 SG_ BATT_14_Placeholder06 m13 : 38|2@1+ (1,0) [0|3] ""  NF_Controller
 SG_ BATT_14_Placeholder05 m13 : 36|2@1+ (1,0) [0|3] ""  NF_Controller
 SG_ BATT_14_SpeakerMia m13 : 2|2@1+ (1,0) [0|3] ""  NF_Controller
 SG_ BATT_14_Placeholder19 m13 : 0|2@1+ (1,0) [0|3] ""  NF_Controller
 SG_ BATT_14_Placeholder18 m13 : 14|2@1+ (1,0) [0|3] ""  NF_Controller
 SG_ BATT_14_Placeholder17 m13 : 12|2@1+ (1,0) [0|3] ""  NF_Controller
 SG_ BATT_14_Placeholder04 m13 : 34|2@1+ (1,0) [0|3] ""  NF_Controller
 SG_ BATT_14_Placeholder03 m13 : 32|2@1+ (1,0) [0|3] ""  NF_Controller
 SG_ BATT_15_Placeholder16 m14 : 10|2@1+ (1,0) [0|3] ""  NF_Controller
 SG_ BATT_15_Placeholder15 m14 : 8|2@1+ (1,0) [0|3] ""  NF_Controller
 SG_ BATT_15_Placeholder14 m14 : 22|2@1+ (1,0) [0|3] ""  NF_Controller
 SG_ BATT_15_Placeholder13 m14 : 20|2@1+ (1,0) [0|3] ""  NF_Controller
 SG_ BATT_15_Placeholder02 m14 : 46|2@1+ (1,0) [0|3] ""  NF_Controller
 SG_ BATT_15_Placeholder01 m14 : 44|2@1+ (1,0) [0|3] ""  NF_Controller
 SG_ BATT_15_Placeholder12 m14 : 18|2@1+ (1,0) [0|3] ""  NF_Controller
 SG_ BATT_15_Placeholder11 m14 : 16|2@1+ (1,0) [0|3] ""  NF_Controller
 SG_ BATT_15_Placeholder10 m14 : 30|2@1+ (1,0) [0|3] ""  NF_Controller
 SG_ BATT_15_Placeholder09 m14 : 28|2@1+ (1,0) [0|3] ""  NF_Controller
 SG_ BATT_15_Placeholder08 m14 : 26|2@1+ (1,0) [0|3] ""  NF_Controller
 SG_ BATT_15_Placeholder07 m14 : 24|2@1+ (1,0) [0|3] ""  NF_Controller
 SG_ BATT_15_Placeholder06 m14 : 38|2@1+ (1,0) [0|3] ""  NF_Controller
 SG_ BATT_15_Placeholder05 m14 : 36|2@1+ (1,0) [0|3] ""  NF_Controller
 SG_ BATT_15_SpeakerMia m14 : 2|2@1+ (1,0) [0|3] ""  NF_Controller
 SG_ BATT_15_Placeholder19 m14 : 0|2@1+ (1,0) [0|3] ""  NF_Controller
 SG_ BATT_15_Placeholder18 m14 : 14|2@1+ (1,0) [0|3] ""  NF_Controller
 SG_ BATT_15_Placeholder17 m14 : 12|2@1+ (1,0) [0|3] ""  NF_Controller
 SG_ BATT_15_Placeholder04 m14 : 34|2@1+ (1,0) [0|3] ""  NF_Controller
 SG_ BATT_15_Placeholder03 m14 : 32|2@1+ (1,0) [0|3] ""  NF_Controller
 SG_ multiplexor_batt_diag_D M : 4|4@1+ (1,0) [0|15] ""  NF_Controller
 SG_ BATT_Limit_ChrgrVolt_V : 38|2@1+ (1,0) [0|3] ""  NF_Controller
 SG_ BATT_Limit_ChrgrCrrnt_V : 36|2@1+ (1,0) [0|3] ""  NF_Controller
 SG_ BATT_State_Chrgr : 34|2@1+ (1,0) [0|3] ""  NF_Controller
 SG_ BATT_State_ChrgrIntrlck : 32|2@1+ (1,0) [0|3] ""  NF_Controller
 SG_ BATT_Limit_ChrgrVolt : 16|11@1+ (1,0) [0|2047] "Volts"  NF_Controller
 SG_ BATT_Limit_ChrgrCrrnt : 0|16@1+ (0.5,0) [0|16000] "Amps"  NF_Controller
 SG_ BATT_IsoRes_Min_StrId : 56|5@1+ (1,101) [101|124] "Index"  NF_Controller
 SG_ BATT_IsoRes_Min : 40|16@1+ (10,0) [0|655330] "kOhms"  NF_Controller
 SG_ BATT_IsoRes_Max_StrId : 32|5@1+ (1,101) [101|124] "Index"  NF_Controller
 SG_ BATT_IsoRes_Max : 16|16@1+ (10,0) [0|655330] "kOhms"  NF_Controller
 SG_ BATT_IsoRes_Last : 0|16@1+ (10,0) [0|655330] "kOhms"  NF_Controller
 SG_ BATT_Cnc_Volt_Cell_Avg_V : 62|2@1+ (1,0) [0|3] ""  NF_Controller
 SG_ BATT_Cnc_Volt_Cell_Avg : 48|10@1+ (0.005,0) [0|5.115] "Volts"  NF_Controller
 SG_ BATT_Cnc_Volt_Cell_Max_VtbId : 15|4@1+ (1,1) [0|16] "Index"  NF_Controller
 SG_ BATT_Cnc_Volt_Cell_Max_V : 58|2@1+ (1,0) [0|3] ""  NF_Controller
 SG_ BATT_Cnc_Volt_Cell_Max_StrId : 10|5@1+ (1,101) [101|124] "Index"  NF_Controller
 SG_ BATT_Cnc_Volt_Cell_Max_CellId : 19|5@1+ (1,0) [0|31] "Index"  NF_Controller
 SG_ BATT_Cnc_Volt_Cell_Max : 0|10@1+ (0.005,0) [0|5.115] "Volts"  NF_Controller
 SG_ BATT_Cnc_Volt_Cell_Min_V : 60|2@1+ (1,0) [0|3] ""  NF_Controller
 SG_ BATT_Cnc_Volt_Cell_Min : 24|10@1+ (0.005,0) [0|5.115] "Volts"  NF_Controller
 SG_ BATT_Cnc_Volt_Cell_Min_VtbId : 39|4@1+ (1,1) [0|16] "Index"  NF_Controller
 SG_ BATT_Cnc_Volt_Cell_Min_StrId : 34|5@1+ (1,101) [101|124] "Index"  NF_Controller
 SG_ BATT_Cnc_Volt_Cell_Min_CellId : 43|5@1+ (1,0) [0|31] "Index"  NF_Controller
 SG_ BATT_HVIL_State : 0|2@1+ (1,0) [0|3] ""  NF_Controller
 SG_ BATT_HVIL_SinkVolt_V : 21|2@1+ (1,0) [0|3] ""  NF_Controller
 SG_ BATT_HVIL_SourceVolt_V : 13|2@1+ (1,0) [0|3] ""  NF_Controller
 SG_ BATT_HVIL_SinkCrrnt : 24|6@1+ (1,0) [0|50] "mA"  NF_Controller
 SG_ BATT_HVIL_SourceVolt : 8|5@1+ (1,0) [0|29] "Volts"  NF_Controller
 SG_ BATT_HVIL_SinkVolt : 16|5@1+ (1,0) [0|29] "Volts"  NF_Controller
 SG_ BATT_Cnc_Temp_Module_Avg_V : 56|2@1+ (1,0) [0|3] ""  NF_Controller
 SG_ BATT_Cnc_Temp_Module_Avg : 48|8@1+ (1,-40) [-40|200] "Degree C"  NF_Controller
 SG_ BATT_Cnc_Temp_Module_Max : 0|8@1+ (1,-40) [-40|200] "Degree C"  NF_Controller
 SG_ BATT_Cnc_Temp_Module_Max_StrId : 8|5@1+ (1,101) [101|124] "Index"  NF_Controller
 SG_ BATT_Cnc_Temp_Module_Max_SubId : 18|3@1+ (1,0) [1|4] "Index"  NF_Controller
 SG_ BATT_Cnc_Temp_Module_Min : 24|8@1+ (1,-40) [-40|200] "Degree C"  NF_Controller
 SG_ BATT_Cnc_Temp_Module_Min_VtbId : 37|5@1+ (1,0) [0|29] "Index"  NF_Controller
 SG_ BATT_Cnc_Temp_Module_Min_SubId : 42|3@1+ (1,0) [1|4] "Index"  NF_Controller
 SG_ BATT_Cnc_Temp_Module_Max_V : 21|2@1+ (1,0) [0|3] ""  NF_Controller
 SG_ BATT_Cnc_Temp_Module_Min_V : 45|2@1+ (1,0) [0|3] ""  NF_Controller
 SG_ BATT_Cnc_Temp_Module_Max_VtbId : 13|5@1+ (1,0) [0|29] "Index"  NF_Controller
 SG_ BATT_Cnc_Temp_Module_Min_StrId : 32|5@1+ (1,101) [101|124] "Index"  NF_Controller
 SG_ BATT_Cnc_Volt_String_Avg_V : 51|2@1+ (1,0) [0|3] ""  NF_Controller
 SG_ BATT_Cnc_Volt_String_Avg : 40|11@1+ (1,0) [0|1250] "Volts"  NF_Controller
 SG_ BATT_Cnc_Volt_String_Min_V : 34|2@1+ (1,0) [0|3] ""  NF_Controller
 SG_ BATT_Cnc_Volt_String_Min_StrId : 27|5@1+ (1,101) [101|124] "Index"  NF_Controller
 SG_ BATT_Cnc_Volt_String_Min : 16|11@1+ (1,0) [0|1250] "Volts"  NF_Controller
 SG_ BATT_Cnc_Volt_String_Max : 0|11@1+ (1,0) [0|1250] "Volts"  NF_Controller
 SG_ BATT_Cnc_Volt_String_Max_V : 32|2@1+ (1,0) [0|3] ""  NF_Controller
 SG_ BATT_Cnc_Volt_String_Max_StrId : 11|5@1+ (1,101) [101|124] "Index"  NF_Controller
 SG_ BATT_Sys_SOHC_Module_Min_VtbId : 40|5@1+ (1,0) [0|29] "Index"  NF_Controller
 SG_ BATT_Sys_SOHC_Module_Min_V : 45|2@1+ (1,0) [0|3] ""  NF_Controller
 SG_ BATT_Sys_SOHC_Module_Min_StrId : 34|5@1+ (1,101) [101|124] "Index"  NF_Controller
 SG_ BATT_Sys_SOHC_Module_Min : 24|10@1+ (0.1,0) [0|100] "%"  NF_Controller
 SG_ BATT_Sys_SOHC_Module_Max_VtbId : 16|5@1+ (1,0) [0|29] "Index"  NF_Controller
 SG_ BATT_Sys_SOHC_Module_Max_V : 21|2@1+ (1,0) [0|3] ""  NF_Controller
 SG_ BATT_Sys_SOHC_Module_Max_StrId : 10|5@1+ (1,101) [101|124] "Index"  NF_Controller
 SG_ BATT_Sys_SOHC_Module_Max : 0|10@1+ (0.1,0) [0|100] "%"  NF_Controller
 SG_ BATT_Sys_SOHC_Module_Avg_V : 58|2@1+ (1,0) [0|3] ""  NF_Controller
 SG_ BATT_Sys_SOHC_Module_Avg : 48|10@1+ (0.1,0) [0|100] "%"  NF_Controller
 SG_ BATT_Sys_SOHR_Module_Min_VtbId : 40|5@1+ (1,0) [0|29] "Index"  NF_Controller
 SG_ BATT_Sys_SOHR_Module_Min_V : 45|2@1+ (1,0) [0|3] ""  NF_Controller
 SG_ BATT_Sys_SOHR_Module_Min_StrId : 34|5@1+ (1,101) [101|124] "Index"  NF_Controller
 SG_ BATT_Sys_SOHR_Module_Min : 24|10@1+ (0.1,0) [0|100] "%"  NF_Controller
 SG_ BATT_Sys_SOHR_Module_Max_VtbId : 16|5@1+ (1,0) [0|29] "Index"  NF_Controller
 SG_ BATT_Sys_SOHR_Module_Max_V : 21|2@1+ (1,0) [0|3] ""  NF_Controller
 SG_ BATT_Sys_SOHR_Module_Max_StrId : 10|5@1+ (1,101) [101|124] "Index"  NF_Controller
 SG_ BATT_Sys_SOHR_Module_Max : 0|10@1+ (0.1,0) [0|100] "%"  NF_Controller
 SG_ BATT_Sys_SOHR_Module_Avg_V : 58|2@1+ (1,0) [0|3] ""  NF_Controller
 SG_ BATT_Sys_SOHR_Module_Avg : 48|10@1+ (0.1,0) [0|100] "%"  NF_Controller
 SG_ BATT_Limit_RegenCrrnt_V : 30|2@1+ (1,0) [0|3] ""  NF_Controller
 SG_ BATT_Limit_RegenPwr_V : 46|2@1+ (1,0) [0|3] ""  NF_Controller
 SG_ BATT_Limit_RegenPwr_LongTerm : 48|12@1+ (1,0) [0|4095] "KW"  NF_Controller
 SG_ BATT_Limit_RegenPwr_MidTerm : 32|12@1+ (1,0) [0|4095] "KW"  NF_Controller
 SG_ BATT_Limit_RegenPwr_ShortTerm : 16|12@1+ (1,0) [0|4095] "KW"  NF_Controller
 SG_ BATT_Limit_RegenCrrnt : 0|16@1+ (0.5,0) [0|16000] "Amps"  NF_Controller
 SG_ BATT_Limit_DschrgCrrnt_V : 30|2@1+ (1,0) [0|3] ""  NF_Controller
 SG_ BATT_Limit_DschrgPwr_V : 46|2@1+ (1,0) [0|3] ""  NF_Controller
 SG_ BATT_Limit_DschrgCrrnt : 0|16@1+ (0.5,0) [0|16000] "Amps"  NF_Controller
 SG_ BATT_Limit_DschrgPwr_LongTerm : 48|12@1+ (1,0) [0|4095] "KW"  NF_Controller
 SG_ BATT_Limit_DschrgPwr_ShortTerm : 16|12@1+ (1,0) [0|4095] "KW"  NF_Controller
 SG_ BATT_Limit_DschrgPwr_MidTerm : 32|12@1+ (1,0) [0|4095] "KW"  NF_Controller
 SG_ BATT_Sys_Temp_Module_Avg_V : 56|2@1+ (1,0) [0|3] ""  NF_Controller
 SG_ BATT_Sys_Temp_Module_Avg : 48|8@1+ (1,-40) [-40|200] "Degree C"  NF_Controller
 SG_ BATT_Sys_Temp_Module_Max : 0|8@1+ (1,-40) [-40|200] "Degree C"  NF_Controller
 SG_ BATT_Sys_Temp_Module_Max_StrId : 8|5@1+ (1,101) [101|124] "Index"  NF_Controller
 SG_ BATT_Sys_Temp_Module_Max_SubId : 18|3@1+ (1,0) [1|4] "Index"  NF_Controller
 SG_ BATT_Sys_Temp_Module_Min : 24|8@1+ (1,-40) [-40|200] "Degree C"  NF_Controller
 SG_ BATT_Sys_Temp_Module_Min_VtbId : 37|5@1+ (1,0) [0|29] "Index"  NF_Controller
 SG_ BATT_Sys_Temp_Module_Min_SubId : 42|3@1+ (1,0) [1|4] "Index"  NF_Controller
 SG_ BATT_Sys_Temp_Module_Max_V : 60|2@1+ (1,0) [0|3] ""  NF_Controller
 SG_ BATT_Sys_Temp_Module_Min_V : 58|2@1+ (1,0) [0|3] ""  NF_Controller
 SG_ BATT_Sys_Temp_Module_Max_VtbId : 13|5@1+ (1,0) [0|29] "Index"  NF_Controller
 SG_ BATT_Sys_Temp_Module_Min_StrId : 32|5@1+ (1,101) [101|124] "Index"  NF_Controller
 SG_ BATT_Sys_SOC_String_Min_V : 58|2@1+ (1,0) [0|3] ""  NF_Controller
 SG_ BATT_Sys_SOC_String_Max_V : 56|2@1+ (1,0) [0|3] ""  NF_Controller
 SG_ BATT_Sys_SOC_String_Avg_V : 21|2@1+ (1,0) [0|3] ""  NF_Controller
 SG_ BATT_Sys_Energy_System_V : 37|2@1+ (1,0) [0|3] ""  NF_Controller
 SG_ BATT_Sys_Energy_System : 40|16@1+ (0.01,0) [0|655.35] "KWh"  NF_Controller
 SG_ BATT_Sys_SOC_String_Avg : 0|8@1+ (0.4,0) [0|100] "%"  NF_Controller
 SG_ BATT_Sys_SOC_String_Max : 24|8@1+ (0.4,0) [0|100] "%"  NF_Controller
 SG_ BATT_Sys_SOC_String_Max_StrId : 32|5@1+ (1,101) [101|124] "Index"  NF_Controller
 SG_ BATT_Sys_SOC_String_Min : 8|8@1+ (0.4,0) [0|100] "%"  NF_Controller
 SG_ BATT_Sys_SOC_String_Min_StrId : 16|5@1+ (1,101) [101|124] "Index"  NF_Controller
 SG_ BATT_Sys_Volt_Cell_Avg_V : 62|2@1+ (1,0) [0|3] ""  NF_Controller
 SG_ BATT_Sys_Volt_Cell_Avg : 48|10@1+ (0.005,0) [0|5.115] "Volts"  NF_Controller
 SG_ BATT_Sys_Volt_Cell_Max_VtbId : 15|4@1+ (1,0) [0|15] "Index"  NF_Controller
 SG_ BATT_Sys_Volt_Cell_Max_V : 58|2@1+ (1,0) [0|3] ""  NF_Controller
 SG_ BATT_Sys_Volt_Cell_Max_StrId : 10|5@1+ (1,101) [101|124] "Index"  NF_Controller
 SG_ BATT_Sys_Volt_Cell_Max_CellId : 19|5@1+ (1,0) [0|31] "Index"  NF_Controller
 SG_ BATT_Sys_Volt_Cell_Max : 0|10@1+ (0.005,0) [0|5.115] "Volts"  NF_Controller
 SG_ BATT_Sys_Volt_Cell_Min_V : 60|2@1+ (1,0) [0|3] ""  NF_Controller
 SG_ BATT_Sys_Volt_Cell_Min : 24|10@1+ (0.005,0) [0|5.115] "Volts"  NF_Controller
 SG_ BATT_Sys_Volt_Cell_Min_VtbId : 39|4@1+ (1,0) [0|31] "Index"  NF_Controller
 SG_ BATT_Sys_Volt_Cell_Min_StrId : 34|5@1+ (1,101) [101|124] "Index"  NF_Controller
 SG_ BATT_Sys_Volt_Cell_Min_CellId : 43|5@1+ (1,0) [0|31] "Index"  NF_Controller
 SG_ BATT_Sys_Volt_String_Avg_V : 51|2@1+ (1,0) [0|3] ""  NF_Controller
 SG_ BATT_Sys_Volt_String_Avg : 40|11@1+ (1,0) [0|1250] "Volts"  NF_Controller
 SG_ BATT_Sys_Volt_String_Min_V : 34|2@1+ (1,0) [0|3] ""  NF_Controller
 SG_ BATT_Sys_Volt_String_Min_StrId : 27|5@1+ (1,101) [101|124] "Index"  NF_Controller
 SG_ BATT_Sys_Volt_String_Min : 16|11@1+ (1,0) [0|1250] "Volts"  NF_Controller
 SG_ BATT_Sys_Volt_String_Max : 0|11@1+ (1,0) [0|1250] "Volts"  NF_Controller
 SG_ BATT_Sys_Volt_String_Max_V : 32|2@1+ (1,0) [0|3] ""  NF_Controller
 SG_ BATT_Sys_Volt_String_Max_StrId : 11|5@1+ (1,101) [101|124] "Index"  NF_Controller
 SG_ BATT_Current_String_Min_V : 52|2@1+ (1,0) [0|3] ""  NF_Controller
 SG_ BATT_Current_String_Min_StrId : 42|5@1+ (1,101) [101|124] "Index"  NF_Controller
 SG_ BATT_Current_String_Min : 32|10@1+ (1,-500) [-500|500] "Amps"  NF_Controller
 SG_ BATT_Current_String_Max_V : 50|2@1+ (1,0) [0|3] ""  NF_Controller
 SG_ BATT_Current_String_Max_StrId : 26|5@1+ (1,101) [101|124] "Index"  NF_Controller
 SG_ BATT_Current_String_Max : 16|10@1+ (1,-500) [-500|500] "Amps"  NF_Controller
 SG_ BATT_Current_System : 0|16@1+ (0.5,-16000) [-16000|16000] "Amps"  NF_Controller
 SG_ BATT_Current_System_V : 48|2@1+ (1,0) [0|3] ""  NF_Controller

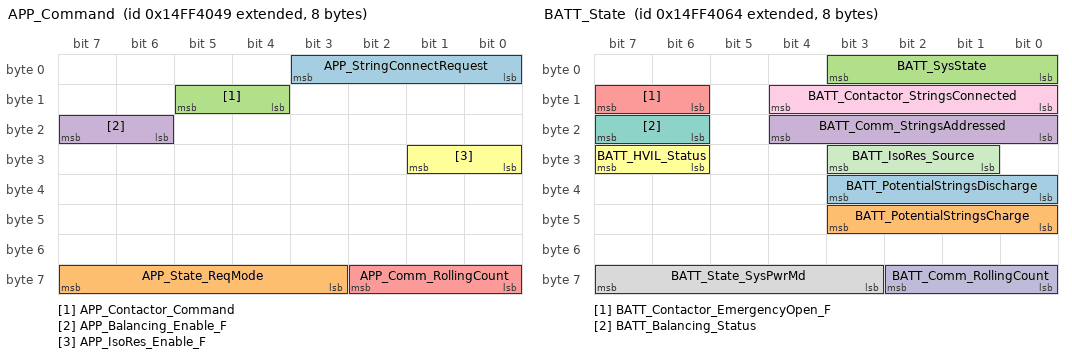
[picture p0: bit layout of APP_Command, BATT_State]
BO_ 2499756105 APP_Command: 8 NF_Controller
 SG_ APP_StringConnectRequest : 0|4@1+ (1,0) [0|15] ""  BMS_Controller
 SG_ APP_State_ReqMode : 59|5@1+ (1,0) [0|4] ""  BMS_Controller
 SG_ APP_Contactor_Command : 12|2@1+ (1,0) [0|3] ""  BMS_Controller
 SG_ APP_Balancing_Enable_F : 22|2@1+ (1,0) [0|3] ""  BMS_Controller
 SG_ APP_Comm_RollingCount : 56|3@1+ (1,0) [0|7] "Count"  BMS_Controller
 SG_ APP_IsoRes_Enable_F : 24|2@1+ (1,0) [0|3] ""  BMS_Controller

BO_ 2499756132 BATT_State: 8 BMS_Controller
 SG_ BATT_PotentialStringsDischarge : 32|4@1+ (1,0) [0|15] "" Vector__XXX
 SG_ BATT_PotentialStringsCharge : 40|4@1+ (1,0) [0|15] "" Vector__XXX
 SG_ BATT_SysState : 0|4@1+ (1,0) [0|15] "" Vector__XXX
 SG_ BATT_Comm_StringsAddressed : 16|5@1+ (1,0) [0|24] "Count"  NF_Controller
 SG_ BATT_Contactor_EmergencyOpen_F : 14|2@1+ (1,0) [0|3] ""  NF_Controller
 SG_ BATT_HVIL_Status : 30|2@1+ (1,0) [0|3] ""  NF_Controller
 SG_ BATT_Balancing_Status : 22|2@1+ (1,0) [0|3] ""  NF_Controller
 SG_ BATT_State_SysPwrMd : 59|5@1+ (1,0) [0|5] ""  NF_Controller
 SG_ BATT_Contactor_StringsConnected : 8|5@1+ (1,0) [0|24] "Count"  NF_Controller
 SG_ BATT_Comm_RollingCount : 56|3@1+ (1,0) [0|7] "Count"  NF_Controller
 SG_ BATT_IsoRes_Source : 25|3@1+ (1,0) [0|7] ""  NF_Controller

CM_ "Application CAN Version: 1908_01";
CM_ BO_ 2499756105 "This Message is the only message that is required for the XPAND System to operate. See individual signal comments and the Integration Guide.";
CM_ SG_ 2499756105 APP_State_ReqMode "A signal from the Application that requests that the Battery Management System enter Charge/Discharge Mode.
This only works if Contactor_Command is Close & APP_Comm_RollingCount is incrementing.
See Value Descriptions";
CM_ SG_ 2499756105 APP_Contactor_Command "A signal from the Application that requests that the Battery Management System closes contactors.
This only works if App_StateReqMode is Charge/Discharge & APP_Comm_RollingCount is incrementing.
See Value Descriptions";
CM_ SG_ 2499756105 APP_Balancing_Enable_F "Signal from the Application that communicates to the Battery Management System that Cell Balance (if neccessary) is allowed.
See Value Descriptions tab for more information.";
CM_ SG_ 2499756105 APP_Comm_RollingCount "An incrementing signal from the Application that the Battery Management System used to calculate freshness.
The Application should increment (with rollover) this signal every time it's message is transmitted to the Battery Management System.

";
CM_ SG_ 2499756105 APP_IsoRes_Enable_F "CURRENTLY NOT SUPPORTED.  Signal from the Application that communicates to the Battery Management System that Runtime Isolation Detection is allowed.
See Value Descriptions tab for more information.";
CM_ BO_ 2499756132 "These signals communicate the state of the Battery Management System.  Look here for an overal understanding of the state of the BMS.";
CM_ SG_ 2499756132 BATT_Comm_StringsAddressed "This signal communicates the number of strings addressed at initialization";
CM_ SG_ 2499756132 BATT_Contactor_EmergencyOpen_F "This signal communicates if there was a Battery Management Fault that necessitated the contactors opening immediately.  If this happens, there will be a Fault flag set in BATT_Diagnostics
";
CM_ SG_ 2499756132 BATT_HVIL_Status "This signal communicates the high level status of the HVIL.   See the Value Description";
CM_ SG_ 2499756132 BATT_Balancing_Status "This signal communicates if a string in the BMS is currently balancing. See the Value Description";
CM_ SG_ 2499756132 BATT_State_SysPwrMd "This signal communicates the overal state of the System. When in Partial Run or Run, one or more strings are connected to High Voltage.";
CM_ SG_ 2499756132 BATT_Contactor_StringsConnected "This signal communicates the number of strings connected to High Voltage at any given time.";
CM_ SG_ 2499756132 BATT_Comm_RollingCount "An ever incrementing signal that the Application can chose to monitor to ensure the BMS is sending fresh information with each message.";
CM_ SG_ 2499756132 BATT_IsoRes_Source "The results of the Isolation Test can be recovered from NVM or it can be from recently running the Isolation Test.  This signal communicates the source of the results.";
BA_DEF_  "NetworkSpeed" ENUM  "250kBit/s","500kBit/s","1000kBit/s";
BA_DEF_ SG_  "SigType" ENUM  "Default","Range","RangeSigned","ASCII","Discrete","Control","ReferencePGN","DTC","StringDelimiter","StringLength","StringLengthControl","MessageCounter","MessageChecksum";
BA_DEF_ SG_  "GenSigEVName" STRING ;
BA_DEF_ SG_  "GenSigILSupport" ENUM  "No","Yes";
BA_DEF_ SG_  "GenSigSendType" ENUM  "Cyclic","OnWrite","OnWriteWithRepetition","OnChange","OnChangeWithRepetition","IfActive","IfActiveWithRepetition","NoSigSendType";
BA_DEF_ SG_  "GenSigStartValue" INT 0 10000;
BA_DEF_ BO_  "GenMsgILSupport" ENUM  "No","Yes";
BA_DEF_ BU_  "NmStationAddress" INT 0 255;
BA_DEF_ BO_  "GenMsgSendType" ENUM  "cyclic","NotUsed","IfActive","NotUsed","NotUsed","NotUsed","NotUsed","NotUsed","noMsgSendType";
BA_DEF_ BO_  "GenMsgRequestable" INT 0 1;
BA_DEF_ BO_  "GenMsgCycleTime" INT 0 3600000;
BA_DEF_ SG_  "SPN" INT 0 524287;
BA_DEF_  "DBName" STRING ;
BA_DEF_  "BusType" STRING ;
BA_DEF_  "ProtocolType" STRING ;
BA_DEF_ BO_  "VFrameFormat" ENUM  "StandardCAN","ExtendedCAN","reserved","J1939PG";
BA_DEF_DEF_  "NetworkSpeed" "250kBit/s";
BA_DEF_DEF_  "SigType" "Default";
BA_DEF_DEF_  "GenSigEVName" "Env@Nodename_@Signame";
BA_DEF_DEF_  "GenSigILSupport" "Yes";
BA_DEF_DEF_  "GenSigSendType" "NoSigSendType";
BA_DEF_DEF_  "GenSigStartValue" 0;
BA_DEF_DEF_  "GenMsgILSupport" "Yes";
BA_DEF_DEF_  "NmStationAddress" 254;
BA_DEF_DEF_  "GenMsgSendType" "noMsgSendType";
BA_DEF_DEF_  "GenMsgRequestable" 1;
BA_DEF_DEF_  "GenMsgCycleTime" 0;
BA_DEF_DEF_  "SPN" 0;
BA_DEF_DEF_  "DBName" "";
BA_DEF_DEF_  "BusType" "CAN";
BA_DEF_DEF_  "ProtocolType" "J1939";
BA_DEF_DEF_  "VFrameFormat" "J1939PG";
BA_ "ProtocolType" "CAN";
BA_ "DBName" "NF_BMS_Application";
BA_ "GenMsgCycleTime" BO_ 2499756105 100;
BA_ "GenMsgSendType" BO_ 2499756105 0;
BA_ "GenSigStartValue" SG_ 2499756105 APP_StringConnectRequest 1;
BA_ "SPN" SG_ 2499756105 APP_State_ReqMode 2551;
BA_ "SPN" SG_ 2499756105 APP_Contactor_Command 2551;
BA_ "SPN" SG_ 2499756105 APP_Balancing_Enable_F 2551;
BA_ "SPN" SG_ 2499756105 APP_Comm_RollingCount 2551;
BA_ "SPN" SG_ 2499756105 APP_IsoRes_Enable_F 2551;
BA_ "GenMsgCycleTime" BO_ 2499756132 100;
BA_ "GenMsgSendType" BO_ 2499756132 0;
BA_ "SPN" SG_ 2499756132 BATT_Comm_StringsAddressed 2551;
BA_ "SPN" SG_ 2499756132 BATT_Contactor_EmergencyOpen_F 2551;
BA_ "SPN" SG_ 2499756132 BATT_Balancing_Status 2551;
BA_ "SPN" SG_ 2499756132 BATT_State_SysPwrMd 2551;
BA_ "SPN" SG_ 2499756132 BATT_Contactor_StringsConnected 2551;
BA_ "SPN" SG_ 2499756132 BATT_Comm_RollingCount 2551;
BA_ "SPN" SG_ 2499756132 BATT_IsoRes_Source 2551;
BA_ "NmStationAddress" BU_ BMS_Controller 100;
BA_ "NmStationAddress" BU_ NF_Controller 73;
VAL_ 2499756105 APP_State_ReqMode 3 "Discharge" 2 "Charge" 1 "Idle" 0 "Off" ;
VAL_ 2499756105 APP_Contactor_Command 3 "Error" 2 "SNA" 1 "Close" 0 "Open" ;
VAL_ 2499756105 APP_Balancing_Enable_F 0 "Balancing not allowed" 1 "Balancing allowed" 2 "SNA" 3 "Error" ;
VAL_ 2499756105 APP_IsoRes_Enable_F 3 "Error" 2 "SNA" 1 "Measurement enabled" 0 "Measurement disabled" ;
VAL_ 2499756132 BATT_SysState 13 "Cooldown" 12 "Disconnect" 11 "Charge" 10 "Drive" 9 "ExternalIsolationTestCharge" 8 "ExternalIsolationTestDrive" 7 "ConnectChargeStagger" 6 "ConnectChargeBusJoin" 5 "ConnectChargePrecharge" 4 "ConnectDriveStagger" 3 "ConnectDriveBusJoin" 2 "ConnectDrivePrecharge" 1 "StandByReady" 0 "StandByNotReady" ;
VAL_ 2499756132 BATT_Contactor_EmergencyOpen_F 3 "SNA" 2 "Status Not Available" 1 "Emergency Open Active" 0 "Emergency Open Not Active" ;
VAL_ 2499756132 BATT_HVIL_Status 3 "Error" 2 "SNA" 1 "Invalid" 0 "Valid" ;
VAL_ 2499756132 BATT_Balancing_Status 0 "Balancing not active" 1 "Balancing active" 2 "SNA" 3 "Error" ;
VAL_ 2499756132 BATT_State_SysPwrMd 5 "Sleep" 4 "Fault" 3 "Run" 2 "Partial Run" 1 "Idle" 0 "Initialize" ;
VAL_ 2499756132 BATT_IsoRes_Source 3 "Error (Invalid)" 2 "SNA (Invalid)" 1 "Source_ThisCycle" 0 "Source_NVM" ;
